[part 1 of 2: packages /CAN2/ISignalGroup to /CAN2/Cluster]
AUTOSAR XML (schema 4-3-0)
package /CAN2/ISignalGroup
  25 x i signal group:
    CAN2_SG_FD_APS1: i-signal=[CAN2_APS_Angle_Target, CAN2_APS_Rq_EPAS_Ctrl, CAN2_APS_Sta_System, CAN2_APS_V_Rq_EPAS_Ctrl], system-signal-group=CAN2_SG_FD_APS1
    CAN2_SG_FD_APS2: i-signal=[CAN2_APS_D_FLL, CAN2_APS_D_FLR, CAN2_APS_D_RLL, CAN2_APS_D_RLR, CAN2_APS_ExitCondition, CAN2_APS_HW_Ver, CAN2_APS_Progress_PCT, CAN2_APS_RQ_Display, CAN2_APS_SW_Ver, CAN2_FDC_VCU_RegenLimInd_Sta, CAN2_FDC_VCU_SmartEcoSpdLim_Sta, CAN2_FDC_VCU_SmartEco_Sta, CAN2_PAS_A_FCL, CAN2_PAS_A_FCR, CAN2_PAS_A_FML, CAN2_PAS_A_FMR, CAN2_PAS_A_RCL, CAN2_PAS_A_RCR, CAN2_PAS_A_RML, CAN2_PAS_A_RMR, CAN2_PAS_Chime, CAN2_PAS_D_FCL, CAN2_PAS_D_FCR, CAN2_PAS_D_FML, CAN2_PAS_D_FMR, CAN2_PAS_D_RCL, CAN2_PAS_D_RCR, CAN2_PAS_D_RML, CAN2_PAS_D_RMR, CAN2_PAS_Mod_Operation, CAN2_PAS_SNSR_Layout, CAN2_PAS_Sta_F_Sys, CAN2_USS_Sta_FCL, CAN2_USS_Sta_FCR, CAN2_USS_Sta_FLL, CAN2_USS_Sta_FLR, CAN2_USS_Sta_FML, CAN2_USS_Sta_FMR, CAN2_USS_Sta_RCL, CAN2_USS_Sta_RCR, CAN2_USS_Sta_RLL, CAN2_USS_Sta_RLR, CAN2_USS_Sta_RML, CAN2_USS_Sta_RMR], system-signal-group=CAN2_SG_FD_APS2
    CAN2_SG_FD_APS3: i-signal=[CAN2_APS3_LifeCount, CAN2_APS3_checksum, CAN2_APSOpenPTG, CAN2_APS_DecReq, CAN2_APS_DecReq_A, CAN2_APS_Req, CAN2_CAAS_Sta, CAN2_SPTGDet, CAN2_SPTG_Sta], system-signal-group=CAN2_SG_FD_APS3
    CAN2_SG_FD_BCM1: i-signal=[CAN2_APMDoorControlSta, CAN2_AllDoorSW, CAN2_AntiTheftSeatFold, CAN2_AntitheftSta, CAN2_BCM_Buzzer_Req, CAN2_BCM_DoorLock_Sta, CAN2_BrakeLamp, CAN2_CTDCtrl, CAN2_CTDLockSW, CAN2_CTDUnlockSW, CAN2_CrashDetd, CAN2_Dimmer, CAN2_DimmerEN, CAN2_DoorLockIND, CAN2_DrDoorSW, CAN2_FDC_BCM_LockAlarm_Cmd, CAN2_FDC_THCM_APTCWarning_Sta, CAN2_FollowMe, CAN2_Fr_ChargingDoorCtrl, CAN2_Fr_FogLamp, CAN2_Fr_Wiper_H, CAN2_Fr_Wiper_L, CAN2_H_Beam, CAN2_HazardSW, CAN2_HoodSW, CAN2_HornCtrl, CAN2_LBSD, CAN2_LDRL, CAN2_LTurnLP, CAN2_L_APM_WdwEnable, CAN2_L_Beam, CAN2_LockSetting, CAN2_MirrorCtrl, CAN2_MirrorDefog, CAN2_PosLamp, CAN2_PsDoorSW, CAN2_RBSD, CAN2_RDRL, CAN2_RLDoorSW, CAN2_RRDoorSW, CAN2_RTurnLP, CAN2_ReverseLamp, CAN2_RoomLampH, CAN2_RoomLampL, CAN2_Rr_ChargingDoorCtrl, CAN2_Rr_Defog, CAN2_Rr_FogLamp, CAN2_Rr_Wiper, CAN2_TailgateHDSW, CAN2_TailgateRemote, CAN2_Tailgate_SW, CAN2_TrunkRel, CAN2_WasherCtrl, CAN2_WiperFixMode], system-signal-group=CAN2_SG_FD_BCM1
    CAN2_SG_FD_BCM2: i-signal=[CAN2_AmbLightBreath1, CAN2_AmbLightBreath2, CAN2_AmbLightBreath3, CAN2_AmbLightBrightness1, CAN2_AmbLightBrightness2, CAN2_AmbLightBrightness3, CAN2_AmbLightColor1, CAN2_AmbLightColor2, CAN2_AmbLightColor3, CAN2_LampPwr, CAN2_User1AmbLightColor, CAN2_User1DrAmbLightBrightness, CAN2_User1IPAmbLightBrightness, CAN2_User2AmbLightColor, CAN2_User2DrAmbLightBrightness, CAN2_User2IPAmbLightBrightness, CAN2_User3AmbLightColor, CAN2_User3DrAmbLightBrightness, CAN2_User3IPAmbLightBrightness, CAN2_User4AmbLightColor, CAN2_User4DrAmbLightBrightness, CAN2_User4IPAmbLightBrightness, CAN2_User5AmbLightColor, CAN2_User5DrAmbLightBrightness, CAN2_User5IPAmbLightBrightness, CAN2_User6AmbLightColor, CAN2_User6DrAmbLightBrightness, CAN2_User6IPAmbLightBrightness], system-signal-group=CAN2_SG_FD_BCM2
    CAN2_SG_FD_OTA1: i-signal=[CAN2_OTA_DL_Available, CAN2_OTA_DL_Speed, CAN2_OTA_Debug_Code, CAN2_OTA_InVehicle_FW, CAN2_OTA_Lock_Req, CAN2_OTA_MDA_Status, CAN2_OTA_Mode, CAN2_OTA_Network_Type, CAN2_OTA_Permit_Agreed, CAN2_OTA_Progress_Rate, CAN2_OTA_Remained_Time, CAN2_OTA_TBOXResetReq, CAN2_OTA_Up_Backcount, CAN2_OTA_Update_Available, CAN2_OTA_Updating_ECU, CAN2_OTA_Updating_ECU_8bit], system-signal-group=CAN2_SG_FD_OTA1
    CAN2_SG_FD_THCM1: i-signal=[CAN2_BatteryMode, CAN2_CCU_ACLampSts, CAN2_CCU_ACMaxLampSts, CAN2_CCU_AutoLampSts, CAN2_CCU_AutoMidLampSts, CAN2_CCU_Dispaly_Request, CAN2_CCU_EcoSts, CAN2_CCU_FrtOnOffLampSts, CAN2_CCU_HEATMaxLampSts, CAN2_CCU_RrOnOffLampSts, CAN2_CCU_SyncLampSts, CAN2_CabinMode, CAN2_EDriveMode, CAN2_FD_AGS_Cmd, CAN2_FD_RecyAuto_Cmd, CAN2_Fr_Coolantflow, CAN2_Fr_Coolanttemp, CAN2_HPThermalRecoveryReq, CAN2_Rr_Coolantflow, CAN2_Rr_Coolanttemp, CAN2_sigAirIntenZon1St, CAN2_sigAirIntenZon3St, CAN2_sigAmbAirT, CAN2_sigCbnAirT, CAN2_sigCbnPTCPwrAct, CAN2_sigCbnSolarLeft, CAN2_sigCbnSolarRight, CAN2_sigClmtCmprPwrAct, CAN2_sigClntTHvBattOut, CAN2_sigDfrstSt, CAN2_sigHvacSt, CAN2_sigRecircSt, CAN2_sigSetTempZon1St, CAN2_sigSetTempZon2St, CAN2_sigSetTempZon3St, CAN2_sigWindDirZon1St, CAN2_sigWindDirZon3St], system-signal-group=CAN2_SG_FD_THCM1
    CAN2_SG_FD_TPMS1: i-signal=[CAN2_AutoLTips, CAN2_CWheelTips, CAN2_LFBatWarn, CAN2_LFPressIndi, CAN2_LFSensorFail, CAN2_LFSensorMode, CAN2_LFWheelDebug, CAN2_LFWheelPSW, CAN2_LFWheelPress, CAN2_LFWheelTemp, CAN2_LFWheelTmpIndi, CAN2_LRBatWarn, CAN2_LRPressIndi, CAN2_LRSensorFail, CAN2_LRSensorMode, CAN2_LRWheelDebug, CAN2_LRWheelPSW, CAN2_LRWheelPress, CAN2_LRWheelTemp, CAN2_LRWheelTmpIndi, CAN2_RFBatWarn, CAN2_RFPressIndi, CAN2_RFSensorFail, CAN2_RFSensorMode, CAN2_RFWheelDebug, CAN2_RFWheelPSW, CAN2_RFWheelPress, CAN2_RFWheelTemp, CAN2_RFWheelTmpIndi, CAN2_RRBatWarn, CAN2_RRPressIndi, CAN2_RRSensorFail, CAN2_RRSensorMode, CAN2_RRWheelDebug, CAN2_RRWheelPSW, CAN2_RRWheelPress, CAN2_RRWheelTemp, CAN2_RRWheelTmpIndi, CAN2_TPMSWarnIndi, CAN2_TPMS_Cali_Butt_Allow, CAN2_TPMS_Res_Butt_Allow], system-signal-group=CAN2_SG_FD_TPMS1
    CAN2_SG_FD_TPMS2: i-signal=[CAN2_ID1_ALTU, CAN2_ID1_Loc_ALTU, CAN2_ID1_message_ALTU, CAN2_ID2_ALTU, CAN2_ID2_Loc_ALTU, CAN2_ID2_message_ALTU, CAN2_ID3_ALTU, CAN2_ID3_Loc_ALTU, CAN2_ID3_message_ALTU, CAN2_ID4_ALTU, CAN2_ID4_Loc_ALTU, CAN2_ID4_message_ALTU, CAN2_IDin_ALTU, CAN2_RF_FAT_ALTU, CAN2_S1WheelDebug_ALTU, CAN2_S2WheelDebug_ALTU, CAN2_S3WheelDebug_ALTU, CAN2_S4WheelDebug_ALTU], system-signal-group=CAN2_SG_FD_TPMS2
    CAN2_SG_FD_V2L1: i-signal=[CAN2_Req_OBCV2LEna, CAN2_Req_V2LSwOn, CAN2_Req_V2L_IVI_Popup], system-signal-group=CAN2_SG_FD_V2L1
    CAN2_SG_FD_VCU0: i-signal=[CAN2_EVCCAplusPwrUpReq, CAN2_FDADC12VDetAvg, CAN2_Fr_TqSource, CAN2_HVRlyOpFail, CAN2_HVTHCMSysAvail, CAN2_LVBattChrgtimeAct, CAN2_LVBattVoltSta, CAN2_LVChrgHoldTAct, CAN2_LVSilentChrgLv, CAN2_LVSilentChrgReq, CAN2_LVSilentChrgSta, CAN2_MCUActDisFail, CAN2_PMMAllowECUSleep, CAN2_PowerDownFault, CAN2_PowerDownState, CAN2_PowerUpFault, CAN2_PowerUpState, CAN2_PwrDownReq, CAN2_PwrStaConstraint, CAN2_PwrStaONTOIVIPopReq, CAN2_PwrStaONTOIVIPopT, CAN2_PwrStaSelect, CAN2_PwrStaTOSta, CAN2_PwrUpReq, CAN2_Rr_TqSource, CAN2_SchedChgTOSta, CAN2_SilentChkAllowSleep, CAN2_SysAllowReadySta, CAN2_SysPwrSta, CAN2_TCountSta, CAN2_TimerAllowSleep, CAN2_VCUBrkSWSta, CAN2_VCUFLDoorSta, CAN2_VCUFRDoorSta, CAN2_VCUHoodSWSta, CAN2_VCURLDoorSta, CAN2_VCURRDoorSta, CAN2_VCUTailgateSWSta, CAN2_VehHVPwrAvail4THCM], system-signal-group=CAN2_SG_FD_VCU0
    CAN2_SG_FD_VCU1: i-signal=[CAN2_ActiveDischReq, CAN2_CC_Crl_Sta, CAN2_CS_VCU1_CAN2, CAN2_CoastDwModeStaChk, CAN2_CreepSW_Sta, CAN2_DCDCEnaReq, CAN2_DCDCVoltSetpoint, CAN2_DemoModeStaChk, CAN2_DisengageP_Fail, CAN2_Dr_SeatSta, CAN2_DynoModeStaChk, CAN2_EngageP_Fail, CAN2_FDC_VCU_PwrSaveReq_Cmd, CAN2_FalseNPrevent_Sta, CAN2_Fr_ActvDmpDisabReq, CAN2_Fr_MCUEnaReq, CAN2_HVBatCnctReq, CAN2_HVSysReadyToCharge, CAN2_LVChrgFuncStaChk, CAN2_MSA_Crl_Sta, CAN2_PrkReq, CAN2_PwrSta, CAN2_RC_VCU1_CAN2, CAN2_Rr_ActvDmpDisabReq, CAN2_Rr_MCUEnaReq, CAN2_ShiftGearPosn, CAN2_VCU_OPDHold, CAN2_XWDMode], system-signal-group=CAN2_SG_FD_VCU1
    CAN2_SG_FD_VCU2: i-signal=[CAN2_ACC_CtrlAvail, CAN2_AccPedal_Override, CAN2_ActAPSPosn, CAN2_CS_VCU2_CAN1, CAN2_DriverTq, CAN2_Fr_DriverTq, CAN2_RC_VCU2_CAN1, CAN2_Rr_DriverTq, CAN2_VehActPwr], system-signal-group=CAN2_SG_FD_VCU2
    CAN2_SG_FD_VCU4: i-signal=[CAN2_EVDriveMode, CAN2_Eng_AGSCloseSta, CAN2_Eng_ActvDmpDisabSta, CAN2_Eng_CoastDwSta, CAN2_Eng_PwrLockSta, CAN2_VCU_ACCErr, CAN2_VCU_ISAErr, CAN2_VehMalfunLevel, CAN2_ZoneDR_SCP_CommErr], system-signal-group=CAN2_SG_FD_VCU4
    CAN2_SG_FD_VCU5: i-signal=[CAN2_EDriveSysErr_AccPedalErr, CAN2_EDriveSysErr_MCUErr, CAN2_EDriveSysErr_ShifterErr, CAN2_EDriveSysErr_VCUErr, CAN2_HVSysErr_IsolationErr, CAN2_HVSysErr_PackErr, CAN2_HVSysErr_RelayErr, CAN2_LVSysErr_PwrOutpErr, CAN2_LimphomeAct, CAN2_LowSOCWarn, CAN2_PwrStaErr, CAN2_Re_VehThdChkSta], system-signal-group=CAN2_SG_FD_VCU5
    CAN2_SG_FD_VCU6: i-signal=[CAN2_FUSION_HW_Ver1, CAN2_FUSION_HW_Ver2, CAN2_FUSION_HW_Ver3, CAN2_FUSION_SW_CarModel1, CAN2_FUSION_SW_CarModel2, CAN2_FUSION_SW_CarModel3, CAN2_FUSION_SW_Controller1, CAN2_FUSION_SW_Controller2, CAN2_FUSION_SW_Country1, CAN2_FUSION_SW_Country2, CAN2_FUSION_SW_Major1, CAN2_FUSION_SW_Major2, CAN2_FUSION_SW_Minor1, CAN2_FUSION_SW_Minor2, CAN2_FUSION_SW_Patch1, CAN2_FUSION_SW_Patch2, CAN2_FUSION_SW_SHA1, CAN2_FUSION_SW_SHA2, CAN2_FUSION_SW_SHA3, CAN2_FUSION_SW_SHA4, CAN2_FUSION_SW_SHA5, CAN2_FUSION_SW_SHA6, CAN2_FUSION_SW_SHA7, CAN2_FUSION_SW_SHA8, CAN2_FUSION_SW_Var, CAN2_FUSION_SW_change1, CAN2_FUSION_SW_change2, CAN2_FUSION_SW_dash1, CAN2_FUSION_SW_dash2], system-signal-group=CAN2_SG_FD_VCU6
    CAN2_SG_FD_VMC1: i-signal=CAN2_CCMSA_SpdWar, system-signal-group=CAN2_SG_FD_VMC1
    CAN2_SG_IVI1: i-signal=[CAN2_AmbLightColorSet, CAN2_AmbLightUserSet, CAN2_BrkAbn_GoReady_SW, CAN2_DRAmbLightBrightnessSet, CAN2_FCP_FrEvt_BtnACMaxReq, CAN2_FCP_FrEvt_BtnACReq, CAN2_FCP_FrEvt_BtnAutoReq, CAN2_FCP_FrEvt_BtnSyncReq, CAN2_FCP_MidEvt_BtnAutoReq, CAN2_IPAmbLightBrightnessSet, CAN2_IVI_Lock_SoundSW_Sta, CAN2_IVI_OTA_Upd_Sta, CAN2_LINKtoDrive, CAN2_OTA_CancelDL_Req, CAN2_OTA_CompNTFY_Pres, CAN2_OTA_DL_Req, CAN2_OTA_SuspendDL_Req, CAN2_OTA_UpdStart_Req, CAN2_OpenDrOpenWdo_SW, CAN2_PW_CLOSE_IMD, CAN2_PW_CONTINUE_USE, CAN2_Sched_OTA_wake, CAN2_SmartEco_Mode_SW, CAN2_Upd_Countdown_Cancel, CAN2_Upd_Countdown_Skip, CAN2_VehACModReq], system-signal-group=CAN2_SG_IVI1
    CAN2_SG_IVI2: i-signal=[CAN2_AC_Chg_Cur_Set, CAN2_AEB_BUTT, CAN2_AVM_Err_STA, CAN2_AVM_OFF_Rec_Butt, CAN2_AVM_Parking_mode, CAN2_AVM_parking_cancel, CAN2_AVM_parking_excute, CAN2_Approach_Unlock_SW, CAN2_BSDMute_BUTT, CAN2_CAAS_Sw, CAN2_CDL_Lock_Butt, CAN2_CDL_Unlock_Butt, CAN2_CameraWrn, CAN2_DSEAT_anti_set, CAN2_DSEAT_entryfun_set, CAN2_DSEAT_vent_req, CAN2_Distance_unit, CAN2_ESC_SW_Cmd, CAN2_FCWMute_BUTT, CAN2_FFogLampSW, CAN2_FS_Off_Sw, CAN2_FalseNPrevent_SW, CAN2_FollowMeSW, CAN2_GPS_LAT, CAN2_GPS_LONG, CAN2_HeadLampSW, CAN2_Hood_Latch_SW, CAN2_IVI_AGSCloseSW, CAN2_IVI_ActvDmpDisabSW, CAN2_IVI_CoastDwSW, CAN2_IVI_CreepSW_Req, CAN2_IVI_ISA_OffsetSpd, CAN2_IVI_LVChrgFuncSW, CAN2_IVI_Mute_Sta, CAN2_IVI_Night_Mode_Sta, CAN2_IVI_PTG_Mode_SW, CAN2_IVI_PTG_Open_Height, CAN2_IVI_PTG_Sta_SW, CAN2_IVI_PTG_USSta_SW, CAN2_IVI_PW_Mode_Req, CAN2_IVI_Panel_Act, CAN2_IVI_Panel_X_Coor, CAN2_IVI_Panel_Y_Coor, CAN2_IVI_PwrLockSW, CAN2_IVI_Pwroff_req, CAN2_IVI_RR_Def_Req, CAN2_IVI_Req_V2L, CAN2_IVI_Screen, CAN2_IVI_Start_Chg_req, CAN2_IVI_Status, CAN2_IVI_Stop_Chg_req, CAN2_IVI_Trigger_req, CAN2_IVI_Unlock_Chg_req, CAN2_IVI_WI_MAIN_SW, CAN2_LDWMute_BUTT, CAN2_LKA_BUTT, CAN2_LVDAMute_BUTT, CAN2_L_Drv_ControlCommand, CAN2_L_Pas_ControlCommand, CAN2_L_RLD_ControlCommand, CAN2_L_RRD_ControlCommand, CAN2_METER_Malfunc_Sta, CAN2_MFRD_N_Bright_Req, CAN2_NAVI_Cam_Dist_info, CAN2_NAVI_Direction_STA, CAN2_NAVI_Distance_info, CAN2_NAVI_ForwardLinkLevel, CAN2_NAVI_LinkClass, CAN2_NAVI_RoadClass, CAN2_NAVI_SpeedLimit, CAN2_NAVI_Speed_Limit_A, CAN2_NAVI_State, CAN2_NAVI_Tollgate, CAN2_NAVI_Tunnel, CAN2_ODAMute_BUTT, CAN2_OFF_AC_MODE, CAN2_PSEAT_vent_req, CAN2_Perd_V2L, CAN2_Pressure_unit, CAN2_RCTA_BUTT, CAN2_RFogLampSW, CAN2_Roll_Eng_Mode, CAN2_Roll_Mode_SW_Cmd, CAN2_RoomLampMode, CAN2_SLG_Sw, CAN2_SLIF_BUTT, CAN2_SOC_ADJ_BUTT, CAN2_SOC_Limit_Set, CAN2_SOC_V2LLimit, CAN2_Sched_Chg_Start, CAN2_Sched_Chg_Stop, CAN2_Sched_Chg_butt, CAN2_Sched_Chg_limit, CAN2_Sched_Chg_wake, CAN2_SenstivityPosition, CAN2_SetUnlockSingle, CAN2_TCS_SW_Cmd, CAN2_TPMS_Cali_Butt, CAN2_TPMS_Res_Butt, CAN2_Temperature_unit, CAN2_Time_system, CAN2_TurnSwTimeSet, CAN2_User_p_download, CAN2_User_p_upload, CAN2_Walkaway_Lock_SW, CAN2_Wifi_Reset, CAN2_Wifi_Sta_IVI_TBOX, CAN2_sigAirIntenZon1Req, CAN2_sigAirIntenZon3Req, CAN2_sigDfrstReq, CAN2_sigFaceReq, CAN2_sigFootReq, CAN2_sigHvacFrontReq, CAN2_sigHvacRearReq, CAN2_sigHvacReq, CAN2_sigRecircReq, CAN2_sigSetTempZon1Req, CAN2_sigSetTempZon2Req, CAN2_sigSetTempZon3Req, CAN2_sigWindDirZon3Req], system-signal-group=CAN2_SG_IVI2
    CAN2_SG_IVI6: i-signal=[CAN2_IVI_Located_STA, CAN2_IVI_Time_Check, CAN2_IVI_Time_Day, CAN2_IVI_Time_Hour, CAN2_IVI_Time_Minute, CAN2_IVI_Time_Month, CAN2_IVI_Time_Second, CAN2_IVI_Time_Year], system-signal-group=CAN2_SG_IVI6
    CAN2_SG_METER1: i-signal=[CAN2_APCforDTE, CAN2_AVGPwrConsumption, CAN2_AvailableTrip, CAN2_Averaged_vehspeed, CAN2_Charge, CAN2_LEDlitWarnReq, CAN2_METER_KPH_Calcu, CAN2_METER_KPH_Real, CAN2_METER_MPH_Calcu, CAN2_METER_MPH_Real, CAN2_ODOMETER, CAN2_ParkBrake, CAN2_Spd_Crl_Mode, CAN2_Spd_Crl_Sta, CAN2_Trip_A, CAN2_Trip_B], system-signal-group=CAN2_SG_METER1
    CAN2_SG_XNMm_FUSION: i-signal=[CAN2_NM_FUSION_Active_WU, CAN2_NM_FUSION_CSB, CAN2_NM_FUSION_ERROR_State, CAN2_NM_FUSION_Node_ID, CAN2_NM_FUSION_PNI, CAN2_NM_FUSION_Rpt_Msg_Req], system-signal-group=CAN2_SG_XNMm_FUSION
    CAN2_SG_XNMm_HMI: i-signal=[CAN2_NM_HMI_Active_WU, CAN2_NM_HMI_CSB, CAN2_NM_HMI_ERROR_State, CAN2_NM_HMI_Node_ID, CAN2_NM_HMI_PNI, CAN2_NM_HMI_Rpt_Msg_Req], system-signal-group=CAN2_SG_XNMm_HMI
    CAN2_SG_XNMm_IVI: i-signal=[CAN2_NM_IVI_Active_WU, CAN2_NM_IVI_CSB, CAN2_NM_IVI_ERROR_State, CAN2_NM_IVI_Node_ID, CAN2_NM_IVI_PNI, CAN2_NM_IVI_Rpt_Msg_Req], system-signal-group=CAN2_SG_XNMm_IVI
    CAN2_SG_XNMm_Telltale: i-signal=[CAN2_NM_Telltale_Active_WU, CAN2_NM_Telltale_CSB, CAN2_NM_Telltale_ERROR_State, CAN2_NM_Telltale_Node_ID, CAN2_NM_Telltale_PNI, CAN2_NM_Telltale_Rpt_Msg_Req], system-signal-group=CAN2_SG_XNMm_Telltale
package /CAN2/Cluster
  can cluster CAN2: baudrate=500, can-fd-baudrate=2000
    can physical channel CAN2: comm-connectors=ConnCAN2
      frame CAN2_DiagFuncReqFT: id 0x7D0, frame-length=8, can-addressing-mode=STANDARD, can-fd-frame-support=true, can-frame-rx-behavior=CAN-FD, can-frame-tx-behavior=CAN-FD
        n pdu CAN2_DiagFuncReqFT: length=8
      frame CAN2_DiagPhysReqToHMI: id 0x6B2, frame-length=8, can-addressing-mode=STANDARD, can-fd-frame-support=true, can-frame-rx-behavior=CAN-FD, can-frame-tx-behavior=CAN-FD
        n pdu CAN2_DiagPhysReqToHMI: length=8
      frame CAN2_DiagPhysReqToIVI: id 0x6A0, frame-length=8, can-addressing-mode=STANDARD, can-fd-frame-support=true, can-frame-rx-behavior=CAN-FD, can-frame-tx-behavior=CAN-FD
        n pdu CAN2_DiagPhysReqToIVI: length=8
      frame CAN2_DiagPhysReqToTelltale: id 0x682, frame-length=8, can-addressing-mode=STANDARD, can-fd-frame-support=true, can-frame-rx-behavior=CAN-FD, can-frame-tx-behavior=CAN-FD
        n pdu CAN2_DiagPhysReqToTelltale: length=8
      frame CAN2_DiagRespFromHMI: id 0x632, frame-length=8, can-addressing-mode=STANDARD, can-fd-frame-support=true, can-frame-rx-behavior=CAN-FD, can-frame-tx-behavior=CAN-FD
        n pdu CAN2_DiagRespFromHMI: length=8
      frame CAN2_DiagRespFromIVI: id 0x620, frame-length=8, can-addressing-mode=STANDARD, can-fd-frame-support=true, can-frame-rx-behavior=CAN-FD, can-frame-tx-behavior=CAN-FD
        n pdu CAN2_DiagRespFromIVI: length=8
      frame CAN2_DiagRespFromTelltale: id 0x602, frame-length=8, can-addressing-mode=STANDARD, can-fd-frame-support=true, can-frame-rx-behavior=CAN-FD, can-frame-tx-behavior=CAN-FD
        n pdu CAN2_DiagRespFromTelltale: length=8
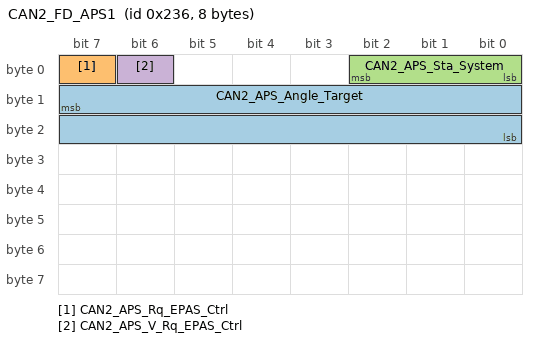
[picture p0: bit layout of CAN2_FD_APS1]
      frame CAN2_FD_APS1: id 0x236, frame-length=8, can-addressing-mode=STANDARD, can-fd-frame-support=true, can-frame-rx-behavior=CAN-FD, can-frame-tx-behavior=CAN-FD
        pdu CAN2_FD_APS1: length=8, minimum-delay=0.0, transmission-mode-true-timing=cyclic-timing=time-period=0.02, unused-bit-pattern=0
          mapping CAN2_SG_FD_APS1: i-signal-group=CAN2_SG_FD_APS1, start-position=0, transfer-property=PENDING
          signal CAN2_APS_Angle_Target: start 15, 16 bit, big-endian, i-signal-type=PRIMITIVE, init-value=constant-reference=Init_CAN2_APS_Angle_Target, base-type=uint16, implementation-data-type=uint16, transfer-property=PENDING
          signal CAN2_APS_Rq_EPAS_Ctrl: start 7, 1 bit, big-endian, i-signal-type=PRIMITIVE, init-value=constant-reference=Init_CAN2_APS_Rq_EPAS_Ctrl, base-type=uint8, implementation-data-type=uint8, transfer-property=PENDING
          signal CAN2_APS_Sta_System: start 2, 3 bit, big-endian, i-signal-type=PRIMITIVE, init-value=constant-reference=Init_CAN2_APS_Sta_System, base-type=uint8, implementation-data-type=uint8, transfer-property=PENDING
          signal CAN2_APS_V_Rq_EPAS_Ctrl: start 6, 1 bit, big-endian, i-signal-type=PRIMITIVE, init-value=constant-reference=Init_CAN2_APS_V_Rq_EPAS_Ctrl, base-type=uint8, implementation-data-type=uint8, transfer-property=PENDING
      frame CAN2_FD_APS2: id 0x210, frame-length=32, can-addressing-mode=STANDARD, can-fd-frame-support=true, can-frame-rx-behavior=CAN-FD, can-frame-tx-behavior=CAN-FD
        pdu CAN2_FD_APS2: length=32, minimum-delay=0.0, transmission-mode-true-timing=cyclic-timing=time-period=0.02, unused-bit-pattern=0
          mapping CAN2_SG_FD_APS2: i-signal-group=CAN2_SG_FD_APS2, start-position=0, transfer-property=PENDING
          signal CAN2_APS_D_FLL: start 49, 10 bit, big-endian, i-signal-type=PRIMITIVE, init-value=constant-reference=Init_CAN2_APS_D_FLL, base-type=uint16, implementation-data-type=uint16, transfer-property=PENDING
          signal CAN2_APS_D_FLR: start 65, 10 bit, big-endian, i-signal-type=PRIMITIVE, init-value=constant-reference=Init_CAN2_APS_D_FLR, base-type=uint16, implementation-data-type=uint16, transfer-property=PENDING
          signal CAN2_APS_D_RLL: start 81, 10 bit, big-endian, i-signal-type=PRIMITIVE, init-value=constant-reference=Init_CAN2_APS_D_RLL, base-type=uint16, implementation-data-type=uint16, transfer-property=PENDING
          signal CAN2_APS_D_RLR: start 97, 10 bit, big-endian, i-signal-type=PRIMITIVE, init-value=constant-reference=Init_CAN2_APS_D_RLR, base-type=uint16, implementation-data-type=uint16, transfer-property=PENDING
          signal CAN2_APS_ExitCondition: start 151, 8 bit, big-endian, i-signal-type=PRIMITIVE, init-value=constant-reference=Init_CAN2_APS_ExitCondition, base-type=uint8, implementation-data-type=uint8, transfer-property=PENDING
          signal CAN2_APS_HW_Ver: start 159, 8 bit, big-endian, i-signal-type=PRIMITIVE, init-value=constant-reference=Init_CAN2_APS_HW_Ver, base-type=uint8, implementation-data-type=uint8, transfer-property=PENDING
          signal CAN2_APS_Progress_PCT: start 215, 8 bit, big-endian, i-signal-type=PRIMITIVE, init-value=constant-reference=Init_CAN2_APS_Progress_PCT, base-type=uint8, implementation-data-type=uint8, transfer-property=PENDING
          signal CAN2_APS_RQ_Display: start 207, 8 bit, big-endian, i-signal-type=PRIMITIVE, init-value=constant-reference=Init_CAN2_APS_RQ_Display, base-type=uint8, implementation-data-type=uint8, transfer-property=PENDING
          signal CAN2_APS_SW_Ver: start 167, 8 bit, big-endian, i-signal-type=PRIMITIVE, init-value=constant-reference=Init_CAN2_APS_SW_Ver, base-type=uint8, implementation-data-type=uint8, transfer-property=PENDING
          signal CAN2_FDC_VCU_RegenLimInd_Sta: start 8, 1 bit, big-endian, i-signal-type=PRIMITIVE, init-value=constant-reference=Init_CAN2_FDC_VCU_RegenLimInd_Sta, base-type=uint8, implementation-data-type=uint8, transfer-property=PENDING
          signal CAN2_FDC_VCU_SmartEcoSpdLim_Sta: start 50, 1 bit, big-endian, i-signal-type=PRIMITIVE, init-value=constant-reference=Init_CAN2_FDC_VCU_SmartEcoSpdLim_Sta, base-type=uint8, implementation-data-type=uint8, transfer-property=PENDING
          signal CAN2_FDC_VCU_SmartEco_Sta: start 51, 1 bit, big-endian, i-signal-type=PRIMITIVE, init-value=constant-reference=Init_CAN2_FDC_VCU_SmartEco_Sta, base-type=uint8, implementation-data-type=uint8, transfer-property=PENDING
          signal CAN2_PAS_A_FCL: start 219, 4 bit, big-endian, i-signal-type=PRIMITIVE, init-value=constant-reference=Init_CAN2_PAS_A_FCL, base-type=uint8, implementation-data-type=uint8, transfer-property=PENDING
          signal CAN2_PAS_A_FCR: start 23, 4 bit, big-endian, i-signal-type=PRIMITIVE, init-value=constant-reference=Init_CAN2_PAS_A_FCR, base-type=uint8, implementation-data-type=uint8, transfer-property=PENDING
          signal CAN2_PAS_A_FML: start 19, 4 bit, big-endian, i-signal-type=PRIMITIVE, init-value=constant-reference=Init_CAN2_PAS_A_FML, base-type=uint8, implementation-data-type=uint8, transfer-property=PENDING
          signal CAN2_PAS_A_FMR: start 31, 4 bit, big-endian, i-signal-type=PRIMITIVE, init-value=constant-reference=Init_CAN2_PAS_A_FMR, base-type=uint8, implementation-data-type=uint8, transfer-property=PENDING
          signal CAN2_PAS_A_RCL: start 27, 4 bit, big-endian, i-signal-type=PRIMITIVE, init-value=constant-reference=Init_CAN2_PAS_A_RCL, base-type=uint8, implementation-data-type=uint8, transfer-property=PENDING
          signal CAN2_PAS_A_RCR: start 39, 4 bit, big-endian, i-signal-type=PRIMITIVE, init-value=constant-reference=Init_CAN2_PAS_A_RCR, base-type=uint8, implementation-data-type=uint8, transfer-property=PENDING
          signal CAN2_PAS_A_RML: start 35, 4 bit, big-endian, i-signal-type=PRIMITIVE, init-value=constant-reference=Init_CAN2_PAS_A_RML, base-type=uint8, implementation-data-type=uint8, transfer-property=PENDING
          signal CAN2_PAS_A_RMR: start 47, 4 bit, big-endian, i-signal-type=PRIMITIVE, init-value=constant-reference=Init_CAN2_PAS_A_RMR, base-type=uint8, implementation-data-type=uint8, transfer-property=PENDING
          signal CAN2_PAS_Chime: start 223, 4 bit, big-endian, i-signal-type=PRIMITIVE, init-value=constant-reference=Init_CAN2_PAS_Chime, base-type=uint8, implementation-data-type=uint8, transfer-property=PENDING
          signal CAN2_PAS_D_FCL: start 119, 8 bit, big-endian, i-signal-type=PRIMITIVE, init-value=constant-reference=Init_CAN2_PAS_D_FCL, base-type=uint8, implementation-data-type=uint8, transfer-property=PENDING
          signal CAN2_PAS_D_FCR: start 127, 8 bit, big-endian, i-signal-type=PRIMITIVE, init-value=constant-reference=Init_CAN2_PAS_D_FCR, base-type=uint8, implementation-data-type=uint8, transfer-property=PENDING
          signal CAN2_PAS_D_FML: start 135, 8 bit, big-endian, i-signal-type=PRIMITIVE, init-value=constant-reference=Init_CAN2_PAS_D_FML, base-type=uint8, implementation-data-type=uint8, transfer-property=PENDING
          signal CAN2_PAS_D_FMR: start 143, 8 bit, big-endian, i-signal-type=PRIMITIVE, init-value=constant-reference=Init_CAN2_PAS_D_FMR, base-type=uint8, implementation-data-type=uint8, transfer-property=PENDING
          signal CAN2_PAS_D_RCL: start 175, 8 bit, big-endian, i-signal-type=PRIMITIVE, init-value=constant-reference=Init_CAN2_PAS_D_RCL, base-type=uint8, implementation-data-type=uint8, transfer-property=PENDING
          signal CAN2_PAS_D_RCR: start 183, 8 bit, big-endian, i-signal-type=PRIMITIVE, init-value=constant-reference=Init_CAN2_PAS_D_RCR, base-type=uint8, implementation-data-type=uint8, transfer-property=PENDING
          signal CAN2_PAS_D_RML: start 191, 8 bit, big-endian, i-signal-type=PRIMITIVE, init-value=constant-reference=Init_CAN2_PAS_D_RML, base-type=uint8, implementation-data-type=uint8, transfer-property=PENDING
          signal CAN2_PAS_D_RMR: start 199, 8 bit, big-endian, i-signal-type=PRIMITIVE, init-value=constant-reference=Init_CAN2_PAS_D_RMR, base-type=uint8, implementation-data-type=uint8, transfer-property=PENDING
          signal CAN2_PAS_Mod_Operation: start 11, 2 bit, big-endian, i-signal-type=PRIMITIVE, init-value=constant-reference=Init_CAN2_PAS_Mod_Operation, base-type=uint8, implementation-data-type=uint8, transfer-property=PENDING
          signal CAN2_PAS_SNSR_Layout: start 43, 4 bit, big-endian, i-signal-type=PRIMITIVE, init-value=constant-reference=Init_CAN2_PAS_SNSR_Layout, base-type=uint8, implementation-data-type=uint8, transfer-property=PENDING
          signal CAN2_PAS_Sta_F_Sys: start 9, 1 bit, big-endian, i-signal-type=PRIMITIVE, init-value=constant-reference=Init_CAN2_PAS_Sta_F_Sys, base-type=uint8, implementation-data-type=uint8, transfer-property=PENDING
          signal CAN2_USS_Sta_FCL: start 7, 1 bit, big-endian, i-signal-type=PRIMITIVE, init-value=constant-reference=Init_CAN2_USS_Sta_FCL, base-type=uint8, implementation-data-type=uint8, transfer-property=PENDING
          signal CAN2_USS_Sta_FCR: start 6, 1 bit, big-endian, i-signal-type=PRIMITIVE, init-value=constant-reference=Init_CAN2_USS_Sta_FCR, base-type=uint8, implementation-data-type=uint8, transfer-property=PENDING
          signal CAN2_USS_Sta_FLL: start 5, 1 bit, big-endian, i-signal-type=PRIMITIVE, init-value=constant-reference=Init_CAN2_USS_Sta_FLL, base-type=uint8, implementation-data-type=uint8, transfer-property=PENDING
          signal CAN2_USS_Sta_FLR: start 4, 1 bit, big-endian, i-signal-type=PRIMITIVE, init-value=constant-reference=Init_CAN2_USS_Sta_FLR, base-type=uint8, implementation-data-type=uint8, transfer-property=PENDING
          signal CAN2_USS_Sta_FML: start 3, 1 bit, big-endian, i-signal-type=PRIMITIVE, init-value=constant-reference=Init_CAN2_USS_Sta_FML, base-type=uint8, implementation-data-type=uint8, transfer-property=PENDING
          signal CAN2_USS_Sta_FMR: start 2, 1 bit, big-endian, i-signal-type=PRIMITIVE, init-value=constant-reference=Init_CAN2_USS_Sta_FMR, base-type=uint8, implementation-data-type=uint8, transfer-property=PENDING
          signal CAN2_USS_Sta_RCL: start 1, 1 bit, big-endian, i-signal-type=PRIMITIVE, init-value=constant-reference=Init_CAN2_USS_Sta_RCL, base-type=uint8, implementation-data-type=uint8, transfer-property=PENDING
          signal CAN2_USS_Sta_RCR: start 0, 1 bit, big-endian, i-signal-type=PRIMITIVE, init-value=constant-reference=Init_CAN2_USS_Sta_RCR, base-type=uint8, implementation-data-type=uint8, transfer-property=PENDING
          signal CAN2_USS_Sta_RLL: start 15, 1 bit, big-endian, i-signal-type=PRIMITIVE, init-value=constant-reference=Init_CAN2_USS_Sta_RLL, base-type=uint8, implementation-data-type=uint8, transfer-property=PENDING
          signal CAN2_USS_Sta_RLR: start 14, 1 bit, big-endian, i-signal-type=PRIMITIVE, init-value=constant-reference=Init_CAN2_USS_Sta_RLR, base-type=uint8, implementation-data-type=uint8, transfer-property=PENDING
          signal CAN2_USS_Sta_RML: start 13, 1 bit, big-endian, i-signal-type=PRIMITIVE, init-value=constant-reference=Init_CAN2_USS_Sta_RML, base-type=uint8, implementation-data-type=uint8, transfer-property=PENDING
          signal CAN2_USS_Sta_RMR: start 12, 1 bit, big-endian, i-signal-type=PRIMITIVE, init-value=constant-reference=Init_CAN2_USS_Sta_RMR, base-type=uint8, implementation-data-type=uint8, transfer-property=PENDING
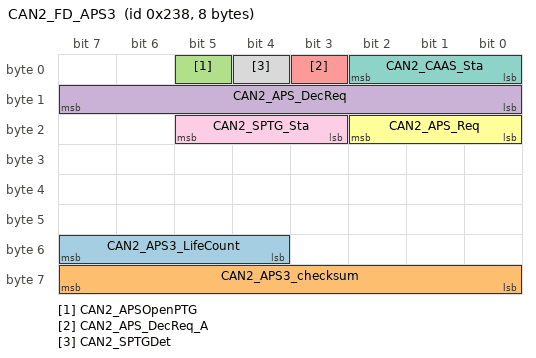
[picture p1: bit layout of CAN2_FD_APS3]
      frame CAN2_FD_APS3: id 0x238, frame-length=8, can-addressing-mode=STANDARD, can-fd-frame-support=true, can-frame-rx-behavior=CAN-FD, can-frame-tx-behavior=CAN-FD
        pdu CAN2_FD_APS3: length=8, minimum-delay=0.0, transmission-mode-true-timing=cyclic-timing=time-period=0.01, unused-bit-pattern=0
          mapping CAN2_SG_FD_APS3: i-signal-group=CAN2_SG_FD_APS3, start-position=0, transfer-property=PENDING
          signal CAN2_APS3_LifeCount: start 55, 4 bit, big-endian, i-signal-type=PRIMITIVE, init-value=constant-reference=Init_CAN2_APS3_LifeCount, base-type=uint8, implementation-data-type=uint8, transfer-property=PENDING
          signal CAN2_APS3_checksum: start 63, 8 bit, big-endian, i-signal-type=PRIMITIVE, init-value=constant-reference=Init_CAN2_APS3_checksum, base-type=uint8, implementation-data-type=uint8, transfer-property=PENDING
          signal CAN2_APSOpenPTG: start 5, 1 bit, big-endian, i-signal-type=PRIMITIVE, init-value=constant-reference=Init_CAN2_APSOpenPTG, base-type=uint8, implementation-data-type=uint8, transfer-property=PENDING
          signal CAN2_APS_DecReq: start 15, 8 bit, big-endian, i-signal-type=PRIMITIVE, init-value=constant-reference=Init_CAN2_APS_DecReq, base-type=uint8, implementation-data-type=uint8, transfer-property=PENDING
          signal CAN2_APS_DecReq_A: start 3, 1 bit, big-endian, i-signal-type=PRIMITIVE, init-value=constant-reference=Init_CAN2_APS_DecReq_A, base-type=uint8, implementation-data-type=uint8, transfer-property=PENDING
          signal CAN2_APS_Req: start 18, 3 bit, big-endian, i-signal-type=PRIMITIVE, init-value=constant-reference=Init_CAN2_APS_Req, base-type=uint8, implementation-data-type=uint8, transfer-property=PENDING
          signal CAN2_CAAS_Sta: start 2, 3 bit, big-endian, i-signal-type=PRIMITIVE, init-value=constant-reference=Init_CAN2_CAAS_Sta, base-type=uint8, implementation-data-type=uint8, transfer-property=PENDING
          signal CAN2_SPTGDet: start 4, 1 bit, big-endian, i-signal-type=PRIMITIVE, init-value=constant-reference=Init_CAN2_SPTGDet, base-type=uint8, implementation-data-type=uint8, transfer-property=PENDING
          signal CAN2_SPTG_Sta: start 21, 3 bit, big-endian, i-signal-type=PRIMITIVE, init-value=constant-reference=Init_CAN2_SPTG_Sta, base-type=uint8, implementation-data-type=uint8, transfer-property=PENDING
      frame CAN2_FD_BCM1: id 0x216, frame-length=16, can-addressing-mode=STANDARD, can-fd-frame-support=true, can-frame-rx-behavior=CAN-FD, can-frame-tx-behavior=CAN-FD
        pdu CAN2_FD_BCM1: length=16, minimum-delay=0.0, transmission-mode-true-timing={cyclic-timing=time-period=0.2, event-controlled-timing={number-of-repetitions=0, repetition-period=0.06}}, unused-bit-pattern=0
          mapping CAN2_SG_FD_BCM1: i-signal-group=CAN2_SG_FD_BCM1, start-position=0, transfer-property=TRIGGERED-ON-CHANGE
          signal CAN2_APMDoorControlSta: start 63, 1 bit, big-endian, i-signal-type=PRIMITIVE, init-value=constant-reference=Init_CAN2_APMDoorControlSta, base-type=uint8, implementation-data-type=uint8, transfer-property=TRIGGERED-ON-CHANGE
          signal CAN2_AllDoorSW: start 124, 1 bit, big-endian, i-signal-type=PRIMITIVE, init-value=constant-reference=Init_CAN2_AllDoorSW, base-type=uint8, implementation-data-type=uint8, transfer-property=TRIGGERED-ON-CHANGE
          signal CAN2_AntiTheftSeatFold: start 84, 1 bit, big-endian, i-signal-type=PRIMITIVE, init-value=constant-reference=Init_CAN2_AntiTheftSeatFold, base-type=uint8, implementation-data-type=uint8, transfer-property=TRIGGERED-ON-CHANGE
          signal CAN2_AntitheftSta: start 83, 2 bit, big-endian, i-signal-type=PRIMITIVE, init-value=constant-reference=Init_CAN2_AntitheftSta, base-type=uint8, implementation-data-type=uint8, transfer-property=TRIGGERED-ON-CHANGE
          signal CAN2_BCM_Buzzer_Req: start 64, 1 bit, big-endian, i-signal-type=PRIMITIVE, init-value=constant-reference=Init_CAN2_BCM_Buzzer_Req, base-type=uint8, implementation-data-type=uint8, transfer-property=TRIGGERED-ON-CHANGE
          signal CAN2_BCM_DoorLock_Sta: start 70, 1 bit, big-endian, i-signal-type=PRIMITIVE, init-value=constant-reference=Init_CAN2_BCM_DoorLock_Sta, base-type=uint8, implementation-data-type=uint8, transfer-property=TRIGGERED-ON-CHANGE
          signal CAN2_BrakeLamp: start 90, 1 bit, big-endian, i-signal-type=PRIMITIVE, init-value=constant-reference=Init_CAN2_BrakeLamp, base-type=uint8, implementation-data-type=uint8, transfer-property=TRIGGERED-ON-CHANGE
          signal CAN2_CTDCtrl: start 113, 2 bit, big-endian, i-signal-type=PRIMITIVE, init-value=constant-reference=Init_CAN2_CTDCtrl, base-type=uint8, implementation-data-type=uint8, transfer-property=TRIGGERED-ON-CHANGE
          signal CAN2_CTDLockSW: start 118, 1 bit, big-endian, i-signal-type=PRIMITIVE, init-value=constant-reference=Init_CAN2_CTDLockSW, base-type=uint8, implementation-data-type=uint8, transfer-property=TRIGGERED-ON-CHANGE
          signal CAN2_CTDUnlockSW: start 119, 1 bit, big-endian, i-signal-type=PRIMITIVE, init-value=constant-reference=Init_CAN2_CTDUnlockSW, base-type=uint8, implementation-data-type=uint8, transfer-property=TRIGGERED-ON-CHANGE
          signal CAN2_CrashDetd: start 85, 1 bit, big-endian, i-signal-type=PRIMITIVE, init-value=constant-reference=Init_CAN2_CrashDetd, base-type=uint8, implementation-data-type=uint8, transfer-property=TRIGGERED-ON-CHANGE
          signal CAN2_Dimmer: start 78, 7 bit, big-endian, i-signal-type=PRIMITIVE, init-value=constant-reference=Init_CAN2_Dimmer, base-type=uint8, implementation-data-type=uint8, transfer-property=TRIGGERED-ON-CHANGE
          signal CAN2_DimmerEN: start 69, 1 bit, big-endian, i-signal-type=PRIMITIVE, init-value=constant-reference=Init_CAN2_DimmerEN, base-type=uint8, implementation-data-type=uint8, transfer-property=TRIGGERED-ON-CHANGE
          signal CAN2_DoorLockIND: start 125, 1 bit, big-endian, i-signal-type=PRIMITIVE, init-value=constant-reference=Init_CAN2_DoorLockIND, base-type=uint8, implementation-data-type=uint8, transfer-property=TRIGGERED-ON-CHANGE
          signal CAN2_DrDoorSW: start 120, 1 bit, big-endian, i-signal-type=PRIMITIVE, init-value=constant-reference=Init_CAN2_DrDoorSW, base-type=uint8, implementation-data-type=uint8, transfer-property=TRIGGERED-ON-CHANGE
          signal CAN2_FDC_BCM_LockAlarm_Cmd: start 62, 2 bit, big-endian, i-signal-type=PRIMITIVE, init-value=constant-reference=Init_CAN2_FDC_BCM_LockAlarm_Cmd, base-type=uint8, implementation-data-type=uint8, transfer-property=TRIGGERED-ON-CHANGE
          signal CAN2_FDC_THCM_APTCWarning_Sta: start 60, 1 bit, big-endian, i-signal-type=PRIMITIVE, init-value=constant-reference=Init_CAN2_FDC_THCM_APTCWarning_Sta, base-type=uint8, implementation-data-type=uint8, transfer-property=TRIGGERED-ON-CHANGE
          signal CAN2_FollowMe: start 86, 1 bit, big-endian, i-signal-type=PRIMITIVE, init-value=constant-reference=Init_CAN2_FollowMe, base-type=uint8, implementation-data-type=uint8, transfer-property=PENDING
          signal CAN2_Fr_ChargingDoorCtrl: start 115, 2 bit, big-endian, i-signal-type=PRIMITIVE, init-value=constant-reference=Init_CAN2_Fr_ChargingDoorCtrl, base-type=uint8, implementation-data-type=uint8, transfer-property=TRIGGERED-ON-CHANGE
          signal CAN2_Fr_FogLamp: start 93, 1 bit, big-endian, i-signal-type=PRIMITIVE, init-value=constant-reference=Init_CAN2_Fr_FogLamp, base-type=uint8, implementation-data-type=uint8, transfer-property=TRIGGERED-ON-CHANGE
          signal CAN2_Fr_Wiper_H: start 110, 1 bit, big-endian, i-signal-type=PRIMITIVE, init-value=constant-reference=Init_CAN2_Fr_Wiper_H, base-type=uint8, implementation-data-type=uint8, transfer-property=TRIGGERED-ON-CHANGE
          signal CAN2_Fr_Wiper_L: start 111, 1 bit, big-endian, i-signal-type=PRIMITIVE, init-value=constant-reference=Init_CAN2_Fr_Wiper_L, base-type=uint8, implementation-data-type=uint8, transfer-property=TRIGGERED-ON-CHANGE
          signal CAN2_H_Beam: start 101, 1 bit, big-endian, i-signal-type=PRIMITIVE, init-value=constant-reference=Init_CAN2_H_Beam, base-type=uint8, implementation-data-type=uint8, transfer-property=TRIGGERED-ON-CHANGE
          signal CAN2_HazardSW: start 95, 1 bit, big-endian, i-signal-type=PRIMITIVE, init-value=constant-reference=Init_CAN2_HazardSW, base-type=uint8, implementation-data-type=uint8, transfer-property=TRIGGERED-ON-CHANGE
          signal CAN2_HoodSW: start 126, 1 bit, big-endian, i-signal-type=PRIMITIVE, init-value=constant-reference=Init_CAN2_HoodSW, base-type=uint8, implementation-data-type=uint8, transfer-property=TRIGGERED-ON-CHANGE
          signal CAN2_HornCtrl: start 71, 1 bit, big-endian, i-signal-type=PRIMITIVE, init-value=constant-reference=Init_CAN2_HornCtrl, base-type=uint8, implementation-data-type=uint8, transfer-property=TRIGGERED-ON-CHANGE
          signal CAN2_LBSD: start 91, 1 bit, big-endian, i-signal-type=PRIMITIVE, init-value=constant-reference=Init_CAN2_LBSD, base-type=uint8, implementation-data-type=uint8, transfer-property=TRIGGERED-ON-CHANGE
          signal CAN2_LDRL: start 103, 1 bit, big-endian, i-signal-type=PRIMITIVE, init-value=constant-reference=Init_CAN2_LDRL, base-type=uint8, implementation-data-type=uint8, transfer-property=TRIGGERED-ON-CHANGE
          signal CAN2_LTurnLP: start 80, 1 bit, big-endian, i-signal-type=PRIMITIVE, init-value=constant-reference=Init_CAN2_LTurnLP, base-type=uint8, implementation-data-type=uint8, transfer-property=TRIGGERED-ON-CHANGE
          signal CAN2_L_APM_WdwEnable: start 87, 1 bit, big-endian, i-signal-type=PRIMITIVE, init-value=constant-reference=Init_CAN2_L_APM_WdwEnable, base-type=uint8, implementation-data-type=uint8, transfer-property=TRIGGERED-ON-CHANGE
          signal CAN2_L_Beam: start 100, 1 bit, big-endian, i-signal-type=PRIMITIVE, init-value=constant-reference=Init_CAN2_L_Beam, base-type=uint8, implementation-data-type=uint8, transfer-property=TRIGGERED-ON-CHANGE
          signal CAN2_LockSetting: start 79, 1 bit, big-endian, i-signal-type=PRIMITIVE, init-value=constant-reference=Init_CAN2_LockSetting, base-type=uint8, implementation-data-type=uint8, transfer-property=TRIGGERED-ON-CHANGE
          signal CAN2_MirrorCtrl: start 109, 2 bit, big-endian, i-signal-type=PRIMITIVE, init-value=constant-reference=Init_CAN2_MirrorCtrl, base-type=uint8, implementation-data-type=uint8, transfer-property=TRIGGERED-ON-CHANGE
          signal CAN2_MirrorDefog: start 104, 1 bit, big-endian, i-signal-type=PRIMITIVE, init-value=constant-reference=Init_CAN2_MirrorDefog, base-type=uint8, implementation-data-type=uint8, transfer-property=TRIGGERED-ON-CHANGE
          signal CAN2_PosLamp: start 102, 1 bit, big-endian, i-signal-type=PRIMITIVE, init-value=constant-reference=Init_CAN2_PosLamp, base-type=uint8, implementation-data-type=uint8, transfer-property=TRIGGERED-ON-CHANGE
          signal CAN2_PsDoorSW: start 121, 1 bit, big-endian, i-signal-type=PRIMITIVE, init-value=constant-reference=Init_CAN2_PsDoorSW, base-type=uint8, implementation-data-type=uint8, transfer-property=TRIGGERED-ON-CHANGE
          signal CAN2_RBSD: start 92, 1 bit, big-endian, i-signal-type=PRIMITIVE, init-value=constant-reference=Init_CAN2_RBSD, base-type=uint8, implementation-data-type=uint8, transfer-property=TRIGGERED-ON-CHANGE
          signal CAN2_RDRL: start 88, 1 bit, big-endian, i-signal-type=PRIMITIVE, init-value=constant-reference=Init_CAN2_RDRL, base-type=uint8, implementation-data-type=uint8, transfer-property=TRIGGERED-ON-CHANGE
          signal CAN2_RLDoorSW: start 122, 1 bit, big-endian, i-signal-type=PRIMITIVE, init-value=constant-reference=Init_CAN2_RLDoorSW, base-type=uint8, implementation-data-type=uint8, transfer-property=TRIGGERED-ON-CHANGE
          signal CAN2_RRDoorSW: start 123, 1 bit, big-endian, i-signal-type=PRIMITIVE, init-value=constant-reference=Init_CAN2_RRDoorSW, base-type=uint8, implementation-data-type=uint8, transfer-property=TRIGGERED-ON-CHANGE
          signal CAN2_RTurnLP: start 81, 1 bit, big-endian, i-signal-type=PRIMITIVE, init-value=constant-reference=Init_CAN2_RTurnLP, base-type=uint8, implementation-data-type=uint8, transfer-property=TRIGGERED-ON-CHANGE
          signal CAN2_ReverseLamp: start 89, 1 bit, big-endian, i-signal-type=PRIMITIVE, init-value=constant-reference=Init_CAN2_ReverseLamp, base-type=uint8, implementation-data-type=uint8, transfer-property=TRIGGERED-ON-CHANGE
          signal CAN2_RoomLampH: start 68, 1 bit, big-endian, i-signal-type=PRIMITIVE, init-value=constant-reference=Init_CAN2_RoomLampH, base-type=uint8, implementation-data-type=uint8, transfer-property=TRIGGERED-ON-CHANGE
          signal CAN2_RoomLampL: start 67, 1 bit, big-endian, i-signal-type=PRIMITIVE, init-value=constant-reference=Init_CAN2_RoomLampL, base-type=uint8, implementation-data-type=uint8, transfer-property=TRIGGERED-ON-CHANGE
          signal CAN2_Rr_ChargingDoorCtrl: start 117, 2 bit, big-endian, i-signal-type=PRIMITIVE, init-value=constant-reference=Init_CAN2_Rr_ChargingDoorCtrl, base-type=uint8, implementation-data-type=uint8, transfer-property=TRIGGERED-ON-CHANGE
          signal CAN2_Rr_Defog: start 105, 1 bit, big-endian, i-signal-type=PRIMITIVE, init-value=constant-reference=Init_CAN2_Rr_Defog, base-type=uint8, implementation-data-type=uint8, transfer-property=TRIGGERED-ON-CHANGE
          signal CAN2_Rr_FogLamp: start 94, 1 bit, big-endian, i-signal-type=PRIMITIVE, init-value=constant-reference=Init_CAN2_Rr_FogLamp, base-type=uint8, implementation-data-type=uint8, transfer-property=TRIGGERED-ON-CHANGE
          signal CAN2_Rr_Wiper: start 96, 1 bit, big-endian, i-signal-type=PRIMITIVE, init-value=constant-reference=Init_CAN2_Rr_Wiper, base-type=uint8, implementation-data-type=uint8, transfer-property=TRIGGERED-ON-CHANGE
          signal CAN2_TailgateHDSW: start 107, 1 bit, big-endian, i-signal-type=PRIMITIVE, init-value=constant-reference=Init_CAN2_TailgateHDSW, base-type=uint8, implementation-data-type=uint8, transfer-property=TRIGGERED-ON-CHANGE
          signal CAN2_TailgateRemote: start 66, 2 bit, big-endian, i-signal-type=PRIMITIVE, init-value=constant-reference=Init_CAN2_TailgateRemote, base-type=uint8, implementation-data-type=uint8, transfer-property=TRIGGERED-ON-CHANGE
          signal CAN2_Tailgate_SW: start 127, 1 bit, big-endian, i-signal-type=PRIMITIVE, init-value=constant-reference=Init_CAN2_Tailgate_SW, base-type=uint8, implementation-data-type=uint8, transfer-property=TRIGGERED-ON-CHANGE
          signal CAN2_TrunkRel: start 106, 1 bit, big-endian, i-signal-type=PRIMITIVE, init-value=constant-reference=Init_CAN2_TrunkRel, base-type=uint8, implementation-data-type=uint8, transfer-property=TRIGGERED-ON-CHANGE
          signal CAN2_WasherCtrl: start 99, 2 bit, big-endian, i-signal-type=PRIMITIVE, init-value=constant-reference=Init_CAN2_WasherCtrl, base-type=uint8, implementation-data-type=uint8, transfer-property=TRIGGERED-ON-CHANGE
          signal CAN2_WiperFixMode: start 97, 1 bit, big-endian, i-signal-type=PRIMITIVE, init-value=constant-reference=Init_CAN2_WiperFixMode, base-type=uint8, implementation-data-type=uint8, transfer-property=TRIGGERED-ON-CHANGE
      frame CAN2_FD_BCM2: id 0x217, frame-length=24, can-addressing-mode=STANDARD, can-fd-frame-support=true, can-frame-rx-behavior=CAN-FD, can-frame-tx-behavior=CAN-FD
        pdu CAN2_FD_BCM2: length=24, minimum-delay=0.0, transmission-mode-true-timing={cyclic-timing=time-period=0.2, event-controlled-timing={number-of-repetitions=0, repetition-period=0.01}}, unused-bit-pattern=0
          mapping CAN2_SG_FD_BCM2: i-signal-group=CAN2_SG_FD_BCM2, start-position=0, transfer-property=TRIGGERED-ON-CHANGE
          signal CAN2_AmbLightBreath1: start 23, 1 bit, big-endian, i-signal-type=PRIMITIVE, init-value=constant-reference=Init_CAN2_AmbLightBreath1, base-type=uint8, implementation-data-type=uint8, transfer-property=TRIGGERED-ON-CHANGE
          signal CAN2_AmbLightBreath2: start 15, 1 bit, big-endian, i-signal-type=PRIMITIVE, init-value=constant-reference=Init_CAN2_AmbLightBreath2, base-type=uint8, implementation-data-type=uint8, transfer-property=TRIGGERED-ON-CHANGE
          signal CAN2_AmbLightBreath3: start 7, 1 bit, big-endian, i-signal-type=PRIMITIVE, init-value=constant-reference=Init_CAN2_AmbLightBreath3, base-type=uint8, implementation-data-type=uint8, transfer-property=TRIGGERED-ON-CHANGE
          signal CAN2_AmbLightBrightness1: start 190, 7 bit, big-endian, i-signal-type=PRIMITIVE, init-value=constant-reference=Init_CAN2_AmbLightBrightness1, base-type=uint8, implementation-data-type=uint8, transfer-property=TRIGGERED-ON-CHANGE
          signal CAN2_AmbLightBrightness2: start 182, 7 bit, big-endian, i-signal-type=PRIMITIVE, init-value=constant-reference=Init_CAN2_AmbLightBrightness2, base-type=uint8, implementation-data-type=uint8, transfer-property=TRIGGERED-ON-CHANGE
          signal CAN2_AmbLightBrightness3: start 174, 7 bit, big-endian, i-signal-type=PRIMITIVE, init-value=constant-reference=Init_CAN2_AmbLightBrightness3, base-type=uint8, implementation-data-type=uint8, transfer-property=TRIGGERED-ON-CHANGE
          signal CAN2_AmbLightColor1: start 165, 6 bit, big-endian, i-signal-type=PRIMITIVE, init-value=constant-reference=Init_CAN2_AmbLightColor1, base-type=uint8, implementation-data-type=uint8, transfer-property=TRIGGERED-ON-CHANGE
          signal CAN2_AmbLightColor2: start 157, 6 bit, big-endian, i-signal-type=PRIMITIVE, init-value=constant-reference=Init_CAN2_AmbLightColor2, base-type=uint8, implementation-data-type=uint8, transfer-property=TRIGGERED-ON-CHANGE
          signal CAN2_AmbLightColor3: start 149, 6 bit, big-endian, i-signal-type=PRIMITIVE, init-value=constant-reference=Init_CAN2_AmbLightColor3, base-type=uint8, implementation-data-type=uint8, transfer-property=TRIGGERED-ON-CHANGE
          signal CAN2_LampPwr: start 31, 1 bit, big-endian, i-signal-type=PRIMITIVE, init-value=constant-reference=Init_CAN2_LampPwr, base-type=uint8, implementation-data-type=uint8, transfer-property=TRIGGERED-ON-CHANGE
          signal CAN2_User1AmbLightColor: start 141, 6 bit, big-endian, i-signal-type=PRIMITIVE, init-value=constant-reference=Init_CAN2_User1AmbLightColor, base-type=uint8, implementation-data-type=uint8, transfer-property=TRIGGERED-ON-CHANGE
          signal CAN2_User1DrAmbLightBrightness: start 46, 7 bit, big-endian, i-signal-type=PRIMITIVE, init-value=constant-reference=Init_CAN2_User1DrAmbLightBrightness, base-type=uint8, implementation-data-type=uint8, transfer-property=TRIGGERED-ON-CHANGE
          signal CAN2_User1IPAmbLightBrightness: start 94, 7 bit, big-endian, i-signal-type=PRIMITIVE, init-value=constant-reference=Init_CAN2_User1IPAmbLightBrightness, base-type=uint8, implementation-data-type=uint8, transfer-property=TRIGGERED-ON-CHANGE
          signal CAN2_User2AmbLightColor: start 133, 6 bit, big-endian, i-signal-type=PRIMITIVE, init-value=constant-reference=Init_CAN2_User2AmbLightColor, base-type=uint8, implementation-data-type=uint8, transfer-property=TRIGGERED-ON-CHANGE
          signal CAN2_User2DrAmbLightBrightness: start 38, 7 bit, big-endian, i-signal-type=PRIMITIVE, init-value=constant-reference=Init_CAN2_User2DrAmbLightBrightness, base-type=uint8, implementation-data-type=uint8, transfer-property=TRIGGERED-ON-CHANGE
          signal CAN2_User2IPAmbLightBrightness: start 86, 7 bit, big-endian, i-signal-type=PRIMITIVE, init-value=constant-reference=Init_CAN2_User2IPAmbLightBrightness, base-type=uint8, implementation-data-type=uint8, transfer-property=TRIGGERED-ON-CHANGE
          signal CAN2_User3AmbLightColor: start 125, 6 bit, big-endian, i-signal-type=PRIMITIVE, init-value=constant-reference=Init_CAN2_User3AmbLightColor, base-type=uint8, implementation-data-type=uint8, transfer-property=TRIGGERED-ON-CHANGE
          signal CAN2_User3DrAmbLightBrightness: start 30, 7 bit, big-endian, i-signal-type=PRIMITIVE, init-value=constant-reference=Init_CAN2_User3DrAmbLightBrightness, base-type=uint8, implementation-data-type=uint8, transfer-property=TRIGGERED-ON-CHANGE
          signal CAN2_User3IPAmbLightBrightness: start 78, 7 bit, big-endian, i-signal-type=PRIMITIVE, init-value=constant-reference=Init_CAN2_User3IPAmbLightBrightness, base-type=uint8, implementation-data-type=uint8, transfer-property=TRIGGERED-ON-CHANGE
          signal CAN2_User4AmbLightColor: start 117, 6 bit, big-endian, i-signal-type=PRIMITIVE, init-value=constant-reference=Init_CAN2_User4AmbLightColor, base-type=uint8, implementation-data-type=uint8, transfer-property=TRIGGERED-ON-CHANGE
          signal CAN2_User4DrAmbLightBrightness: start 22, 7 bit, big-endian, i-signal-type=PRIMITIVE, init-value=constant-reference=Init_CAN2_User4DrAmbLightBrightness, base-type=uint8, implementation-data-type=uint8, transfer-property=TRIGGERED-ON-CHANGE
          signal CAN2_User4IPAmbLightBrightness: start 70, 7 bit, big-endian, i-signal-type=PRIMITIVE, init-value=constant-reference=Init_CAN2_User4IPAmbLightBrightness, base-type=uint8, implementation-data-type=uint8, transfer-property=TRIGGERED-ON-CHANGE
          signal CAN2_User5AmbLightColor: start 109, 6 bit, big-endian, i-signal-type=PRIMITIVE, init-value=constant-reference=Init_CAN2_User5AmbLightColor, base-type=uint8, implementation-data-type=uint8, transfer-property=TRIGGERED-ON-CHANGE
          signal CAN2_User5DrAmbLightBrightness: start 14, 7 bit, big-endian, i-signal-type=PRIMITIVE, init-value=constant-reference=Init_CAN2_User5DrAmbLightBrightness, base-type=uint8, implementation-data-type=uint8, transfer-property=TRIGGERED-ON-CHANGE
          signal CAN2_User5IPAmbLightBrightness: start 62, 7 bit, big-endian, i-signal-type=PRIMITIVE, init-value=constant-reference=Init_CAN2_User5IPAmbLightBrightness, base-type=uint8, implementation-data-type=uint8, transfer-property=TRIGGERED-ON-CHANGE
          signal CAN2_User6AmbLightColor: start 101, 6 bit, big-endian, i-signal-type=PRIMITIVE, init-value=constant-reference=Init_CAN2_User6AmbLightColor, base-type=uint8, implementation-data-type=uint8, transfer-property=TRIGGERED-ON-CHANGE
          signal CAN2_User6DrAmbLightBrightness: start 6, 7 bit, big-endian, i-signal-type=PRIMITIVE, init-value=constant-reference=Init_CAN2_User6DrAmbLightBrightness, base-type=uint8, implementation-data-type=uint8, transfer-property=TRIGGERED-ON-CHANGE
          signal CAN2_User6IPAmbLightBrightness: start 54, 7 bit, big-endian, i-signal-type=PRIMITIVE, init-value=constant-reference=Init_CAN2_User6IPAmbLightBrightness, base-type=uint8, implementation-data-type=uint8, transfer-property=TRIGGERED-ON-CHANGE
      frame CAN2_FD_OTA1: id 0x438, frame-length=12, can-addressing-mode=STANDARD, can-fd-frame-support=true, can-frame-rx-behavior=CAN-FD, can-frame-tx-behavior=CAN-FD
        pdu CAN2_FD_OTA1: length=12, minimum-delay=0.0, transmission-mode-true-timing={cyclic-timing=time-period=0.2, event-controlled-timing={number-of-repetitions=0, repetition-period=0.02}}, unused-bit-pattern=0
          mapping CAN2_SG_FD_OTA1: i-signal-group=CAN2_SG_FD_OTA1, start-position=0, transfer-property=TRIGGERED-ON-CHANGE
          signal CAN2_OTA_DL_Available: start 8, 1 bit, big-endian, i-signal-type=PRIMITIVE, init-value=constant-reference=Init_CAN2_OTA_DL_Available, base-type=uint8, implementation-data-type=uint8, transfer-property=TRIGGERED-ON-CHANGE
          signal CAN2_OTA_DL_Speed: start 27, 20 bit, big-endian, i-signal-type=PRIMITIVE, init-value=constant-reference=Init_CAN2_OTA_DL_Speed, base-type=uint32, implementation-data-type=uint32, transfer-property=TRIGGERED-ON-CHANGE
          signal CAN2_OTA_Debug_Code: start 79, 8 bit, big-endian, i-signal-type=PRIMITIVE, init-value=constant-reference=Init_CAN2_OTA_Debug_Code, base-type=uint8, implementation-data-type=uint8, transfer-property=PENDING
          signal CAN2_OTA_InVehicle_FW: start 23, 2 bit, big-endian, i-signal-type=PRIMITIVE, init-value=constant-reference=Init_CAN2_OTA_InVehicle_FW, base-type=uint8, implementation-data-type=uint8, transfer-property=TRIGGERED-ON-CHANGE
          signal CAN2_OTA_Lock_Req: start 31, 1 bit, big-endian, i-signal-type=PRIMITIVE, init-value=constant-reference=Init_CAN2_OTA_Lock_Req, base-type=uint8, implementation-data-type=uint8, transfer-property=TRIGGERED-ON-CHANGE
          signal CAN2_OTA_MDA_Status: start 15, 4 bit, big-endian, i-signal-type=PRIMITIVE, init-value=constant-reference=Init_CAN2_OTA_MDA_Status, base-type=uint8, implementation-data-type=uint8, transfer-property=TRIGGERED-ON-CHANGE
          signal CAN2_OTA_Mode: start 9, 1 bit, big-endian, i-signal-type=PRIMITIVE, init-value=constant-reference=Init_CAN2_OTA_Mode, base-type=uint8, implementation-data-type=uint8, transfer-property=TRIGGERED-ON-CHANGE
          signal CAN2_OTA_Network_Type: start 11, 2 bit, big-endian, i-signal-type=PRIMITIVE, init-value=constant-reference=Init_CAN2_OTA_Network_Type, base-type=uint8, implementation-data-type=uint8, transfer-property=TRIGGERED-ON-CHANGE
          signal CAN2_OTA_Permit_Agreed: start 63, 1 bit, big-endian, i-signal-type=PRIMITIVE, init-value=constant-reference=Init_CAN2_OTA_Permit_Agreed, base-type=uint8, implementation-data-type=uint8, transfer-property=PENDING
          signal CAN2_OTA_Progress_Rate: start 7, 8 bit, big-endian, i-signal-type=PRIMITIVE, init-value=constant-reference=Init_CAN2_OTA_Progress_Rate, base-type=uint8, implementation-data-type=uint8, transfer-property=TRIGGERED-ON-CHANGE
          signal CAN2_OTA_Remained_Time: start 58, 11 bit, big-endian, i-signal-type=PRIMITIVE, init-value=constant-reference=Init_CAN2_OTA_Remained_Time, base-type=uint16, implementation-data-type=uint16, transfer-property=PENDING
          signal CAN2_OTA_TBOXResetReq: start 30, 1 bit, big-endian, i-signal-type=PRIMITIVE, init-value=constant-reference=Init_CAN2_OTA_TBOXResetReq, base-type=uint8, implementation-data-type=uint8, transfer-property=PENDING
          signal CAN2_OTA_Up_Backcount: start 55, 8 bit, big-endian, i-signal-type=PRIMITIVE, init-value=constant-reference=Init_CAN2_OTA_Up_Backcount, base-type=uint8, implementation-data-type=uint8, transfer-property=TRIGGERED-ON-CHANGE
          signal CAN2_OTA_Update_Available: start 21, 1 bit, big-endian, i-signal-type=PRIMITIVE, init-value=constant-reference=Init_CAN2_OTA_Update_Available, base-type=uint8, implementation-data-type=uint8, transfer-property=TRIGGERED-ON-CHANGE
          signal CAN2_OTA_Updating_ECU: start 20, 5 bit, big-endian, i-signal-type=PRIMITIVE, init-value=constant-reference=Init_CAN2_OTA_Updating_ECU, base-type=uint8, implementation-data-type=uint8, transfer-property=TRIGGERED-ON-CHANGE
          signal CAN2_OTA_Updating_ECU_8bit: start 95, 8 bit, big-endian, i-signal-type=PRIMITIVE, init-value=constant-reference=Init_CAN2_OTA_Updating_ECU_8bit, base-type=uint8, implementation-data-type=uint8, transfer-property=TRIGGERED-ON-CHANGE
      frame CAN2_FD_THCM1: id 0x182, frame-length=20, can-addressing-mode=STANDARD, can-fd-frame-support=true, can-frame-rx-behavior=CAN-FD, can-frame-tx-behavior=CAN-FD
        pdu CAN2_FD_THCM1: length=20, minimum-delay=0.0, transmission-mode-true-timing=cyclic-timing=time-period=0.1, unused-bit-pattern=0
          mapping CAN2_SG_FD_THCM1: i-signal-group=CAN2_SG_FD_THCM1, start-position=0, transfer-property=PENDING
          signal CAN2_BatteryMode: start 118, 3 bit, big-endian, i-signal-type=PRIMITIVE, init-value=constant-reference=Init_CAN2_BatteryMode, base-type=uint8, implementation-data-type=uint8, transfer-property=PENDING
          signal CAN2_CCU_ACLampSts: start 6, 1 bit, big-endian, i-signal-type=PRIMITIVE, init-value=constant-reference=Init_CAN2_CCU_ACLampSts, base-type=uint8, implementation-data-type=uint8, transfer-property=PENDING
          signal CAN2_CCU_ACMaxLampSts: start 1, 1 bit, big-endian, i-signal-type=PRIMITIVE, init-value=constant-reference=Init_CAN2_CCU_ACMaxLampSts, base-type=uint8, implementation-data-type=uint8, transfer-property=PENDING
          signal CAN2_CCU_AutoLampSts: start 2, 1 bit, big-endian, i-signal-type=PRIMITIVE, init-value=constant-reference=Init_CAN2_CCU_AutoLampSts, base-type=uint8, implementation-data-type=uint8, transfer-property=PENDING
          signal CAN2_CCU_AutoMidLampSts: start 3, 1 bit, big-endian, i-signal-type=PRIMITIVE, init-value=constant-reference=Init_CAN2_CCU_AutoMidLampSts, base-type=uint8, implementation-data-type=uint8, transfer-property=PENDING
          signal CAN2_CCU_Dispaly_Request: start 5, 1 bit, big-endian, i-signal-type=PRIMITIVE, init-value=constant-reference=Init_CAN2_CCU_Dispaly_Request, base-type=uint8, implementation-data-type=uint8, transfer-property=PENDING
          signal CAN2_CCU_EcoSts: start 4, 1 bit, big-endian, i-signal-type=PRIMITIVE, init-value=constant-reference=Init_CAN2_CCU_EcoSts, base-type=uint8, implementation-data-type=uint8, transfer-property=PENDING
          signal CAN2_CCU_FrtOnOffLampSts: start 19, 1 bit, big-endian, i-signal-type=PRIMITIVE, init-value=constant-reference=Init_CAN2_CCU_FrtOnOffLampSts, base-type=uint8, implementation-data-type=uint8, transfer-property=PENDING
          signal CAN2_CCU_HEATMaxLampSts: start 7, 1 bit, big-endian, i-signal-type=PRIMITIVE, init-value=constant-reference=Init_CAN2_CCU_HEATMaxLampSts, base-type=uint8, implementation-data-type=uint8, transfer-property=PENDING
          signal CAN2_CCU_RrOnOffLampSts: start 23, 1 bit, big-endian, i-signal-type=PRIMITIVE, init-value=constant-reference=Init_CAN2_CCU_RrOnOffLampSts, base-type=uint8, implementation-data-type=uint8, transfer-property=PENDING
          signal CAN2_CCU_SyncLampSts: start 39, 1 bit, big-endian, i-signal-type=PRIMITIVE, init-value=constant-reference=Init_CAN2_CCU_SyncLampSts, base-type=uint8, implementation-data-type=uint8, transfer-property=PENDING
          signal CAN2_CabinMode: start 115, 4 bit, big-endian, i-signal-type=PRIMITIVE, init-value=constant-reference=Init_CAN2_CabinMode, base-type=uint8, implementation-data-type=uint8, transfer-property=PENDING
          signal CAN2_EDriveMode: start 63, 2 bit, big-endian, i-signal-type=PRIMITIVE, init-value=constant-reference=Init_CAN2_EDriveMode, base-type=uint8, implementation-data-type=uint8, transfer-property=PENDING
          signal CAN2_FD_AGS_Cmd: start 143, 8 bit, big-endian, i-signal-type=PRIMITIVE, init-value=constant-reference=Init_CAN2_FD_AGS_Cmd, base-type=uint8, implementation-data-type=uint8, transfer-property=PENDING
          signal CAN2_FD_RecyAuto_Cmd: start 111, 3 bit, big-endian, i-signal-type=PRIMITIVE, init-value=constant-reference=Init_CAN2_FD_RecyAuto_Cmd, base-type=uint8, implementation-data-type=uint8, transfer-property=PENDING
          signal CAN2_Fr_Coolantflow: start 61, 6 bit, big-endian, i-signal-type=PRIMITIVE, init-value=constant-reference=Init_CAN2_Fr_Coolantflow, base-type=uint8, implementation-data-type=uint8, transfer-property=PENDING
          signal CAN2_Fr_Coolanttemp: start 0, 9 bit, big-endian, i-signal-type=PRIMITIVE, init-value=constant-reference=Init_CAN2_Fr_Coolanttemp, base-type=uint16, implementation-data-type=uint16, transfer-property=PENDING
          signal CAN2_HPThermalRecoveryReq: start 55, 2 bit, big-endian, i-signal-type=PRIMITIVE, init-value=constant-reference=Init_CAN2_HPThermalRecoveryReq, base-type=uint8, implementation-data-type=uint8, transfer-property=PENDING
          signal CAN2_Rr_Coolantflow: start 150, 6 bit, big-endian, i-signal-type=PRIMITIVE, init-value=constant-reference=Init_CAN2_Rr_Coolantflow, base-type=uint8, implementation-data-type=uint8, transfer-property=PENDING
          signal CAN2_Rr_Coolanttemp: start 144, 9 bit, big-endian, i-signal-type=PRIMITIVE, init-value=constant-reference=Init_CAN2_Rr_Coolanttemp, base-type=uint16, implementation-data-type=uint16, transfer-property=PENDING
          signal CAN2_sigAirIntenZon1St: start 31, 4 bit, big-endian, i-signal-type=PRIMITIVE, init-value=constant-reference=Init_CAN2_sigAirIntenZon1St, base-type=uint8, implementation-data-type=uint8, transfer-property=PENDING
          signal CAN2_sigAirIntenZon3St: start 27, 4 bit, big-endian, i-signal-type=PRIMITIVE, init-value=constant-reference=Init_CAN2_sigAirIntenZon3St, base-type=uint8, implementation-data-type=uint8, transfer-property=PENDING
          signal CAN2_sigAmbAirT: start 95, 8 bit, big-endian, i-signal-type=PRIMITIVE, init-value=constant-reference=Init_CAN2_sigAmbAirT, base-type=uint8, implementation-data-type=uint8, transfer-property=PENDING
          signal CAN2_sigCbnAirT: start 87, 8 bit, big-endian, i-signal-type=PRIMITIVE, init-value=constant-reference=Init_CAN2_sigCbnAirT, base-type=uint8, implementation-data-type=uint8, transfer-property=PENDING
          signal CAN2_sigCbnPTCPwrAct: start 79, 8 bit, big-endian, i-signal-type=PRIMITIVE, init-value=constant-reference=Init_CAN2_sigCbnPTCPwrAct, base-type=uint8, implementation-data-type=uint8, transfer-property=PENDING
          signal CAN2_sigCbnSolarLeft: start 127, 8 bit, big-endian, i-signal-type=PRIMITIVE, init-value=constant-reference=Init_CAN2_sigCbnSolarLeft, base-type=uint8, implementation-data-type=uint8, transfer-property=PENDING
          signal CAN2_sigCbnSolarRight: start 103, 8 bit, big-endian, i-signal-type=PRIMITIVE, init-value=constant-reference=Init_CAN2_sigCbnSolarRight, base-type=uint8, implementation-data-type=uint8, transfer-property=PENDING
          signal CAN2_sigClmtCmprPwrAct: start 71, 8 bit, big-endian, i-signal-type=PRIMITIVE, init-value=constant-reference=Init_CAN2_sigClmtCmprPwrAct, base-type=uint8, implementation-data-type=uint8, transfer-property=PENDING
          signal CAN2_sigClntTHvBattOut: start 135, 8 bit, big-endian, i-signal-type=PRIMITIVE, init-value=constant-reference=Init_CAN2_sigClntTHvBattOut, base-type=uint8, implementation-data-type=uint8, transfer-property=PENDING
          signal CAN2_sigDfrstSt: start 38, 1 bit, big-endian, i-signal-type=PRIMITIVE, init-value=constant-reference=Init_CAN2_sigDfrstSt, base-type=uint8, implementation-data-type=uint8, transfer-property=PENDING
          signal CAN2_sigHvacSt: start 46, 1 bit, big-endian, i-signal-type=PRIMITIVE, init-value=constant-reference=Init_CAN2_sigHvacSt, base-type=uint8, implementation-data-type=uint8, transfer-property=PENDING
          signal CAN2_sigRecircSt: start 47, 1 bit, big-endian, i-signal-type=PRIMITIVE, init-value=constant-reference=Init_CAN2_sigRecircSt, base-type=uint8, implementation-data-type=uint8, transfer-property=PENDING
          signal CAN2_sigSetTempZon1St: start 53, 6 bit, big-endian, i-signal-type=PRIMITIVE, init-value=constant-reference=Init_CAN2_sigSetTempZon1St, base-type=uint8, implementation-data-type=uint8, transfer-property=PENDING
          signal CAN2_sigSetTempZon2St: start 45, 6 bit, big-endian, i-signal-type=PRIMITIVE, init-value=constant-reference=Init_CAN2_sigSetTempZon2St, base-type=uint8, implementation-data-type=uint8, transfer-property=PENDING
          signal CAN2_sigSetTempZon3St: start 37, 6 bit, big-endian, i-signal-type=PRIMITIVE, init-value=constant-reference=Init_CAN2_sigSetTempZon3St, base-type=uint8, implementation-data-type=uint8, transfer-property=PENDING
          signal CAN2_sigWindDirZon1St: start 22, 3 bit, big-endian, i-signal-type=PRIMITIVE, init-value=constant-reference=Init_CAN2_sigWindDirZon1St, base-type=uint8, implementation-data-type=uint8, transfer-property=PENDING
          signal CAN2_sigWindDirZon3St: start 18, 3 bit, big-endian, i-signal-type=PRIMITIVE, init-value=constant-reference=Init_CAN2_sigWindDirZon3St, base-type=uint8, implementation-data-type=uint8, transfer-property=PENDING
      frame CAN2_FD_TPMS1: id 0x435, frame-length=20, can-addressing-mode=STANDARD, can-fd-frame-support=true, can-frame-rx-behavior=CAN-FD, can-frame-tx-behavior=CAN-FD
        pdu CAN2_FD_TPMS1: length=20, minimum-delay=0.0, transmission-mode-true-timing={cyclic-timing=time-period=0.2, event-controlled-timing={number-of-repetitions=0, repetition-period=0.01}}, unused-bit-pattern=0
          mapping CAN2_SG_FD_TPMS1: i-signal-group=CAN2_SG_FD_TPMS1, start-position=0, transfer-property=TRIGGERED-ON-CHANGE
          signal CAN2_AutoLTips: start 25, 2 bit, big-endian, i-signal-type=PRIMITIVE, init-value=constant-reference=Init_CAN2_AutoLTips, base-type=uint8, implementation-data-type=uint8, transfer-property=TRIGGERED-ON-CHANGE
          signal CAN2_CWheelTips: start 34, 2 bit, big-endian, i-signal-type=PRIMITIVE, init-value=constant-reference=Init_CAN2_CWheelTips, base-type=uint8, implementation-data-type=uint8, transfer-property=TRIGGERED-ON-CHANGE
          signal CAN2_LFBatWarn: start 105, 1 bit, big-endian, i-signal-type=PRIMITIVE, init-value=constant-reference=Init_CAN2_LFBatWarn, base-type=uint8, implementation-data-type=uint8, transfer-property=TRIGGERED-ON-CHANGE
          signal CAN2_LFPressIndi: start 123, 2 bit, big-endian, i-signal-type=PRIMITIVE, init-value=constant-reference=Init_CAN2_LFPressIndi, base-type=uint8, implementation-data-type=uint8, transfer-property=TRIGGERED-ON-CHANGE
          signal CAN2_LFSensorFail: start 117, 1 bit, big-endian, i-signal-type=PRIMITIVE, init-value=constant-reference=Init_CAN2_LFSensorFail, base-type=uint8, implementation-data-type=uint8, transfer-property=TRIGGERED-ON-CHANGE
          signal CAN2_LFSensorMode: start 15, 1 bit, big-endian, i-signal-type=PRIMITIVE, init-value=constant-reference=Init_CAN2_LFSensorMode, base-type=uint8, implementation-data-type=uint8, transfer-property=TRIGGERED-ON-CHANGE
          signal CAN2_LFWheelDebug: start 109, 1 bit, big-endian, i-signal-type=PRIMITIVE, init-value=constant-reference=Init_CAN2_LFWheelDebug, base-type=uint8, implementation-data-type=uint8, transfer-property=TRIGGERED-ON-CHANGE
          signal CAN2_LFWheelPSW: start 151, 8 bit, big-endian, i-signal-type=PRIMITIVE, init-value=constant-reference=Init_CAN2_LFWheelPSW, base-type=uint8, implementation-data-type=uint8, transfer-property=TRIGGERED-ON-CHANGE
          signal CAN2_LFWheelPress: start 95, 8 bit, big-endian, i-signal-type=PRIMITIVE, init-value=constant-reference=Init_CAN2_LFWheelPress, base-type=uint8, implementation-data-type=uint8, transfer-property=TRIGGERED-ON-CHANGE
          signal CAN2_LFWheelTemp: start 63, 8 bit, big-endian, i-signal-type=PRIMITIVE, init-value=constant-reference=Init_CAN2_LFWheelTemp, base-type=uint8, implementation-data-type=uint8, transfer-property=TRIGGERED-ON-CHANGE
          signal CAN2_LFWheelTmpIndi: start 113, 1 bit, big-endian, i-signal-type=PRIMITIVE, init-value=constant-reference=Init_CAN2_LFWheelTmpIndi, base-type=uint8, implementation-data-type=uint8, transfer-property=TRIGGERED-ON-CHANGE
          signal CAN2_LRBatWarn: start 107, 1 bit, big-endian, i-signal-type=PRIMITIVE, init-value=constant-reference=Init_CAN2_LRBatWarn, base-type=uint8, implementation-data-type=uint8, transfer-property=TRIGGERED-ON-CHANGE
          signal CAN2_LRPressIndi: start 127, 2 bit, big-endian, i-signal-type=PRIMITIVE, init-value=constant-reference=Init_CAN2_LRPressIndi, base-type=uint8, implementation-data-type=uint8, transfer-property=TRIGGERED-ON-CHANGE
          signal CAN2_LRSensorFail: start 119, 1 bit, big-endian, i-signal-type=PRIMITIVE, init-value=constant-reference=Init_CAN2_LRSensorFail, base-type=uint8, implementation-data-type=uint8, transfer-property=TRIGGERED-ON-CHANGE
          signal CAN2_LRSensorMode: start 13, 1 bit, big-endian, i-signal-type=PRIMITIVE, init-value=constant-reference=Init_CAN2_LRSensorMode, base-type=uint8, implementation-data-type=uint8, transfer-property=TRIGGERED-ON-CHANGE
          signal CAN2_LRWheelDebug: start 111, 1 bit, big-endian, i-signal-type=PRIMITIVE, init-value=constant-reference=Init_CAN2_LRWheelDebug, base-type=uint8, implementation-data-type=uint8, transfer-property=TRIGGERED-ON-CHANGE
          signal CAN2_LRWheelPSW: start 159, 8 bit, big-endian, i-signal-type=PRIMITIVE, init-value=constant-reference=Init_CAN2_LRWheelPSW, base-type=uint8, implementation-data-type=uint8, transfer-property=TRIGGERED-ON-CHANGE
          signal CAN2_LRWheelPress: start 79, 8 bit, big-endian, i-signal-type=PRIMITIVE, init-value=constant-reference=Init_CAN2_LRWheelPress, base-type=uint8, implementation-data-type=uint8, transfer-property=TRIGGERED-ON-CHANGE
          signal CAN2_LRWheelTemp: start 47, 8 bit, big-endian, i-signal-type=PRIMITIVE, init-value=constant-reference=Init_CAN2_LRWheelTemp, base-type=uint8, implementation-data-type=uint8, transfer-property=TRIGGERED-ON-CHANGE
          signal CAN2_LRWheelTmpIndi: start 115, 1 bit, big-endian, i-signal-type=PRIMITIVE, init-value=constant-reference=Init_CAN2_LRWheelTmpIndi, base-type=uint8, implementation-data-type=uint8, transfer-property=TRIGGERED-ON-CHANGE
          signal CAN2_RFBatWarn: start 104, 1 bit, big-endian, i-signal-type=PRIMITIVE, init-value=constant-reference=Init_CAN2_RFBatWarn, base-type=uint8, implementation-data-type=uint8, transfer-property=TRIGGERED-ON-CHANGE
          signal CAN2_RFPressIndi: start 121, 2 bit, big-endian, i-signal-type=PRIMITIVE, init-value=constant-reference=Init_CAN2_RFPressIndi, base-type=uint8, implementation-data-type=uint8, transfer-property=TRIGGERED-ON-CHANGE
          signal CAN2_RFSensorFail: start 116, 1 bit, big-endian, i-signal-type=PRIMITIVE, init-value=constant-reference=Init_CAN2_RFSensorFail, base-type=uint8, implementation-data-type=uint8, transfer-property=TRIGGERED-ON-CHANGE
          signal CAN2_RFSensorMode: start 14, 1 bit, big-endian, i-signal-type=PRIMITIVE, init-value=constant-reference=Init_CAN2_RFSensorMode, base-type=uint8, implementation-data-type=uint8, transfer-property=TRIGGERED-ON-CHANGE
          signal CAN2_RFWheelDebug: start 108, 1 bit, big-endian, i-signal-type=PRIMITIVE, init-value=constant-reference=Init_CAN2_RFWheelDebug, base-type=uint8, implementation-data-type=uint8, transfer-property=TRIGGERED-ON-CHANGE
          signal CAN2_RFWheelPSW: start 143, 8 bit, big-endian, i-signal-type=PRIMITIVE, init-value=constant-reference=Init_CAN2_RFWheelPSW, base-type=uint8, implementation-data-type=uint8, transfer-property=TRIGGERED-ON-CHANGE
          signal CAN2_RFWheelPress: start 103, 8 bit, big-endian, i-signal-type=PRIMITIVE, init-value=constant-reference=Init_CAN2_RFWheelPress, base-type=uint8, implementation-data-type=uint8, transfer-property=TRIGGERED-ON-CHANGE
          signal CAN2_RFWheelTemp: start 71, 8 bit, big-endian, i-signal-type=PRIMITIVE, init-value=constant-reference=Init_CAN2_RFWheelTemp, base-type=uint8, implementation-data-type=uint8, transfer-property=TRIGGERED-ON-CHANGE
          signal CAN2_RFWheelTmpIndi: start 112, 1 bit, big-endian, i-signal-type=PRIMITIVE, init-value=constant-reference=Init_CAN2_RFWheelTmpIndi, base-type=uint8, implementation-data-type=uint8, transfer-property=TRIGGERED-ON-CHANGE
          signal CAN2_RRBatWarn: start 106, 1 bit, big-endian, i-signal-type=PRIMITIVE, init-value=constant-reference=Init_CAN2_RRBatWarn, base-type=uint8, implementation-data-type=uint8, transfer-property=TRIGGERED-ON-CHANGE
          signal CAN2_RRPressIndi: start 125, 2 bit, big-endian, i-signal-type=PRIMITIVE, init-value=constant-reference=Init_CAN2_RRPressIndi, base-type=uint8, implementation-data-type=uint8, transfer-property=TRIGGERED-ON-CHANGE
          signal CAN2_RRSensorFail: start 118, 1 bit, big-endian, i-signal-type=PRIMITIVE, init-value=constant-reference=Init_CAN2_RRSensorFail, base-type=uint8, implementation-data-type=uint8, transfer-property=TRIGGERED-ON-CHANGE
          signal CAN2_RRSensorMode: start 12, 1 bit, big-endian, i-signal-type=PRIMITIVE, init-value=constant-reference=Init_CAN2_RRSensorMode, base-type=uint8, implementation-data-type=uint8, transfer-property=TRIGGERED-ON-CHANGE
          signal CAN2_RRWheelDebug: start 110, 1 bit, big-endian, i-signal-type=PRIMITIVE, init-value=constant-reference=Init_CAN2_RRWheelDebug, base-type=uint8, implementation-data-type=uint8, transfer-property=TRIGGERED-ON-CHANGE
          signal CAN2_RRWheelPSW: start 135, 8 bit, big-endian, i-signal-type=PRIMITIVE, init-value=constant-reference=Init_CAN2_RRWheelPSW, base-type=uint8, implementation-data-type=uint8, transfer-property=TRIGGERED-ON-CHANGE
          signal CAN2_RRWheelPress: start 87, 8 bit, big-endian, i-signal-type=PRIMITIVE, init-value=constant-reference=Init_CAN2_RRWheelPress, base-type=uint8, implementation-data-type=uint8, transfer-property=TRIGGERED-ON-CHANGE
          signal CAN2_RRWheelTemp: start 55, 8 bit, big-endian, i-signal-type=PRIMITIVE, init-value=constant-reference=Init_CAN2_RRWheelTemp, base-type=uint8, implementation-data-type=uint8, transfer-property=TRIGGERED-ON-CHANGE
          signal CAN2_RRWheelTmpIndi: start 114, 1 bit, big-endian, i-signal-type=PRIMITIVE, init-value=constant-reference=Init_CAN2_RRWheelTmpIndi, base-type=uint8, implementation-data-type=uint8, transfer-property=TRIGGERED-ON-CHANGE
          signal CAN2_TPMSWarnIndi: start 39, 2 bit, big-endian, i-signal-type=PRIMITIVE, init-value=constant-reference=Init_CAN2_TPMSWarnIndi, base-type=uint8, implementation-data-type=uint8, transfer-property=TRIGGERED-ON-CHANGE
          signal CAN2_TPMS_Cali_Butt_Allow: start 35, 1 bit, big-endian, i-signal-type=PRIMITIVE, init-value=constant-reference=Init_CAN2_TPMS_Cali_Butt_Allow, base-type=uint8, implementation-data-type=uint8, transfer-property=TRIGGERED-ON-CHANGE
          signal CAN2_TPMS_Res_Butt_Allow: start 37, 1 bit, big-endian, i-signal-type=PRIMITIVE, init-value=constant-reference=Init_CAN2_TPMS_Res_Butt_Allow, base-type=uint8, implementation-data-type=uint8, transfer-property=TRIGGERED-ON-CHANGE
      frame CAN2_FD_TPMS2: id 0x436, frame-length=32, can-addressing-mode=STANDARD, can-fd-frame-support=true, can-frame-rx-behavior=CAN-FD, can-frame-tx-behavior=CAN-FD
        pdu CAN2_FD_TPMS2: length=32, minimum-delay=0.0, transmission-mode-true-timing={cyclic-timing=time-period=0.2, event-controlled-timing={number-of-repetitions=0, repetition-period=0.01}}, unused-bit-pattern=0
          mapping CAN2_SG_FD_TPMS2: i-signal-group=CAN2_SG_FD_TPMS2, start-position=0, transfer-property=TRIGGERED-ON-CHANGE
          signal CAN2_ID1_ALTU: start 215, 32 bit, big-endian, i-signal-type=PRIMITIVE, init-value=constant-reference=Init_CAN2_ID1_ALTU, base-type=uint32, implementation-data-type=uint32, transfer-property=TRIGGERED-ON-CHANGE
          signal CAN2_ID1_Loc_ALTU: start 74, 3 bit, big-endian, i-signal-type=PRIMITIVE, init-value=constant-reference=Init_CAN2_ID1_Loc_ALTU, base-type=uint8, implementation-data-type=uint8, transfer-property=TRIGGERED-ON-CHANGE
          signal CAN2_ID1_message_ALTU: start 63, 8 bit, big-endian, i-signal-type=PRIMITIVE, init-value=constant-reference=Init_CAN2_ID1_message_ALTU, base-type=uint8, implementation-data-type=uint8, transfer-property=TRIGGERED-ON-CHANGE
          signal CAN2_ID2_ALTU: start 183, 32 bit, big-endian, i-signal-type=PRIMITIVE, init-value=constant-reference=Init_CAN2_ID2_ALTU, base-type=uint32, implementation-data-type=uint32, transfer-property=TRIGGERED-ON-CHANGE
          signal CAN2_ID2_Loc_ALTU: start 77, 3 bit, big-endian, i-signal-type=PRIMITIVE, init-value=constant-reference=Init_CAN2_ID2_Loc_ALTU, base-type=uint8, implementation-data-type=uint8, transfer-property=TRIGGERED-ON-CHANGE
          signal CAN2_ID2_message_ALTU: start 55, 8 bit, big-endian, i-signal-type=PRIMITIVE, init-value=constant-reference=Init_CAN2_ID2_message_ALTU, base-type=uint8, implementation-data-type=uint8, transfer-property=TRIGGERED-ON-CHANGE
          signal CAN2_ID3_ALTU: start 151, 32 bit, big-endian, i-signal-type=PRIMITIVE, init-value=constant-reference=Init_CAN2_ID3_ALTU, base-type=uint32, implementation-data-type=uint32, transfer-property=TRIGGERED-ON-CHANGE
          signal CAN2_ID3_Loc_ALTU: start 66, 3 bit, big-endian, i-signal-type=PRIMITIVE, init-value=constant-reference=Init_CAN2_ID3_Loc_ALTU, base-type=uint8, implementation-data-type=uint8, transfer-property=TRIGGERED-ON-CHANGE
          signal CAN2_ID3_message_ALTU: start 47, 8 bit, big-endian, i-signal-type=PRIMITIVE, init-value=constant-reference=Init_CAN2_ID3_message_ALTU, base-type=uint8, implementation-data-type=uint8, transfer-property=TRIGGERED-ON-CHANGE
          signal CAN2_ID4_ALTU: start 119, 32 bit, big-endian, i-signal-type=PRIMITIVE, init-value=constant-reference=Init_CAN2_ID4_ALTU, base-type=uint32, implementation-data-type=uint32, transfer-property=TRIGGERED-ON-CHANGE
          signal CAN2_ID4_Loc_ALTU: start 69, 3 bit, big-endian, i-signal-type=PRIMITIVE, init-value=constant-reference=Init_CAN2_ID4_Loc_ALTU, base-type=uint8, implementation-data-type=uint8, transfer-property=TRIGGERED-ON-CHANGE
          signal CAN2_ID4_message_ALTU: start 39, 8 bit, big-endian, i-signal-type=PRIMITIVE, init-value=constant-reference=Init_CAN2_ID4_message_ALTU, base-type=uint8, implementation-data-type=uint8, transfer-property=TRIGGERED-ON-CHANGE
          signal CAN2_IDin_ALTU: start 87, 32 bit, big-endian, i-signal-type=PRIMITIVE, init-value=constant-reference=Init_CAN2_IDin_ALTU, base-type=uint32, implementation-data-type=uint32, transfer-property=TRIGGERED-ON-CHANGE
          signal CAN2_RF_FAT_ALTU: start 70, 1 bit, big-endian, i-signal-type=PRIMITIVE, init-value=constant-reference=Init_CAN2_RF_FAT_ALTU, base-type=uint8, implementation-data-type=uint8, transfer-property=TRIGGERED-ON-CHANGE
          signal CAN2_S1WheelDebug_ALTU: start 31, 8 bit, big-endian, i-signal-type=PRIMITIVE, init-value=constant-reference=Init_CAN2_S1WheelDebug_ALTU, base-type=uint8, implementation-data-type=uint8, transfer-property=TRIGGERED-ON-CHANGE
          signal CAN2_S2WheelDebug_ALTU: start 23, 8 bit, big-endian, i-signal-type=PRIMITIVE, init-value=constant-reference=Init_CAN2_S2WheelDebug_ALTU, base-type=uint8, implementation-data-type=uint8, transfer-property=TRIGGERED-ON-CHANGE
          signal CAN2_S3WheelDebug_ALTU: start 15, 8 bit, big-endian, i-signal-type=PRIMITIVE, init-value=constant-reference=Init_CAN2_S3WheelDebug_ALTU, base-type=uint8, implementation-data-type=uint8, transfer-property=TRIGGERED-ON-CHANGE
          signal CAN2_S4WheelDebug_ALTU: start 7, 8 bit, big-endian, i-signal-type=PRIMITIVE, init-value=constant-reference=Init_CAN2_S4WheelDebug_ALTU, base-type=uint8, implementation-data-type=uint8, transfer-property=TRIGGERED-ON-CHANGE
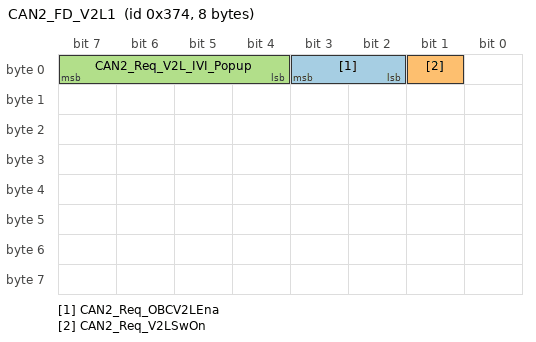
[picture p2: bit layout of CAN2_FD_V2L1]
      frame CAN2_FD_V2L1: id 0x374, frame-length=8, can-addressing-mode=STANDARD, can-fd-frame-support=true, can-frame-rx-behavior=CAN-FD, can-frame-tx-behavior=CAN-FD
        pdu CAN2_FD_V2L1: length=8, minimum-delay=0.0, transmission-mode-true-timing={cyclic-timing=time-period=0.1, event-controlled-timing={number-of-repetitions=0, repetition-period=0.01}}, unused-bit-pattern=0
          mapping CAN2_SG_FD_V2L1: i-signal-group=CAN2_SG_FD_V2L1, start-position=0, transfer-property=TRIGGERED-ON-CHANGE
          signal CAN2_Req_OBCV2LEna: start 3, 2 bit, big-endian, i-signal-type=PRIMITIVE, init-value=constant-reference=Init_CAN2_Req_OBCV2LEna, base-type=uint8, implementation-data-type=uint8, transfer-property=PENDING
          signal CAN2_Req_V2LSwOn: start 1, 1 bit, big-endian, i-signal-type=PRIMITIVE, init-value=constant-reference=Init_CAN2_Req_V2LSwOn, base-type=uint8, implementation-data-type=uint8, transfer-property=TRIGGERED-ON-CHANGE
          signal CAN2_Req_V2L_IVI_Popup: start 7, 4 bit, big-endian, i-signal-type=PRIMITIVE, init-value=constant-reference=Init_CAN2_Req_V2L_IVI_Popup, base-type=uint8, implementation-data-type=uint8, transfer-property=TRIGGERED-ON-CHANGE
      frame CAN2_FD_VCU0: id 0x1F0, frame-length=16, can-addressing-mode=STANDARD, can-fd-frame-support=true, can-frame-rx-behavior=CAN-FD, can-frame-tx-behavior=CAN-FD
        pdu CAN2_FD_VCU0: length=16, minimum-delay=0.0, transmission-mode-true-timing={cyclic-timing=time-period=0.1, event-controlled-timing={number-of-repetitions=0, repetition-period=0.002}}, unused-bit-pattern=0
          mapping CAN2_SG_FD_VCU0: i-signal-group=CAN2_SG_FD_VCU0, start-position=0, transfer-property=TRIGGERED-ON-CHANGE
          signal CAN2_EVCCAplusPwrUpReq: start 94, 1 bit, big-endian, i-signal-type=PRIMITIVE, init-value=constant-reference=Init_CAN2_EVCCAplusPwrUpReq, base-type=uint8, implementation-data-type=uint8, transfer-property=TRIGGERED-ON-CHANGE
          signal CAN2_FDADC12VDetAvg: start 127, 8 bit, big-endian, i-signal-type=PRIMITIVE, init-value=constant-reference=Init_CAN2_FDADC12VDetAvg, base-type=uint8, implementation-data-type=uint8, transfer-property=TRIGGERED-ON-CHANGE
          signal CAN2_Fr_TqSource: start 47, 4 bit, big-endian, i-signal-type=PRIMITIVE, init-value=constant-reference=Init_CAN2_Fr_TqSource, base-type=uint8, implementation-data-type=uint8, transfer-property=TRIGGERED-ON-CHANGE
          signal CAN2_HVRlyOpFail: start 56, 1 bit, big-endian, i-signal-type=PRIMITIVE, init-value=constant-reference=Init_CAN2_HVRlyOpFail, base-type=uint8, implementation-data-type=uint8, transfer-property=TRIGGERED-ON-CHANGE
          signal CAN2_HVTHCMSysAvail: start 41, 2 bit, big-endian, i-signal-type=PRIMITIVE, init-value=constant-reference=Init_CAN2_HVTHCMSysAvail, base-type=uint8, implementation-data-type=uint8, transfer-property=TRIGGERED-ON-CHANGE
          signal CAN2_LVBattChrgtimeAct: start 107, 12 bit, big-endian, i-signal-type=PRIMITIVE, init-value=constant-reference=Init_CAN2_LVBattChrgtimeAct, base-type=uint16, implementation-data-type=uint16, transfer-property=TRIGGERED-ON-CHANGE
          signal CAN2_LVBattVoltSta: start 43, 2 bit, big-endian, i-signal-type=PRIMITIVE, init-value=constant-reference=Init_CAN2_LVBattVoltSta, base-type=uint8, implementation-data-type=uint8, transfer-property=TRIGGERED-ON-CHANGE
          signal CAN2_LVChrgHoldTAct: start 91, 12 bit, big-endian, i-signal-type=PRIMITIVE, init-value=constant-reference=Init_CAN2_LVChrgHoldTAct, base-type=uint16, implementation-data-type=uint16, transfer-property=TRIGGERED-ON-CHANGE
          signal CAN2_LVSilentChrgLv: start 83, 2 bit, big-endian, i-signal-type=PRIMITIVE, init-value=constant-reference=Init_CAN2_LVSilentChrgLv, base-type=uint8, implementation-data-type=uint8, transfer-property=TRIGGERED-ON-CHANGE
          signal CAN2_LVSilentChrgReq: start 81, 1 bit, big-endian, i-signal-type=PRIMITIVE, init-value=constant-reference=Init_CAN2_LVSilentChrgReq, base-type=uint8, implementation-data-type=uint8, transfer-property=TRIGGERED-ON-CHANGE
          signal CAN2_LVSilentChrgSta: start 85, 2 bit, big-endian, i-signal-type=PRIMITIVE, init-value=constant-reference=Init_CAN2_LVSilentChrgSta, base-type=uint8, implementation-data-type=uint8, transfer-property=TRIGGERED-ON-CHANGE
          signal CAN2_MCUActDisFail: start 71, 1 bit, big-endian, i-signal-type=PRIMITIVE, init-value=constant-reference=Init_CAN2_MCUActDisFail, base-type=uint8, implementation-data-type=uint8, transfer-property=TRIGGERED-ON-CHANGE
          signal CAN2_PMMAllowECUSleep: start 95, 1 bit, big-endian, i-signal-type=PRIMITIVE, init-value=constant-reference=Init_CAN2_PMMAllowECUSleep, base-type=uint8, implementation-data-type=uint8, transfer-property=TRIGGERED-ON-CHANGE
          signal CAN2_PowerDownFault: start 19, 4 bit, big-endian, i-signal-type=PRIMITIVE, init-value=constant-reference=Init_CAN2_PowerDownFault, base-type=uint8, implementation-data-type=uint8, transfer-property=TRIGGERED-ON-CHANGE
          signal CAN2_PowerDownState: start 22, 3 bit, big-endian, i-signal-type=PRIMITIVE, init-value=constant-reference=Init_CAN2_PowerDownState, base-type=uint8, implementation-data-type=uint8, transfer-property=TRIGGERED-ON-CHANGE
          signal CAN2_PowerUpFault: start 11, 4 bit, big-endian, i-signal-type=PRIMITIVE, init-value=constant-reference=Init_CAN2_PowerUpFault, base-type=uint8, implementation-data-type=uint8, transfer-property=TRIGGERED-ON-CHANGE
          signal CAN2_PowerUpState: start 15, 4 bit, big-endian, i-signal-type=PRIMITIVE, init-value=constant-reference=Init_CAN2_PowerUpState, base-type=uint8, implementation-data-type=uint8, transfer-property=TRIGGERED-ON-CHANGE
          signal CAN2_PwrDownReq: start 37, 2 bit, big-endian, i-signal-type=PRIMITIVE, init-value=constant-reference=Init_CAN2_PwrDownReq, base-type=uint8, implementation-data-type=uint8, transfer-property=TRIGGERED-ON-CHANGE
          signal CAN2_PwrStaConstraint: start 29, 3 bit, big-endian, i-signal-type=PRIMITIVE, init-value=constant-reference=Init_CAN2_PwrStaConstraint, base-type=uint8, implementation-data-type=uint8, transfer-property=TRIGGERED-ON-CHANGE
          signal CAN2_PwrStaONTOIVIPopReq: start 70, 1 bit, big-endian, i-signal-type=PRIMITIVE, init-value=constant-reference=Init_CAN2_PwrStaONTOIVIPopReq, base-type=uint8, implementation-data-type=uint8, transfer-property=TRIGGERED-ON-CHANGE
          signal CAN2_PwrStaONTOIVIPopT: start 67, 12 bit, big-endian, i-signal-type=PRIMITIVE, init-value=constant-reference=Init_CAN2_PwrStaONTOIVIPopT, base-type=uint16, implementation-data-type=uint16, transfer-property=TRIGGERED-ON-CHANGE
          signal CAN2_PwrStaSelect: start 31, 2 bit, big-endian, i-signal-type=PRIMITIVE, init-value=constant-reference=Init_CAN2_PwrStaSelect, base-type=uint8, implementation-data-type=uint8, transfer-property=TRIGGERED-ON-CHANGE
          signal CAN2_PwrStaTOSta: start 69, 1 bit, big-endian, i-signal-type=PRIMITIVE, init-value=constant-reference=Init_CAN2_PwrStaTOSta, base-type=uint8, implementation-data-type=uint8, transfer-property=TRIGGERED-ON-CHANGE
          signal CAN2_PwrUpReq: start 39, 2 bit, big-endian, i-signal-type=PRIMITIVE, init-value=constant-reference=Init_CAN2_PwrUpReq, base-type=uint8, implementation-data-type=uint8, transfer-property=TRIGGERED-ON-CHANGE
          signal CAN2_Rr_TqSource: start 35, 4 bit, big-endian, i-signal-type=PRIMITIVE, init-value=constant-reference=Init_CAN2_Rr_TqSource, base-type=uint8, implementation-data-type=uint8, transfer-property=TRIGGERED-ON-CHANGE
          signal CAN2_SchedChgTOSta: start 87, 1 bit, big-endian, i-signal-type=PRIMITIVE, init-value=constant-reference=Init_CAN2_SchedChgTOSta, base-type=uint8, implementation-data-type=uint8, transfer-property=TRIGGERED-ON-CHANGE
          signal CAN2_SilentChkAllowSleep: start 86, 1 bit, big-endian, i-signal-type=PRIMITIVE, init-value=constant-reference=Init_CAN2_SilentChkAllowSleep, base-type=uint8, implementation-data-type=uint8, transfer-property=TRIGGERED-ON-CHANGE
          signal CAN2_SysAllowReadySta: start 57, 1 bit, big-endian, i-signal-type=PRIMITIVE, init-value=constant-reference=Init_CAN2_SysAllowReadySta, base-type=uint8, implementation-data-type=uint8, transfer-property=TRIGGERED-ON-CHANGE
          signal CAN2_SysPwrSta: start 7, 4 bit, big-endian, i-signal-type=PRIMITIVE, init-value=constant-reference=Init_CAN2_SysPwrSta, base-type=uint8, implementation-data-type=uint8, transfer-property=TRIGGERED-ON-CHANGE
          signal CAN2_TCountSta: start 26, 2 bit, big-endian, i-signal-type=PRIMITIVE, init-value=constant-reference=Init_CAN2_TCountSta, base-type=uint8, implementation-data-type=uint8, transfer-property=TRIGGERED-ON-CHANGE
          signal CAN2_TimerAllowSleep: start 80, 1 bit, big-endian, i-signal-type=PRIMITIVE, init-value=constant-reference=Init_CAN2_TimerAllowSleep, base-type=uint8, implementation-data-type=uint8, transfer-property=TRIGGERED-ON-CHANGE
          signal CAN2_VCUBrkSWSta: start 63, 2 bit, big-endian, i-signal-type=PRIMITIVE, init-value=constant-reference=Init_CAN2_VCUBrkSWSta, base-type=uint8, implementation-data-type=uint8, transfer-property=TRIGGERED-ON-CHANGE
          signal CAN2_VCUFLDoorSta: start 61, 1 bit, big-endian, i-signal-type=PRIMITIVE, init-value=constant-reference=Init_CAN2_VCUFLDoorSta, base-type=uint8, implementation-data-type=uint8, transfer-property=TRIGGERED-ON-CHANGE
          signal CAN2_VCUFRDoorSta: start 60, 1 bit, big-endian, i-signal-type=PRIMITIVE, init-value=constant-reference=Init_CAN2_VCUFRDoorSta, base-type=uint8, implementation-data-type=uint8, transfer-property=TRIGGERED-ON-CHANGE
          signal CAN2_VCUHoodSWSta: start 23, 1 bit, big-endian, i-signal-type=PRIMITIVE, init-value=constant-reference=Init_CAN2_VCUHoodSWSta, base-type=uint8, implementation-data-type=uint8, transfer-property=TRIGGERED-ON-CHANGE
          signal CAN2_VCURLDoorSta: start 59, 1 bit, big-endian, i-signal-type=PRIMITIVE, init-value=constant-reference=Init_CAN2_VCURLDoorSta, base-type=uint8, implementation-data-type=uint8, transfer-property=TRIGGERED-ON-CHANGE
          signal CAN2_VCURRDoorSta: start 58, 1 bit, big-endian, i-signal-type=PRIMITIVE, init-value=constant-reference=Init_CAN2_VCURRDoorSta, base-type=uint8, implementation-data-type=uint8, transfer-property=TRIGGERED-ON-CHANGE
          signal CAN2_VCUTailgateSWSta: start 24, 1 bit, big-endian, i-signal-type=PRIMITIVE, init-value=constant-reference=Init_CAN2_VCUTailgateSWSta, base-type=uint8, implementation-data-type=uint8, transfer-property=TRIGGERED-ON-CHANGE
          signal CAN2_VehHVPwrAvail4THCM: start 55, 8 bit, big-endian, i-signal-type=PRIMITIVE, init-value=constant-reference=Init_CAN2_VehHVPwrAvail4THCM, base-type=uint8, implementation-data-type=uint8, transfer-property=TRIGGERED-ON-CHANGE
      frame CAN2_FD_VCU1: id 0x116, frame-length=8, can-addressing-mode=STANDARD, can-fd-frame-support=true, can-frame-rx-behavior=CAN-FD, can-frame-tx-behavior=CAN-FD
        pdu CAN2_FD_VCU1: length=8, minimum-delay=0.0, transmission-mode-true-timing={cyclic-timing=time-period=0.1, event-controlled-timing={number-of-repetitions=0, repetition-period=0.01}}, unused-bit-pattern=0
          mapping CAN2_SG_FD_VCU1: i-signal-group=CAN2_SG_FD_VCU1, start-position=0, transfer-property=TRIGGERED-ON-CHANGE
          signal CAN2_ActiveDischReq: start 44, 1 bit, big-endian, i-signal-type=PRIMITIVE, init-value=constant-reference=Init_CAN2_ActiveDischReq, base-type=uint8, implementation-data-type=uint8, transfer-property=TRIGGERED-ON-CHANGE
          signal CAN2_CC_Crl_Sta: start 28, 3 bit, big-endian, i-signal-type=PRIMITIVE, init-value=constant-reference=Init_CAN2_CC_Crl_Sta, base-type=uint8, implementation-data-type=uint8, transfer-property=TRIGGERED-ON-CHANGE
          signal CAN2_CS_VCU1_CAN2: start 7, 8 bit, big-endian, i-signal-type=PRIMITIVE, init-value=constant-reference=Init_CAN2_CS_VCU1_CAN2, base-type=uint8, implementation-data-type=uint8, transfer-property=PENDING
          signal CAN2_CoastDwModeStaChk: start 19, 2 bit, big-endian, i-signal-type=PRIMITIVE, init-value=constant-reference=Init_CAN2_CoastDwModeStaChk, base-type=uint8, implementation-data-type=uint8, transfer-property=PENDING
          signal CAN2_CreepSW_Sta: start 11, 1 bit, big-endian, i-signal-type=PRIMITIVE, init-value=constant-reference=Init_CAN2_CreepSW_Sta, base-type=uint8, implementation-data-type=uint8, transfer-property=TRIGGERED-ON-CHANGE
          signal CAN2_DCDCEnaReq: start 40, 1 bit, big-endian, i-signal-type=PRIMITIVE, init-value=constant-reference=Init_CAN2_DCDCEnaReq, base-type=uint8, implementation-data-type=uint8, transfer-property=TRIGGERED-ON-CHANGE
          signal CAN2_DCDCVoltSetpoint: start 55, 8 bit, big-endian, i-signal-type=PRIMITIVE, init-value=constant-reference=Init_CAN2_DCDCVoltSetpoint, base-type=uint8, implementation-data-type=uint8, transfer-property=TRIGGERED-ON-CHANGE
          signal CAN2_DemoModeStaChk: start 17, 2 bit, big-endian, i-signal-type=PRIMITIVE, init-value=constant-reference=Init_CAN2_DemoModeStaChk, base-type=uint8, implementation-data-type=uint8, transfer-property=PENDING
          signal CAN2_DisengageP_Fail: start 9, 1 bit, big-endian, i-signal-type=PRIMITIVE, init-value=constant-reference=Init_CAN2_DisengageP_Fail, base-type=uint8, implementation-data-type=uint8, transfer-property=TRIGGERED-ON-CHANGE
          signal CAN2_Dr_SeatSta: start 23, 2 bit, big-endian, i-signal-type=PRIMITIVE, init-value=constant-reference=Init_CAN2_Dr_SeatSta, base-type=uint8, implementation-data-type=uint8, transfer-property=PENDING
          signal CAN2_DynoModeStaChk: start 21, 2 bit, big-endian, i-signal-type=PRIMITIVE, init-value=constant-reference=Init_CAN2_DynoModeStaChk, base-type=uint8, implementation-data-type=uint8, transfer-property=PENDING
          signal CAN2_EngageP_Fail: start 10, 1 bit, big-endian, i-signal-type=PRIMITIVE, init-value=constant-reference=Init_CAN2_EngageP_Fail, base-type=uint8, implementation-data-type=uint8, transfer-property=TRIGGERED-ON-CHANGE
          signal CAN2_FDC_VCU_PwrSaveReq_Cmd: start 35, 1 bit, big-endian, i-signal-type=PRIMITIVE, init-value=constant-reference=Init_CAN2_FDC_VCU_PwrSaveReq_Cmd, base-type=uint8, implementation-data-type=uint8, transfer-property=TRIGGERED-ON-CHANGE
          signal CAN2_FalseNPrevent_Sta: start 8, 1 bit, big-endian, i-signal-type=PRIMITIVE, init-value=constant-reference=Init_CAN2_FalseNPrevent_Sta, base-type=uint8, implementation-data-type=uint8, transfer-property=TRIGGERED-ON-CHANGE
          signal CAN2_Fr_ActvDmpDisabReq: start 46, 1 bit, big-endian, i-signal-type=PRIMITIVE, init-value=constant-reference=Init_CAN2_Fr_ActvDmpDisabReq, base-type=uint8, implementation-data-type=uint8, transfer-property=TRIGGERED-ON-CHANGE
          signal CAN2_Fr_MCUEnaReq: start 41, 1 bit, big-endian, i-signal-type=PRIMITIVE, init-value=constant-reference=Init_CAN2_Fr_MCUEnaReq, base-type=uint8, implementation-data-type=uint8, transfer-property=TRIGGERED-ON-CHANGE
          signal CAN2_HVBatCnctReq: start 43, 1 bit, big-endian, i-signal-type=PRIMITIVE, init-value=constant-reference=Init_CAN2_HVBatCnctReq, base-type=uint8, implementation-data-type=uint8, transfer-property=TRIGGERED-ON-CHANGE
          signal CAN2_HVSysReadyToCharge: start 33, 2 bit, big-endian, i-signal-type=PRIMITIVE, init-value=constant-reference=Init_CAN2_HVSysReadyToCharge, base-type=uint8, implementation-data-type=uint8, transfer-property=TRIGGERED-ON-CHANGE
          signal CAN2_LVChrgFuncStaChk: start 25, 2 bit, big-endian, i-signal-type=PRIMITIVE, init-value=constant-reference=Init_CAN2_LVChrgFuncStaChk, base-type=uint8, implementation-data-type=uint8, transfer-property=PENDING
          signal CAN2_MSA_Crl_Sta: start 31, 3 bit, big-endian, i-signal-type=PRIMITIVE, init-value=constant-reference=Init_CAN2_MSA_Crl_Sta, base-type=uint8, implementation-data-type=uint8, transfer-property=TRIGGERED-ON-CHANGE
          signal CAN2_PrkReq: start 45, 1 bit, big-endian, i-signal-type=PRIMITIVE, init-value=constant-reference=Init_CAN2_PrkReq, base-type=uint8, implementation-data-type=uint8, transfer-property=TRIGGERED-ON-CHANGE
          signal CAN2_PwrSta: start 63, 3 bit, big-endian, i-signal-type=PRIMITIVE, init-value=constant-reference=Init_CAN2_PwrSta, base-type=uint8, implementation-data-type=uint8, transfer-property=TRIGGERED-ON-CHANGE
          signal CAN2_RC_VCU1_CAN2: start 15, 4 bit, big-endian, i-signal-type=PRIMITIVE, init-value=constant-reference=Init_CAN2_RC_VCU1_CAN2, base-type=uint8, implementation-data-type=uint8, transfer-property=PENDING
          signal CAN2_Rr_ActvDmpDisabReq: start 47, 1 bit, big-endian, i-signal-type=PRIMITIVE, init-value=constant-reference=Init_CAN2_Rr_ActvDmpDisabReq, base-type=uint8, implementation-data-type=uint8, transfer-property=TRIGGERED-ON-CHANGE
          signal CAN2_Rr_MCUEnaReq: start 42, 1 bit, big-endian, i-signal-type=PRIMITIVE, init-value=constant-reference=Init_CAN2_Rr_MCUEnaReq, base-type=uint8, implementation-data-type=uint8, transfer-property=TRIGGERED-ON-CHANGE
          signal CAN2_ShiftGearPosn: start 38, 3 bit, big-endian, i-signal-type=PRIMITIVE, init-value=constant-reference=Init_CAN2_ShiftGearPosn, base-type=uint8, implementation-data-type=uint8, transfer-property=TRIGGERED-ON-CHANGE
          signal CAN2_VCU_OPDHold: start 39, 1 bit, big-endian, i-signal-type=PRIMITIVE, init-value=constant-reference=Init_CAN2_VCU_OPDHold, base-type=uint8, implementation-data-type=uint8, transfer-property=PENDING
          signal CAN2_XWDMode: start 57, 2 bit, big-endian, i-signal-type=PRIMITIVE, init-value=constant-reference=Init_CAN2_XWDMode, base-type=uint8, implementation-data-type=uint8, transfer-property=TRIGGERED-ON-CHANGE
      frame CAN2_FD_VCU2: id 0x154, frame-length=16, can-addressing-mode=STANDARD, can-fd-frame-support=true, can-frame-rx-behavior=CAN-FD, can-frame-tx-behavior=CAN-FD
        pdu CAN2_FD_VCU2: length=16, minimum-delay=0.0, transmission-mode-true-timing=cyclic-timing=time-period=0.01, unused-bit-pattern=0
          mapping CAN2_SG_FD_VCU2: i-signal-group=CAN2_SG_FD_VCU2, start-position=0, transfer-property=PENDING
          signal CAN2_ACC_CtrlAvail: start 15, 1 bit, big-endian, i-signal-type=PRIMITIVE, init-value=constant-reference=Init_CAN2_ACC_CtrlAvail, base-type=uint8, implementation-data-type=uint8, transfer-property=PENDING
          signal CAN2_AccPedal_Override: start 14, 1 bit, big-endian, i-signal-type=PRIMITIVE, init-value=constant-reference=Init_CAN2_AccPedal_Override, base-type=uint8, implementation-data-type=uint8, transfer-property=PENDING
          signal CAN2_ActAPSPosn: start 127, 8 bit, big-endian, i-signal-type=PRIMITIVE, init-value=constant-reference=Init_CAN2_ActAPSPosn, base-type=uint8, implementation-data-type=uint8, transfer-property=PENDING
          signal CAN2_CS_VCU2_CAN1: start 7, 8 bit, big-endian, i-signal-type=PRIMITIVE, init-value=constant-reference=Init_CAN2_CS_VCU2_CAN1, base-type=uint8, implementation-data-type=uint8, transfer-property=PENDING
          signal CAN2_DriverTq: start 111, 16 bit, big-endian, i-signal-type=PRIMITIVE, init-value=constant-reference=Init_CAN2_DriverTq, base-type=uint16, implementation-data-type=uint16, transfer-property=PENDING
          signal CAN2_Fr_DriverTq: start 23, 16 bit, big-endian, i-signal-type=PRIMITIVE, init-value=constant-reference=Init_CAN2_Fr_DriverTq, base-type=uint16, implementation-data-type=uint16, transfer-property=PENDING
          signal CAN2_RC_VCU2_CAN1: start 11, 4 bit, big-endian, i-signal-type=PRIMITIVE, init-value=constant-reference=Init_CAN2_RC_VCU2_CAN1, base-type=uint8, implementation-data-type=uint8, transfer-property=PENDING
          signal CAN2_Rr_DriverTq: start 39, 16 bit, big-endian, i-signal-type=PRIMITIVE, init-value=constant-reference=Init_CAN2_Rr_DriverTq, base-type=uint16, implementation-data-type=uint16, transfer-property=PENDING
          signal CAN2_VehActPwr: start 87, 24 bit, big-endian, i-signal-type=PRIMITIVE, init-value=constant-reference=Init_CAN2_VehActPwr, base-type=uint32, implementation-data-type=uint32, transfer-property=PENDING
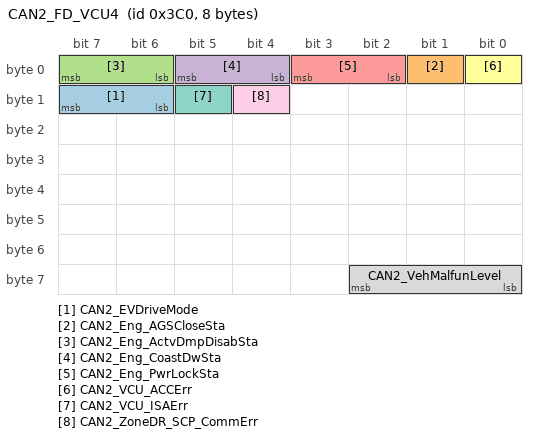
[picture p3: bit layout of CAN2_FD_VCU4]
      frame CAN2_FD_VCU4: id 0x3C0, frame-length=8, can-addressing-mode=STANDARD, can-fd-frame-support=true, can-frame-rx-behavior=CAN-FD, can-frame-tx-behavior=CAN-FD
        pdu CAN2_FD_VCU4: length=8, minimum-delay=0.0, transmission-mode-true-timing={cyclic-timing=time-period=0.2, event-controlled-timing={number-of-repetitions=0, repetition-period=0.05}}, unused-bit-pattern=0
          mapping CAN2_SG_FD_VCU4: i-signal-group=CAN2_SG_FD_VCU4, start-position=0, transfer-property=TRIGGERED-ON-CHANGE
          signal CAN2_EVDriveMode: start 15, 2 bit, big-endian, i-signal-type=PRIMITIVE, init-value=constant-reference=Init_CAN2_EVDriveMode, base-type=uint8, implementation-data-type=uint8, transfer-property=TRIGGERED-ON-CHANGE
          signal CAN2_Eng_AGSCloseSta: start 1, 1 bit, big-endian, i-signal-type=PRIMITIVE, init-value=constant-reference=Init_CAN2_Eng_AGSCloseSta, base-type=uint8, implementation-data-type=uint8, transfer-property=TRIGGERED-ON-CHANGE
          signal CAN2_Eng_ActvDmpDisabSta: start 7, 2 bit, big-endian, i-signal-type=PRIMITIVE, init-value=constant-reference=Init_CAN2_Eng_ActvDmpDisabSta, base-type=uint8, implementation-data-type=uint8, transfer-property=TRIGGERED-ON-CHANGE
          signal CAN2_Eng_CoastDwSta: start 5, 2 bit, big-endian, i-signal-type=PRIMITIVE, init-value=constant-reference=Init_CAN2_Eng_CoastDwSta, base-type=uint8, implementation-data-type=uint8, transfer-property=TRIGGERED-ON-CHANGE
          signal CAN2_Eng_PwrLockSta: start 3, 2 bit, big-endian, i-signal-type=PRIMITIVE, init-value=constant-reference=Init_CAN2_Eng_PwrLockSta, base-type=uint8, implementation-data-type=uint8, transfer-property=TRIGGERED-ON-CHANGE
          signal CAN2_VCU_ACCErr: start 0, 1 bit, big-endian, i-signal-type=PRIMITIVE, init-value=constant-reference=Init_CAN2_VCU_ACCErr, base-type=uint8, implementation-data-type=uint8, transfer-property=TRIGGERED-ON-CHANGE
          signal CAN2_VCU_ISAErr: start 13, 1 bit, big-endian, i-signal-type=PRIMITIVE, init-value=constant-reference=Init_CAN2_VCU_ISAErr, base-type=uint8, implementation-data-type=uint8, transfer-property=TRIGGERED-ON-CHANGE
          signal CAN2_VehMalfunLevel: start 58, 3 bit, big-endian, i-signal-type=PRIMITIVE, init-value=constant-reference=Init_CAN2_VehMalfunLevel, base-type=uint8, implementation-data-type=uint8, transfer-property=TRIGGERED-ON-CHANGE
          signal CAN2_ZoneDR_SCP_CommErr: start 12, 1 bit, big-endian, i-signal-type=PRIMITIVE, init-value=constant-reference=Init_CAN2_ZoneDR_SCP_CommErr, base-type=uint8, implementation-data-type=uint8, transfer-property=TRIGGERED-ON-CHANGE
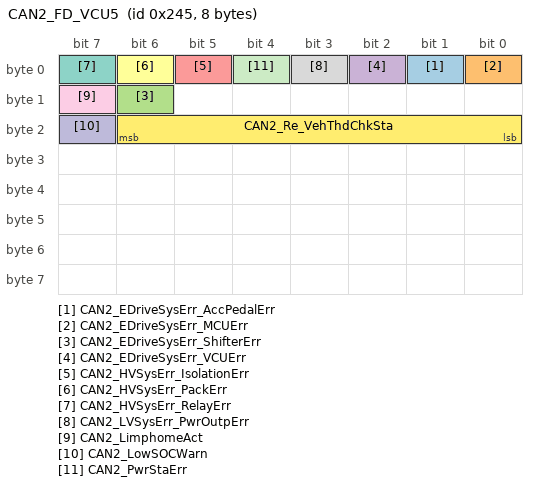
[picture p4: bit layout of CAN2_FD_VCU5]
      frame CAN2_FD_VCU5: id 0x245, frame-length=8, can-addressing-mode=STANDARD, can-fd-frame-support=true, can-frame-rx-behavior=CAN-FD, can-frame-tx-behavior=CAN-FD
        pdu CAN2_FD_VCU5: length=8, minimum-delay=0.0, transmission-mode-true-timing=cyclic-timing=time-period=0.5, unused-bit-pattern=0
          mapping CAN2_SG_FD_VCU5: i-signal-group=CAN2_SG_FD_VCU5, start-position=0, transfer-property=PENDING
          signal CAN2_EDriveSysErr_AccPedalErr: start 1, 1 bit, big-endian, i-signal-type=PRIMITIVE, init-value=constant-reference=Init_CAN2_EDriveSysErr_AccPedalErr, base-type=uint8, implementation-data-type=uint8, transfer-property=PENDING
          signal CAN2_EDriveSysErr_MCUErr: start 0, 1 bit, big-endian, i-signal-type=PRIMITIVE, init-value=constant-reference=Init_CAN2_EDriveSysErr_MCUErr, base-type=uint8, implementation-data-type=uint8, transfer-property=PENDING
          signal CAN2_EDriveSysErr_ShifterErr: start 14, 1 bit, big-endian, i-signal-type=PRIMITIVE, init-value=constant-reference=Init_CAN2_EDriveSysErr_ShifterErr, base-type=uint8, implementation-data-type=uint8, transfer-property=PENDING
          signal CAN2_EDriveSysErr_VCUErr: start 2, 1 bit, big-endian, i-signal-type=PRIMITIVE, init-value=constant-reference=Init_CAN2_EDriveSysErr_VCUErr, base-type=uint8, implementation-data-type=uint8, transfer-property=PENDING
          signal CAN2_HVSysErr_IsolationErr: start 5, 1 bit, big-endian, i-signal-type=PRIMITIVE, init-value=constant-reference=Init_CAN2_HVSysErr_IsolationErr, base-type=uint8, implementation-data-type=uint8, transfer-property=PENDING
          signal CAN2_HVSysErr_PackErr: start 6, 1 bit, big-endian, i-signal-type=PRIMITIVE, init-value=constant-reference=Init_CAN2_HVSysErr_PackErr, base-type=uint8, implementation-data-type=uint8, transfer-property=PENDING
          signal CAN2_HVSysErr_RelayErr: start 7, 1 bit, big-endian, i-signal-type=PRIMITIVE, init-value=constant-reference=Init_CAN2_HVSysErr_RelayErr, base-type=uint8, implementation-data-type=uint8, transfer-property=PENDING
          signal CAN2_LVSysErr_PwrOutpErr: start 3, 1 bit, big-endian, i-signal-type=PRIMITIVE, init-value=constant-reference=Init_CAN2_LVSysErr_PwrOutpErr, base-type=uint8, implementation-data-type=uint8, transfer-property=PENDING
          signal CAN2_LimphomeAct: start 15, 1 bit, big-endian, i-signal-type=PRIMITIVE, init-value=constant-reference=Init_CAN2_LimphomeAct, base-type=uint8, implementation-data-type=uint8, transfer-property=PENDING
          signal CAN2_LowSOCWarn: start 23, 1 bit, big-endian, i-signal-type=PRIMITIVE, init-value=constant-reference=Init_CAN2_LowSOCWarn, base-type=uint8, implementation-data-type=uint8, transfer-property=PENDING
          signal CAN2_PwrStaErr: start 4, 1 bit, big-endian, i-signal-type=PRIMITIVE, init-value=constant-reference=Init_CAN2_PwrStaErr, base-type=uint8, implementation-data-type=uint8, transfer-property=PENDING
          signal CAN2_Re_VehThdChkSta: start 22, 7 bit, big-endian, i-signal-type=PRIMITIVE, init-value=constant-reference=Init_CAN2_Re_VehThdChkSta, base-type=uint8, implementation-data-type=uint8, transfer-property=PENDING
      frame CAN2_FD_VCU6: id 0x3C3, frame-length=32, can-addressing-mode=STANDARD, can-fd-frame-support=true, can-frame-rx-behavior=CAN-FD, can-frame-tx-behavior=CAN-FD
        pdu CAN2_FD_VCU6: length=32, minimum-delay=0.0, transmission-mode-true-timing=cyclic-timing=time-period=5, unused-bit-pattern=0
          mapping CAN2_SG_FD_VCU6: i-signal-group=CAN2_SG_FD_VCU6, start-position=0, transfer-property=PENDING
          signal CAN2_FUSION_HW_Ver1: start 143, 8 bit, big-endian, i-signal-type=PRIMITIVE, init-value=constant-reference=Init_CAN2_FUSION_HW_Ver1, base-type=uint8, implementation-data-type=uint8, transfer-property=PENDING
          signal CAN2_FUSION_HW_Ver2: start 135, 8 bit, big-endian, i-signal-type=PRIMITIVE, init-value=constant-reference=Init_CAN2_FUSION_HW_Ver2, base-type=uint8, implementation-data-type=uint8, transfer-property=PENDING
          signal CAN2_FUSION_HW_Ver3: start 127, 8 bit, big-endian, i-signal-type=PRIMITIVE, init-value=constant-reference=Init_CAN2_FUSION_HW_Ver3, base-type=uint8, implementation-data-type=uint8, transfer-property=PENDING
          signal CAN2_FUSION_SW_CarModel1: start 119, 8 bit, big-endian, i-signal-type=PRIMITIVE, init-value=constant-reference=Init_CAN2_FUSION_SW_CarModel1, base-type=uint8, implementation-data-type=uint8, transfer-property=PENDING
          signal CAN2_FUSION_SW_CarModel2: start 111, 8 bit, big-endian, i-signal-type=PRIMITIVE, init-value=constant-reference=Init_CAN2_FUSION_SW_CarModel2, base-type=uint8, implementation-data-type=uint8, transfer-property=PENDING
          signal CAN2_FUSION_SW_CarModel3: start 103, 8 bit, big-endian, i-signal-type=PRIMITIVE, init-value=constant-reference=Init_CAN2_FUSION_SW_CarModel3, base-type=uint8, implementation-data-type=uint8, transfer-property=PENDING
          signal CAN2_FUSION_SW_Controller1: start 95, 8 bit, big-endian, i-signal-type=PRIMITIVE, init-value=constant-reference=Init_CAN2_FUSION_SW_Controller1, base-type=uint8, implementation-data-type=uint8, transfer-property=PENDING
          signal CAN2_FUSION_SW_Controller2: start 87, 8 bit, big-endian, i-signal-type=PRIMITIVE, init-value=constant-reference=Init_CAN2_FUSION_SW_Controller2, base-type=uint8, implementation-data-type=uint8, transfer-property=PENDING
          signal CAN2_FUSION_SW_Country1: start 31, 8 bit, big-endian, i-signal-type=PRIMITIVE, init-value=constant-reference=Init_CAN2_FUSION_SW_Country1, base-type=uint8, implementation-data-type=uint8, transfer-property=PENDING
          signal CAN2_FUSION_SW_Country2: start 23, 8 bit, big-endian, i-signal-type=PRIMITIVE, init-value=constant-reference=Init_CAN2_FUSION_SW_Country2, base-type=uint8, implementation-data-type=uint8, transfer-property=PENDING
          signal CAN2_FUSION_SW_Major1: start 79, 8 bit, big-endian, i-signal-type=PRIMITIVE, init-value=constant-reference=Init_CAN2_FUSION_SW_Major1, base-type=uint8, implementation-data-type=uint8, transfer-property=PENDING
          signal CAN2_FUSION_SW_Major2: start 71, 8 bit, big-endian, i-signal-type=PRIMITIVE, init-value=constant-reference=Init_CAN2_FUSION_SW_Major2, base-type=uint8, implementation-data-type=uint8, transfer-property=PENDING
          signal CAN2_FUSION_SW_Minor1: start 63, 8 bit, big-endian, i-signal-type=PRIMITIVE, init-value=constant-reference=Init_CAN2_FUSION_SW_Minor1, base-type=uint8, implementation-data-type=uint8, transfer-property=PENDING
          signal CAN2_FUSION_SW_Minor2: start 55, 8 bit, big-endian, i-signal-type=PRIMITIVE, init-value=constant-reference=Init_CAN2_FUSION_SW_Minor2, base-type=uint8, implementation-data-type=uint8, transfer-property=PENDING
          signal CAN2_FUSION_SW_Patch1: start 47, 8 bit, big-endian, i-signal-type=PRIMITIVE, init-value=constant-reference=Init_CAN2_FUSION_SW_Patch1, base-type=uint8, implementation-data-type=uint8, transfer-property=PENDING
          signal CAN2_FUSION_SW_Patch2: start 39, 8 bit, big-endian, i-signal-type=PRIMITIVE, init-value=constant-reference=Init_CAN2_FUSION_SW_Patch2, base-type=uint8, implementation-data-type=uint8, transfer-property=PENDING
          signal CAN2_FUSION_SW_SHA1: start 183, 8 bit, big-endian, i-signal-type=PRIMITIVE, init-value=constant-reference=Init_CAN2_FUSION_SW_SHA1, base-type=uint8, implementation-data-type=uint8, transfer-property=PENDING
          signal CAN2_FUSION_SW_SHA2: start 191, 8 bit, big-endian, i-signal-type=PRIMITIVE, init-value=constant-reference=Init_CAN2_FUSION_SW_SHA2, base-type=uint8, implementation-data-type=uint8, transfer-property=PENDING
          signal CAN2_FUSION_SW_SHA3: start 199, 8 bit, big-endian, i-signal-type=PRIMITIVE, init-value=constant-reference=Init_CAN2_FUSION_SW_SHA3, base-type=uint8, implementation-data-type=uint8, transfer-property=PENDING
          signal CAN2_FUSION_SW_SHA4: start 207, 8 bit, big-endian, i-signal-type=PRIMITIVE, init-value=constant-reference=Init_CAN2_FUSION_SW_SHA4, base-type=uint8, implementation-data-type=uint8, transfer-property=PENDING
          signal CAN2_FUSION_SW_SHA5: start 215, 8 bit, big-endian, i-signal-type=PRIMITIVE, init-value=constant-reference=Init_CAN2_FUSION_SW_SHA5, base-type=uint8, implementation-data-type=uint8, transfer-property=PENDING
          signal CAN2_FUSION_SW_SHA6: start 223, 8 bit, big-endian, i-signal-type=PRIMITIVE, init-value=constant-reference=Init_CAN2_FUSION_SW_SHA6, base-type=uint8, implementation-data-type=uint8, transfer-property=PENDING
          signal CAN2_FUSION_SW_SHA7: start 231, 8 bit, big-endian, i-signal-type=PRIMITIVE, init-value=constant-reference=Init_CAN2_FUSION_SW_SHA7, base-type=uint8, implementation-data-type=uint8, transfer-property=PENDING
          signal CAN2_FUSION_SW_SHA8: start 239, 8 bit, big-endian, i-signal-type=PRIMITIVE, init-value=constant-reference=Init_CAN2_FUSION_SW_SHA8, base-type=uint8, implementation-data-type=uint8, transfer-property=PENDING
          signal CAN2_FUSION_SW_Var: start 15, 8 bit, big-endian, i-signal-type=PRIMITIVE, init-value=constant-reference=Init_CAN2_FUSION_SW_Var, base-type=uint8, implementation-data-type=uint8, transfer-property=PENDING
          signal CAN2_FUSION_SW_change1: start 159, 8 bit, big-endian, i-signal-type=PRIMITIVE, init-value=constant-reference=Init_CAN2_FUSION_SW_change1, base-type=uint8, implementation-data-type=uint8, transfer-property=PENDING
          signal CAN2_FUSION_SW_change2: start 167, 8 bit, big-endian, i-signal-type=PRIMITIVE, init-value=constant-reference=Init_CAN2_FUSION_SW_change2, base-type=uint8, implementation-data-type=uint8, transfer-property=PENDING
          signal CAN2_FUSION_SW_dash1: start 151, 8 bit, big-endian, i-signal-type=PRIMITIVE, init-value=constant-reference=Init_CAN2_FUSION_SW_dash1, base-type=uint8, implementation-data-type=uint8, transfer-property=PENDING
          signal CAN2_FUSION_SW_dash2: start 175, 8 bit, big-endian, i-signal-type=PRIMITIVE, init-value=constant-reference=Init_CAN2_FUSION_SW_dash2, base-type=uint8, implementation-data-type=uint8, transfer-property=PENDING
      frame CAN2_FD_VMC1: id 0x17F, frame-length=8, can-addressing-mode=STANDARD, can-fd-frame-support=true, can-frame-rx-behavior=CAN-FD, can-frame-tx-behavior=CAN-FD
        pdu CAN2_FD_VMC1: length=8, minimum-delay=0.0, transmission-mode-true-timing={cyclic-timing=time-period=0.1, event-controlled-timing={number-of-repetitions=0, repetition-period=0}}, unused-bit-pattern=0
          mapping CAN2_SG_FD_VMC1: i-signal-group=CAN2_SG_FD_VMC1, start-position=0, transfer-property=TRIGGERED-ON-CHANGE
          signal CAN2_CCMSA_SpdWar: start 5, 1 bit, big-endian, i-signal-type=PRIMITIVE, init-value=constant-reference=Init_CAN2_CCMSA_SpdWar, base-type=uint8, implementation-data-type=uint8, transfer-property=TRIGGERED-ON-CHANGE
      frame CAN2_IVI1: id 0x490, frame-length=8, can-addressing-mode=STANDARD, can-fd-frame-support=true, can-frame-rx-behavior=CAN-FD, can-frame-tx-behavior=CAN-FD
        pdu CAN2_IVI1: length=8, minimum-delay=0.0, transmission-mode-true-timing={cyclic-timing=time-period=0.5, event-controlled-timing={number-of-repetitions=0, repetition-period=0.05}}, unused-bit-pattern=0
          mapping CAN2_SG_IVI1: i-signal-group=CAN2_SG_IVI1, start-position=0, transfer-property=TRIGGERED-ON-CHANGE
          signal CAN2_AmbLightColorSet: start 21, 6 bit, big-endian, i-signal-type=PRIMITIVE, init-value=constant-reference=Init_CAN2_AmbLightColorSet, base-type=uint8, implementation-data-type=uint8, transfer-property=TRIGGERED-ON-CHANGE
          signal CAN2_AmbLightUserSet: start 34, 3 bit, big-endian, i-signal-type=PRIMITIVE, init-value=constant-reference=Init_CAN2_AmbLightUserSet, base-type=uint8, implementation-data-type=uint8, transfer-property=TRIGGERED-ON-CHANGE
          signal CAN2_BrkAbn_GoReady_SW: start 37, 1 bit, big-endian, i-signal-type=PRIMITIVE, init-value=constant-reference=Init_CAN2_BrkAbn_GoReady_SW, base-type=uint8, implementation-data-type=uint8, transfer-property=TRIGGERED-ON-CHANGE
          signal CAN2_DRAmbLightBrightnessSet: start 46, 7 bit, big-endian, i-signal-type=PRIMITIVE, init-value=constant-reference=Init_CAN2_DRAmbLightBrightnessSet, base-type=uint8, implementation-data-type=uint8, transfer-property=TRIGGERED-ON-CHANGE
          signal CAN2_FCP_FrEvt_BtnACMaxReq: start 4, 1 bit, big-endian, i-signal-type=PRIMITIVE, init-value=constant-reference=Init_CAN2_FCP_FrEvt_BtnACMaxReq, base-type=uint8, implementation-data-type=uint8, transfer-property=TRIGGERED-ON-CHANGE
          signal CAN2_FCP_FrEvt_BtnACReq: start 3, 1 bit, big-endian, i-signal-type=PRIMITIVE, init-value=constant-reference=Init_CAN2_FCP_FrEvt_BtnACReq, base-type=uint8, implementation-data-type=uint8, transfer-property=TRIGGERED-ON-CHANGE
          signal CAN2_FCP_FrEvt_BtnAutoReq: start 2, 1 bit, big-endian, i-signal-type=PRIMITIVE, init-value=constant-reference=Init_CAN2_FCP_FrEvt_BtnAutoReq, base-type=uint8, implementation-data-type=uint8, transfer-property=TRIGGERED-ON-CHANGE
          signal CAN2_FCP_FrEvt_BtnSyncReq: start 0, 1 bit, big-endian, i-signal-type=PRIMITIVE, init-value=constant-reference=Init_CAN2_FCP_FrEvt_BtnSyncReq, base-type=uint8, implementation-data-type=uint8, transfer-property=TRIGGERED-ON-CHANGE
          signal CAN2_FCP_MidEvt_BtnAutoReq: start 1, 1 bit, big-endian, i-signal-type=PRIMITIVE, init-value=constant-reference=Init_CAN2_FCP_MidEvt_BtnAutoReq, base-type=uint8, implementation-data-type=uint8, transfer-property=TRIGGERED-ON-CHANGE
          signal CAN2_IPAmbLightBrightnessSet: start 30, 7 bit, big-endian, i-signal-type=PRIMITIVE, init-value=constant-reference=Init_CAN2_IPAmbLightBrightnessSet, base-type=uint8, implementation-data-type=uint8, transfer-property=TRIGGERED-ON-CHANGE
          signal CAN2_IVI_Lock_SoundSW_Sta: start 35, 1 bit, big-endian, i-signal-type=PRIMITIVE, init-value=constant-reference=Init_CAN2_IVI_Lock_SoundSW_Sta, base-type=uint8, implementation-data-type=uint8, transfer-property=TRIGGERED-ON-CHANGE
          signal CAN2_IVI_OTA_Upd_Sta: start 12, 2 bit, big-endian, i-signal-type=PRIMITIVE, init-value=constant-reference=Init_CAN2_IVI_OTA_Upd_Sta, base-type=uint8, implementation-data-type=uint8, transfer-property=TRIGGERED-ON-CHANGE
          signal CAN2_LINKtoDrive: start 8, 1 bit, big-endian, i-signal-type=PRIMITIVE, init-value=constant-reference=Init_CAN2_LINKtoDrive, base-type=uint8, implementation-data-type=uint8, transfer-property=TRIGGERED-ON-CHANGE
          signal CAN2_OTA_CancelDL_Req: start 10, 1 bit, big-endian, i-signal-type=PRIMITIVE, init-value=constant-reference=Init_CAN2_OTA_CancelDL_Req, base-type=uint8, implementation-data-type=uint8, transfer-property=TRIGGERED-ON-CHANGE
          signal CAN2_OTA_CompNTFY_Pres: start 9, 1 bit, big-endian, i-signal-type=PRIMITIVE, init-value=constant-reference=Init_CAN2_OTA_CompNTFY_Pres, base-type=uint8, implementation-data-type=uint8, transfer-property=TRIGGERED-ON-CHANGE
          signal CAN2_OTA_DL_Req: start 15, 1 bit, big-endian, i-signal-type=PRIMITIVE, init-value=constant-reference=Init_CAN2_OTA_DL_Req, base-type=uint8, implementation-data-type=uint8, transfer-property=TRIGGERED-ON-CHANGE
          signal CAN2_OTA_SuspendDL_Req: start 14, 1 bit, big-endian, i-signal-type=PRIMITIVE, init-value=constant-reference=Init_CAN2_OTA_SuspendDL_Req, base-type=uint8, implementation-data-type=uint8, transfer-property=TRIGGERED-ON-CHANGE
          signal CAN2_OTA_UpdStart_Req: start 13, 1 bit, big-endian, i-signal-type=PRIMITIVE, init-value=constant-reference=Init_CAN2_OTA_UpdStart_Req, base-type=uint8, implementation-data-type=uint8, transfer-property=TRIGGERED-ON-CHANGE
          signal CAN2_OpenDrOpenWdo_SW: start 36, 1 bit, big-endian, i-signal-type=PRIMITIVE, init-value=constant-reference=Init_CAN2_OpenDrOpenWdo_SW, base-type=uint8, implementation-data-type=uint8, transfer-property=TRIGGERED-ON-CHANGE
          signal CAN2_PW_CLOSE_IMD: start 38, 1 bit, big-endian, i-signal-type=PRIMITIVE, init-value=constant-reference=Init_CAN2_PW_CLOSE_IMD, base-type=uint8, implementation-data-type=uint8, transfer-property=TRIGGERED-ON-CHANGE
          signal CAN2_PW_CONTINUE_USE: start 39, 1 bit, big-endian, i-signal-type=PRIMITIVE, init-value=constant-reference=Init_CAN2_PW_CONTINUE_USE, base-type=uint8, implementation-data-type=uint8, transfer-property=TRIGGERED-ON-CHANGE
          signal CAN2_Sched_OTA_wake: start 31, 1 bit, big-endian, i-signal-type=PRIMITIVE, init-value=constant-reference=Init_CAN2_Sched_OTA_wake, base-type=uint8, implementation-data-type=uint8, transfer-property=TRIGGERED-ON-CHANGE
          signal CAN2_SmartEco_Mode_SW: start 47, 1 bit, big-endian, i-signal-type=PRIMITIVE, init-value=constant-reference=Init_CAN2_SmartEco_Mode_SW, base-type=uint8, implementation-data-type=uint8, transfer-property=TRIGGERED-ON-CHANGE
          signal CAN2_Upd_Countdown_Cancel: start 22, 1 bit, big-endian, i-signal-type=PRIMITIVE, init-value=constant-reference=Init_CAN2_Upd_Countdown_Cancel, base-type=uint8, implementation-data-type=uint8, transfer-property=TRIGGERED-ON-CHANGE
          signal CAN2_Upd_Countdown_Skip: start 23, 1 bit, big-endian, i-signal-type=PRIMITIVE, init-value=constant-reference=Init_CAN2_Upd_Countdown_Skip, base-type=uint8, implementation-data-type=uint8, transfer-property=TRIGGERED-ON-CHANGE
          signal CAN2_VehACModReq: start 7, 3 bit, big-endian, i-signal-type=PRIMITIVE, init-value=constant-reference=Init_CAN2_VehACModReq, base-type=uint8, implementation-data-type=uint8, transfer-property=TRIGGERED-ON-CHANGE
      frame CAN2_IVI2: id 0x495, frame-length=64, can-addressing-mode=STANDARD, can-fd-frame-support=true, can-frame-rx-behavior=CAN-FD, can-frame-tx-behavior=CAN-FD
        pdu CAN2_IVI2: length=64, minimum-delay=0.0, transmission-mode-true-timing={cyclic-timing=time-period=0.2, event-controlled-timing={number-of-repetitions=0, repetition-period=0.02}}, unused-bit-pattern=0
          mapping CAN2_SG_IVI2: i-signal-group=CAN2_SG_IVI2, start-position=0, transfer-property=TRIGGERED-ON-CHANGE
          signal CAN2_AC_Chg_Cur_Set: start 462, 7 bit, big-endian, i-signal-type=PRIMITIVE, init-value=constant-reference=Init_CAN2_AC_Chg_Cur_Set, base-type=uint8, implementation-data-type=uint8, transfer-property=TRIGGERED-ON-CHANGE
          signal CAN2_AEB_BUTT: start 209, 2 bit, big-endian, i-signal-type=PRIMITIVE, init-value=constant-reference=Init_CAN2_AEB_BUTT, base-type=uint8, implementation-data-type=uint8, transfer-property=PENDING
          signal CAN2_AVM_Err_STA: start 399, 1 bit, big-endian, i-signal-type=PRIMITIVE, init-value=constant-reference=Init_CAN2_AVM_Err_STA, base-type=uint8, implementation-data-type=uint8, transfer-property=PENDING
          signal CAN2_AVM_OFF_Rec_Butt: start 508, 1 bit, big-endian, i-signal-type=PRIMITIVE, init-value=constant-reference=Init_CAN2_AVM_OFF_Rec_Butt, base-type=uint8, implementation-data-type=uint8, transfer-property=TRIGGERED-ON-CHANGE
          signal CAN2_AVM_Parking_mode: start 407, 4 bit, big-endian, i-signal-type=PRIMITIVE, init-value=constant-reference=Init_CAN2_AVM_Parking_mode, base-type=uint8, implementation-data-type=uint8, transfer-property=PENDING
          signal CAN2_AVM_parking_cancel: start 505, 2 bit, big-endian, i-signal-type=PRIMITIVE, init-value=constant-reference=Init_CAN2_AVM_parking_cancel, base-type=uint8, implementation-data-type=uint8, transfer-property=TRIGGERED-ON-CHANGE
          signal CAN2_AVM_parking_excute: start 507, 2 bit, big-endian, i-signal-type=PRIMITIVE, init-value=constant-reference=Init_CAN2_AVM_parking_excute, base-type=uint8, implementation-data-type=uint8, transfer-property=TRIGGERED-ON-CHANGE
          signal CAN2_Approach_Unlock_SW: start 9, 1 bit, big-endian, i-signal-type=PRIMITIVE, init-value=constant-reference=Init_CAN2_Approach_Unlock_SW, base-type=uint8, implementation-data-type=uint8, transfer-property=TRIGGERED-ON-CHANGE
          signal CAN2_BSDMute_BUTT: start 225, 2 bit, big-endian, i-signal-type=PRIMITIVE, init-value=constant-reference=Init_CAN2_BSDMute_BUTT, base-type=uint8, implementation-data-type=uint8, transfer-property=PENDING
          signal CAN2_CAAS_Sw: start 353, 2 bit, big-endian, i-signal-type=PRIMITIVE, init-value=constant-reference=Init_CAN2_CAAS_Sw, base-type=uint8, implementation-data-type=uint8, transfer-property=TRIGGERED-ON-CHANGE
          signal CAN2_CDL_Lock_Butt: start 469, 1 bit, big-endian, i-signal-type=PRIMITIVE, init-value=constant-reference=Init_CAN2_CDL_Lock_Butt, base-type=uint8, implementation-data-type=uint8, transfer-property=TRIGGERED-ON-CHANGE
          signal CAN2_CDL_Unlock_Butt: start 470, 1 bit, big-endian, i-signal-type=PRIMITIVE, init-value=constant-reference=Init_CAN2_CDL_Unlock_Butt, base-type=uint8, implementation-data-type=uint8, transfer-property=TRIGGERED-ON-CHANGE
          signal CAN2_CameraWrn: start 286, 1 bit, big-endian, i-signal-type=PRIMITIVE, init-value=constant-reference=Init_CAN2_CameraWrn, base-type=uint8, implementation-data-type=uint8, transfer-property=PENDING
          signal CAN2_DSEAT_anti_set: start 355, 1 bit, big-endian, i-signal-type=PRIMITIVE, init-value=constant-reference=Init_CAN2_DSEAT_anti_set, base-type=uint8, implementation-data-type=uint8, transfer-property=PENDING
          signal CAN2_DSEAT_entryfun_set: start 354, 1 bit, big-endian, i-signal-type=PRIMITIVE, init-value=constant-reference=Init_CAN2_DSEAT_entryfun_set, base-type=uint8, implementation-data-type=uint8, transfer-property=PENDING
          signal CAN2_DSEAT_vent_req: start 342, 3 bit, big-endian, i-signal-type=PRIMITIVE, init-value=constant-reference=Init_CAN2_DSEAT_vent_req, base-type=uint8, implementation-data-type=uint8, transfer-property=PENDING
          signal CAN2_Distance_unit: start 243, 1 bit, big-endian, i-signal-type=PRIMITIVE, init-value=constant-reference=Init_CAN2_Distance_unit, base-type=uint8, implementation-data-type=uint8, transfer-property=PENDING
          signal CAN2_ESC_SW_Cmd: start 245, 2 bit, big-endian, i-signal-type=PRIMITIVE, init-value=constant-reference=Init_CAN2_ESC_SW_Cmd, base-type=uint8, implementation-data-type=uint8, transfer-property=TRIGGERED-ON-CHANGE
          signal CAN2_FCWMute_BUTT: start 233, 2 bit, big-endian, i-signal-type=PRIMITIVE, init-value=constant-reference=Init_CAN2_FCWMute_BUTT, base-type=uint8, implementation-data-type=uint8, transfer-property=PENDING
          signal CAN2_FFogLampSW: start 339, 1 bit, big-endian, i-signal-type=PRIMITIVE, init-value=constant-reference=Init_CAN2_FFogLampSW, base-type=uint8, implementation-data-type=uint8, transfer-property=PENDING
          signal CAN2_FS_Off_Sw: start 351, 2 bit, big-endian, i-signal-type=PRIMITIVE, init-value=constant-reference=Init_CAN2_FS_Off_Sw, base-type=uint8, implementation-data-type=uint8, transfer-property=PENDING
          signal CAN2_FalseNPrevent_SW: start 10, 1 bit, big-endian, i-signal-type=PRIMITIVE, init-value=constant-reference=Init_CAN2_FalseNPrevent_SW, base-type=uint8, implementation-data-type=uint8, transfer-property=PENDING
          signal CAN2_FollowMeSW: start 358, 1 bit, big-endian, i-signal-type=PRIMITIVE, init-value=constant-reference=Init_CAN2_FollowMeSW, base-type=uint8, implementation-data-type=uint8, transfer-property=PENDING
          signal CAN2_GPS_LAT: start 167, 32 bit, big-endian, i-signal-type=PRIMITIVE, init-value=constant-reference=Init_CAN2_GPS_LAT, base-type=uint32, implementation-data-type=uint32, transfer-property=PENDING
          signal CAN2_GPS_LONG: start 135, 32 bit, big-endian, i-signal-type=PRIMITIVE, init-value=constant-reference=Init_CAN2_GPS_LONG, base-type=uint32, implementation-data-type=uint32, transfer-property=PENDING
          signal CAN2_HeadLampSW: start 321, 2 bit, big-endian, i-signal-type=PRIMITIVE, init-value=constant-reference=Init_CAN2_HeadLampSW, base-type=uint8, implementation-data-type=uint8, transfer-property=TRIGGERED-ON-CHANGE
          signal CAN2_Hood_Latch_SW: start 393, 2 bit, big-endian, i-signal-type=PRIMITIVE, init-value=constant-reference=Init_CAN2_Hood_Latch_SW, base-type=uint8, implementation-data-type=uint8, transfer-property=PENDING
          signal CAN2_IVI_AGSCloseSW: start 511, 2 bit, big-endian, i-signal-type=PRIMITIVE, init-value=constant-reference=Init_CAN2_IVI_AGSCloseSW, base-type=uint8, implementation-data-type=uint8, transfer-property=TRIGGERED-ON-CHANGE
          signal CAN2_IVI_ActvDmpDisabSW: start 503, 2 bit, big-endian, i-signal-type=PRIMITIVE, init-value=constant-reference=Init_CAN2_IVI_ActvDmpDisabSW, base-type=uint8, implementation-data-type=uint8, transfer-property=TRIGGERED-ON-CHANGE
          signal CAN2_IVI_CoastDwSW: start 501, 2 bit, big-endian, i-signal-type=PRIMITIVE, init-value=constant-reference=Init_CAN2_IVI_CoastDwSW, base-type=uint8, implementation-data-type=uint8, transfer-property=TRIGGERED-ON-CHANGE
          signal CAN2_IVI_CreepSW_Req: start 11, 1 bit, big-endian, i-signal-type=PRIMITIVE, init-value=constant-reference=Init_CAN2_IVI_CreepSW_Req, base-type=uint8, implementation-data-type=uint8, transfer-property=TRIGGERED-ON-CHANGE
          signal CAN2_IVI_ISA_OffsetSpd: start 451, 4 bit, big-endian, i-signal-type=PRIMITIVE, init-value=constant-reference=Init_CAN2_IVI_ISA_OffsetSpd, base-type=uint8, implementation-data-type=uint8, transfer-property=PENDING
          signal CAN2_IVI_LVChrgFuncSW: start 497, 2 bit, big-endian, i-signal-type=PRIMITIVE, init-value=constant-reference=Init_CAN2_IVI_LVChrgFuncSW, base-type=uint8, implementation-data-type=uint8, transfer-property=TRIGGERED-ON-CHANGE
          signal CAN2_IVI_Mute_Sta: start 360, 1 bit, big-endian, i-signal-type=PRIMITIVE, init-value=constant-reference=Init_CAN2_IVI_Mute_Sta, base-type=uint8, implementation-data-type=uint8, transfer-property=PENDING
          signal CAN2_IVI_Night_Mode_Sta: start 364, 1 bit, big-endian, i-signal-type=PRIMITIVE, init-value=constant-reference=Init_CAN2_IVI_Night_Mode_Sta, base-type=uint8, implementation-data-type=uint8, transfer-property=PENDING
          signal CAN2_IVI_PTG_Mode_SW: start 345, 2 bit, big-endian, i-signal-type=PRIMITIVE, init-value=constant-reference=Init_CAN2_IVI_PTG_Mode_SW, base-type=uint8, implementation-data-type=uint8, transfer-property=TRIGGERED-ON-CHANGE
          signal CAN2_IVI_PTG_Open_Height: start 14, 3 bit, big-endian, i-signal-type=PRIMITIVE, init-value=constant-reference=Init_CAN2_IVI_PTG_Open_Height, base-type=uint8, implementation-data-type=uint8, transfer-property=TRIGGERED-ON-CHANGE
          signal CAN2_IVI_PTG_Sta_SW: start 347, 2 bit, big-endian, i-signal-type=PRIMITIVE, init-value=constant-reference=Init_CAN2_IVI_PTG_Sta_SW, base-type=uint8, implementation-data-type=uint8, transfer-property=TRIGGERED-ON-CHANGE
          signal CAN2_IVI_PTG_USSta_SW: start 361, 1 bit, big-endian, i-signal-type=PRIMITIVE, init-value=constant-reference=Init_CAN2_IVI_PTG_USSta_SW, base-type=uint8, implementation-data-type=uint8, transfer-property=PENDING
          signal CAN2_IVI_PW_Mode_Req: start 284, 2 bit, big-endian, i-signal-type=PRIMITIVE, init-value=constant-reference=Init_CAN2_IVI_PW_Mode_Req, base-type=uint8, implementation-data-type=uint8, transfer-property=PENDING
          signal CAN2_IVI_Panel_Act: start 246, 1 bit, big-endian, i-signal-type=PRIMITIVE, init-value=constant-reference=Init_CAN2_IVI_Panel_Act, base-type=uint8, implementation-data-type=uint8, transfer-property=PENDING
          signal CAN2_IVI_Panel_X_Coor: start 303, 12 bit, big-endian, i-signal-type=PRIMITIVE, init-value=constant-reference=Init_CAN2_IVI_Panel_X_Coor, base-type=uint16, implementation-data-type=uint16, transfer-property=PENDING
          signal CAN2_IVI_Panel_Y_Coor: start 307, 12 bit, big-endian, i-signal-type=PRIMITIVE, init-value=constant-reference=Init_CAN2_IVI_Panel_Y_Coor, base-type=uint16, implementation-data-type=uint16, transfer-property=PENDING
          signal CAN2_IVI_PwrLockSW: start 499, 2 bit, big-endian, i-signal-type=PRIMITIVE, init-value=constant-reference=Init_CAN2_IVI_PwrLockSW, base-type=uint8, implementation-data-type=uint8, transfer-property=TRIGGERED-ON-CHANGE
          signal CAN2_IVI_Pwroff_req: start 397, 1 bit, big-endian, i-signal-type=PRIMITIVE, init-value=constant-reference=Init_CAN2_IVI_Pwroff_req, base-type=uint8, implementation-data-type=uint8, transfer-property=PENDING
          signal CAN2_IVI_RR_Def_Req: start 363, 1 bit, big-endian, i-signal-type=PRIMITIVE, init-value=constant-reference=Init_CAN2_IVI_RR_Def_Req, base-type=uint8, implementation-data-type=uint8, transfer-property=TRIGGERED-ON-CHANGE
          signal CAN2_IVI_Req_V2L: start 15, 1 bit, big-endian, i-signal-type=PRIMITIVE, init-value=constant-reference=Init_CAN2_IVI_Req_V2L, base-type=uint8, implementation-data-type=uint8, transfer-property=PENDING
          signal CAN2_IVI_Screen: start 269, 6 bit, big-endian, i-signal-type=PRIMITIVE, init-value=constant-reference=Init_CAN2_IVI_Screen, base-type=uint8, implementation-data-type=uint8, transfer-property=PENDING
          signal CAN2_IVI_Start_Chg_req: start 103, 1 bit, big-endian, i-signal-type=PRIMITIVE, init-value=constant-reference=Init_CAN2_IVI_Start_Chg_req, base-type=uint8, implementation-data-type=uint8, transfer-property=PENDING
          signal CAN2_IVI_Status: start 365, 1 bit, big-endian, i-signal-type=PRIMITIVE, init-value=constant-reference=Init_CAN2_IVI_Status, base-type=uint8, implementation-data-type=uint8, transfer-property=PENDING
          signal CAN2_IVI_Stop_Chg_req: start 111, 1 bit, big-endian, i-signal-type=PRIMITIVE, init-value=constant-reference=Init_CAN2_IVI_Stop_Chg_req, base-type=uint8, implementation-data-type=uint8, transfer-property=PENDING
          signal CAN2_IVI_Trigger_req: start 398, 1 bit, big-endian, i-signal-type=PRIMITIVE, init-value=constant-reference=Init_CAN2_IVI_Trigger_req, base-type=uint8, implementation-data-type=uint8, transfer-property=PENDING
          signal CAN2_IVI_Unlock_Chg_req: start 119, 1 bit, big-endian, i-signal-type=PRIMITIVE, init-value=constant-reference=Init_CAN2_IVI_Unlock_Chg_req, base-type=uint8, implementation-data-type=uint8, transfer-property=PENDING
          signal CAN2_IVI_WI_MAIN_SW: start 362, 1 bit, big-endian, i-signal-type=PRIMITIVE, init-value=constant-reference=Init_CAN2_IVI_WI_MAIN_SW, base-type=uint8, implementation-data-type=uint8, transfer-property=PENDING
          signal CAN2_LDWMute_BUTT: start 239, 2 bit, big-endian, i-signal-type=PRIMITIVE, init-value=constant-reference=Init_CAN2_LDWMute_BUTT, base-type=uint8, implementation-data-type=uint8, transfer-property=PENDING
          signal CAN2_LKA_BUTT: start 235, 2 bit, big-endian, i-signal-type=PRIMITIVE, init-value=constant-reference=Init_CAN2_LKA_BUTT, base-type=uint8, implementation-data-type=uint8, transfer-property=PENDING
          signal CAN2_LVDAMute_BUTT: start 367, 2 bit, big-endian, i-signal-type=PRIMITIVE, init-value=constant-reference=Init_CAN2_LVDAMute_BUTT, base-type=uint8, implementation-data-type=uint8, transfer-property=PENDING
          signal CAN2_L_Drv_ControlCommand: start 126, 7 bit, big-endian, i-signal-type=PRIMITIVE, init-value=constant-reference=Init_CAN2_L_Drv_ControlCommand, base-type=uint8, implementation-data-type=uint8, transfer-property=PENDING
          signal CAN2_L_Pas_ControlCommand: start 118, 7 bit, big-endian, i-signal-type=PRIMITIVE, init-value=constant-reference=Init_CAN2_L_Pas_ControlCommand, base-type=uint8, implementation-data-type=uint8, transfer-property=PENDING
          signal CAN2_L_RLD_ControlCommand: start 110, 7 bit, big-endian, i-signal-type=PRIMITIVE, init-value=constant-reference=Init_CAN2_L_RLD_ControlCommand, base-type=uint8, implementation-data-type=uint8, transfer-property=PENDING
          signal CAN2_L_RRD_ControlCommand: start 102, 7 bit, big-endian, i-signal-type=PRIMITIVE, init-value=constant-reference=Init_CAN2_L_RRD_ControlCommand, base-type=uint8, implementation-data-type=uint8, transfer-property=PENDING
          signal CAN2_METER_Malfunc_Sta: start 89, 2 bit, big-endian, i-signal-type=PRIMITIVE, init-value=constant-reference=Init_CAN2_METER_Malfunc_Sta, base-type=uint8, implementation-data-type=uint8, transfer-property=PENDING
          signal CAN2_MFRD_N_Bright_Req: start 334, 7 bit, big-endian, i-signal-type=PRIMITIVE, init-value=constant-reference=Init_CAN2_MFRD_N_Bright_Req, base-type=uint8, implementation-data-type=uint8, transfer-property=TRIGGERED-ON-CHANGE
          signal CAN2_NAVI_Cam_Dist_info: start 295, 8 bit, big-endian, i-signal-type=PRIMITIVE, init-value=constant-reference=Init_CAN2_NAVI_Cam_Dist_info, base-type=uint8, implementation-data-type=uint8, transfer-property=PENDING
          signal CAN2_NAVI_Direction_STA: start 279, 8 bit, big-endian, i-signal-type=PRIMITIVE, init-value=constant-reference=Init_CAN2_NAVI_Direction_STA, base-type=uint8, implementation-data-type=uint8, transfer-property=PENDING
          signal CAN2_NAVI_Distance_info: start 375, 24 bit, big-endian, i-signal-type=PRIMITIVE, init-value=constant-reference=Init_CAN2_NAVI_Distance_info, base-type=uint32, implementation-data-type=uint32, transfer-property=PENDING
          signal CAN2_NAVI_ForwardLinkLevel: start 415, 4 bit, big-endian, i-signal-type=PRIMITIVE, init-value=constant-reference=Init_CAN2_NAVI_ForwardLinkLevel, base-type=uint8, implementation-data-type=uint8, transfer-property=PENDING
          signal CAN2_NAVI_LinkClass: start 431, 4 bit, big-endian, i-signal-type=PRIMITIVE, init-value=constant-reference=Init_CAN2_NAVI_LinkClass, base-type=uint8, implementation-data-type=uint8, transfer-property=PENDING
          signal CAN2_NAVI_RoadClass: start 447, 3 bit, big-endian, i-signal-type=PRIMITIVE, init-value=constant-reference=Init_CAN2_NAVI_RoadClass, base-type=uint8, implementation-data-type=uint8, transfer-property=PENDING
          signal CAN2_NAVI_SpeedLimit: start 444, 5 bit, big-endian, i-signal-type=PRIMITIVE, init-value=constant-reference=Init_CAN2_NAVI_SpeedLimit, base-type=uint8, implementation-data-type=uint8, transfer-property=PENDING
          signal CAN2_NAVI_Speed_Limit_A: start 241, 2 bit, big-endian, i-signal-type=PRIMITIVE, init-value=constant-reference=Init_CAN2_NAVI_Speed_Limit_A, base-type=uint8, implementation-data-type=uint8, transfer-property=PENDING
          signal CAN2_NAVI_State: start 323, 2 bit, big-endian, i-signal-type=PRIMITIVE, init-value=constant-reference=Init_CAN2_NAVI_State, base-type=uint8, implementation-data-type=uint8, transfer-property=PENDING
          signal CAN2_NAVI_Tollgate: start 427, 12 bit, big-endian, i-signal-type=PRIMITIVE, init-value=constant-reference=Init_CAN2_NAVI_Tollgate, base-type=uint16, implementation-data-type=uint16, transfer-property=PENDING
          signal CAN2_NAVI_Tunnel: start 411, 12 bit, big-endian, i-signal-type=PRIMITIVE, init-value=constant-reference=Init_CAN2_NAVI_Tunnel, base-type=uint16, implementation-data-type=uint16, transfer-property=PENDING
          signal CAN2_ODAMute_BUTT: start 237, 2 bit, big-endian, i-signal-type=PRIMITIVE, init-value=constant-reference=Init_CAN2_ODAMute_BUTT, base-type=uint8, implementation-data-type=uint8, transfer-property=PENDING
          signal CAN2_OFF_AC_MODE: start 282, 3 bit, big-endian, i-signal-type=PRIMITIVE, init-value=constant-reference=Init_CAN2_OFF_AC_MODE, base-type=uint8, implementation-data-type=uint8, transfer-property=TRIGGERED-ON-CHANGE
          signal CAN2_PSEAT_vent_req: start 338, 3 bit, big-endian, i-signal-type=PRIMITIVE, init-value=constant-reference=Init_CAN2_PSEAT_vent_req, base-type=uint8, implementation-data-type=uint8, transfer-property=PENDING
          signal CAN2_Perd_V2L: start 3, 4 bit, big-endian, i-signal-type=PRIMITIVE, init-value=constant-reference=Init_CAN2_Perd_V2L, base-type=uint8, implementation-data-type=uint8, transfer-property=PENDING
          signal CAN2_Pressure_unit: start 263, 8 bit, big-endian, i-signal-type=PRIMITIVE, init-value=constant-reference=Init_CAN2_Pressure_unit, base-type=uint8, implementation-data-type=uint8, transfer-property=PENDING
          signal CAN2_RCTA_BUTT: start 396, 2 bit, big-endian, i-signal-type=PRIMITIVE, init-value=constant-reference=Init_CAN2_RCTA_BUTT, base-type=uint8, implementation-data-type=uint8, transfer-property=PENDING
          signal CAN2_RFogLampSW: start 343, 1 bit, big-endian, i-signal-type=PRIMITIVE, init-value=constant-reference=Init_CAN2_RFogLampSW, base-type=uint8, implementation-data-type=uint8, transfer-property=PENDING
          signal CAN2_Roll_Eng_Mode: start 478, 1 bit, big-endian, i-signal-type=PRIMITIVE, init-value=constant-reference=Init_CAN2_Roll_Eng_Mode, base-type=uint8, implementation-data-type=uint8, transfer-property=TRIGGERED-ON-CHANGE
          signal CAN2_Roll_Mode_SW_Cmd: start 473, 2 bit, big-endian, i-signal-type=PRIMITIVE, init-value=constant-reference=Init_CAN2_Roll_Mode_SW_Cmd, base-type=uint8, implementation-data-type=uint8, transfer-property=TRIGGERED-ON-CHANGE
          signal CAN2_RoomLampMode: start 455, 1 bit, big-endian, i-signal-type=PRIMITIVE, init-value=constant-reference=Init_CAN2_RoomLampMode, base-type=uint8, implementation-data-type=uint8, transfer-property=PENDING
          signal CAN2_SLG_Sw: start 349, 2 bit, big-endian, i-signal-type=PRIMITIVE, init-value=constant-reference=Init_CAN2_SLG_Sw, base-type=uint8, implementation-data-type=uint8, transfer-property=PENDING
          signal CAN2_SLIF_BUTT: start 477, 2 bit, big-endian, i-signal-type=PRIMITIVE, init-value=constant-reference=Init_CAN2_SLIF_BUTT, base-type=uint8, implementation-data-type=uint8, transfer-property=TRIGGERED-ON-CHANGE
          signal CAN2_SOC_ADJ_BUTT: start 471, 1 bit, big-endian, i-signal-type=PRIMITIVE, init-value=constant-reference=Init_CAN2_SOC_ADJ_BUTT, base-type=uint8, implementation-data-type=uint8, transfer-property=TRIGGERED-ON-CHANGE
          signal CAN2_SOC_Limit_Set: start 468, 5 bit, big-endian, i-signal-type=PRIMITIVE, init-value=constant-reference=Init_CAN2_SOC_Limit_Set, base-type=uint8, implementation-data-type=uint8, transfer-property=PENDING
          signal CAN2_SOC_V2LLimit: start 7, 4 bit, big-endian, i-signal-type=PRIMITIVE, init-value=constant-reference=Init_CAN2_SOC_V2LLimit, base-type=uint8, implementation-data-type=uint8, transfer-property=PENDING
          signal CAN2_Sched_Chg_Start: start 92, 1 bit, big-endian, i-signal-type=PRIMITIVE, init-value=constant-reference=Init_CAN2_Sched_Chg_Start, base-type=uint8, implementation-data-type=uint8, transfer-property=TRIGGERED-ON-CHANGE
          signal CAN2_Sched_Chg_Stop: start 95, 1 bit, big-endian, i-signal-type=PRIMITIVE, init-value=constant-reference=Init_CAN2_Sched_Chg_Stop, base-type=uint8, implementation-data-type=uint8, transfer-property=TRIGGERED-ON-CHANGE
          signal CAN2_Sched_Chg_butt: start 94, 1 bit, big-endian, i-signal-type=PRIMITIVE, init-value=constant-reference=Init_CAN2_Sched_Chg_butt, base-type=uint8, implementation-data-type=uint8, transfer-property=PENDING
          signal CAN2_Sched_Chg_limit: start 84, 5 bit, big-endian, i-signal-type=PRIMITIVE, init-value=constant-reference=Init_CAN2_Sched_Chg_limit, base-type=uint8, implementation-data-type=uint8, transfer-property=PENDING
          signal CAN2_Sched_Chg_wake: start 93, 1 bit, big-endian, i-signal-type=PRIMITIVE, init-value=constant-reference=Init_CAN2_Sched_Chg_wake, base-type=uint8, implementation-data-type=uint8, transfer-property=TRIGGERED-ON-CHANGE
          signal CAN2_SenstivityPosition: start 403, 4 bit, big-endian, i-signal-type=PRIMITIVE, init-value=constant-reference=Init_CAN2_SenstivityPosition, base-type=uint8, implementation-data-type=uint8, transfer-property=PENDING
          signal CAN2_SetUnlockSingle: start 359, 1 bit, big-endian, i-signal-type=PRIMITIVE, init-value=constant-reference=Init_CAN2_SetUnlockSingle, base-type=uint8, implementation-data-type=uint8, transfer-property=PENDING
          signal CAN2_TCS_SW_Cmd: start 475, 2 bit, big-endian, i-signal-type=PRIMITIVE, init-value=constant-reference=Init_CAN2_TCS_SW_Cmd, base-type=uint8, implementation-data-type=uint8, transfer-property=TRIGGERED-ON-CHANGE
          signal CAN2_TPMS_Cali_Butt: start 127, 1 bit, big-endian, i-signal-type=PRIMITIVE, init-value=constant-reference=Init_CAN2_TPMS_Cali_Butt, base-type=uint8, implementation-data-type=uint8, transfer-property=PENDING
          signal CAN2_TPMS_Res_Butt: start 357, 1 bit, big-endian, i-signal-type=PRIMITIVE, init-value=constant-reference=Init_CAN2_TPMS_Res_Butt, base-type=uint8, implementation-data-type=uint8, transfer-property=PENDING
          signal CAN2_Temperature_unit: start 242, 1 bit, big-endian, i-signal-type=PRIMITIVE, init-value=constant-reference=Init_CAN2_Temperature_unit, base-type=uint8, implementation-data-type=uint8, transfer-property=PENDING
          signal CAN2_Time_system: start 255, 8 bit, big-endian, i-signal-type=PRIMITIVE, init-value=constant-reference=Init_CAN2_Time_system, base-type=uint8, implementation-data-type=uint8, transfer-property=PENDING
          signal CAN2_TurnSwTimeSet: start 271, 2 bit, big-endian, i-signal-type=PRIMITIVE, init-value=constant-reference=Init_CAN2_TurnSwTimeSet, base-type=uint8, implementation-data-type=uint8, transfer-property=TRIGGERED-ON-CHANGE
          signal CAN2_User_p_download: start 335, 1 bit, big-endian, i-signal-type=PRIMITIVE, init-value=constant-reference=Init_CAN2_User_p_download, base-type=uint8, implementation-data-type=uint8, transfer-property=PENDING
          signal CAN2_User_p_upload: start 285, 1 bit, big-endian, i-signal-type=PRIMITIVE, init-value=constant-reference=Init_CAN2_User_p_upload, base-type=uint8, implementation-data-type=uint8, transfer-property=PENDING
          signal CAN2_Walkaway_Lock_SW: start 8, 1 bit, big-endian, i-signal-type=PRIMITIVE, init-value=constant-reference=Init_CAN2_Walkaway_Lock_SW, base-type=uint8, implementation-data-type=uint8, transfer-property=TRIGGERED-ON-CHANGE
          signal CAN2_Wifi_Reset: start 287, 1 bit, big-endian, i-signal-type=PRIMITIVE, init-value=constant-reference=Init_CAN2_Wifi_Reset, base-type=uint8, implementation-data-type=uint8, transfer-property=PENDING
          signal CAN2_Wifi_Sta_IVI_TBOX: start 327, 4 bit, big-endian, i-signal-type=PRIMITIVE, init-value=constant-reference=Init_CAN2_Wifi_Sta_IVI_TBOX, base-type=uint8, implementation-data-type=uint8, transfer-property=PENDING
          signal CAN2_sigAirIntenZon1Req: start 223, 4 bit, big-endian, i-signal-type=PRIMITIVE, init-value=constant-reference=Init_CAN2_sigAirIntenZon1Req, base-type=uint8, implementation-data-type=uint8, transfer-property=TRIGGERED-ON-CHANGE
          signal CAN2_sigAirIntenZon3Req: start 219, 4 bit, big-endian, i-signal-type=PRIMITIVE, init-value=constant-reference=Init_CAN2_sigAirIntenZon3Req, base-type=uint8, implementation-data-type=uint8, transfer-property=TRIGGERED-ON-CHANGE
          signal CAN2_sigDfrstReq: start 199, 1 bit, big-endian, i-signal-type=PRIMITIVE, init-value=constant-reference=Init_CAN2_sigDfrstReq, base-type=uint8, implementation-data-type=uint8, transfer-property=TRIGGERED-ON-CHANGE
          signal CAN2_sigFaceReq: start 91, 1 bit, big-endian, i-signal-type=PRIMITIVE, init-value=constant-reference=Init_CAN2_sigFaceReq, base-type=uint8, implementation-data-type=uint8, transfer-property=TRIGGERED-ON-CHANGE
          signal CAN2_sigFootReq: start 90, 1 bit, big-endian, i-signal-type=PRIMITIVE, init-value=constant-reference=Init_CAN2_sigFootReq, base-type=uint8, implementation-data-type=uint8, transfer-property=TRIGGERED-ON-CHANGE
          signal CAN2_sigHvacFrontReq: start 198, 1 bit, big-endian, i-signal-type=PRIMITIVE, init-value=constant-reference=Init_CAN2_sigHvacFrontReq, base-type=uint8, implementation-data-type=uint8, transfer-property=TRIGGERED-ON-CHANGE
          signal CAN2_sigHvacRearReq: start 247, 1 bit, big-endian, i-signal-type=PRIMITIVE, init-value=constant-reference=Init_CAN2_sigHvacRearReq, base-type=uint8, implementation-data-type=uint8, transfer-property=TRIGGERED-ON-CHANGE
          signal CAN2_sigHvacReq: start 207, 1 bit, big-endian, i-signal-type=PRIMITIVE, init-value=constant-reference=Init_CAN2_sigHvacReq, base-type=uint8, implementation-data-type=uint8, transfer-property=TRIGGERED-ON-CHANGE
          signal CAN2_sigRecircReq: start 206, 1 bit, big-endian, i-signal-type=PRIMITIVE, init-value=constant-reference=Init_CAN2_sigRecircReq, base-type=uint8, implementation-data-type=uint8, transfer-property=TRIGGERED-ON-CHANGE
          signal CAN2_sigSetTempZon1Req: start 197, 6 bit, big-endian, i-signal-type=PRIMITIVE, init-value=constant-reference=Init_CAN2_sigSetTempZon1Req, base-type=uint8, implementation-data-type=uint8, transfer-property=TRIGGERED-ON-CHANGE
          signal CAN2_sigSetTempZon2Req: start 205, 6 bit, big-endian, i-signal-type=PRIMITIVE, init-value=constant-reference=Init_CAN2_sigSetTempZon2Req, base-type=uint8, implementation-data-type=uint8, transfer-property=TRIGGERED-ON-CHANGE
          signal CAN2_sigSetTempZon3Req: start 215, 6 bit, big-endian, i-signal-type=PRIMITIVE, init-value=constant-reference=Init_CAN2_sigSetTempZon3Req, base-type=uint8, implementation-data-type=uint8, transfer-property=TRIGGERED-ON-CHANGE
          signal CAN2_sigWindDirZon3Req: start 228, 3 bit, big-endian, i-signal-type=PRIMITIVE, init-value=constant-reference=Init_CAN2_sigWindDirZon3Req, base-type=uint8, implementation-data-type=uint8, transfer-property=TRIGGERED-ON-CHANGE
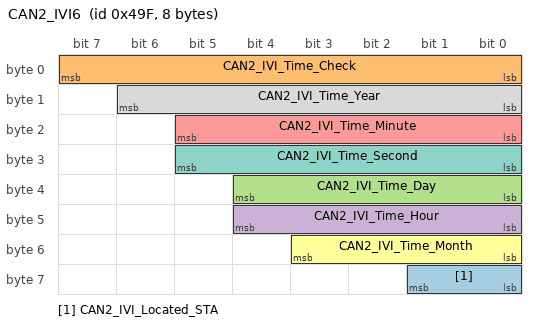
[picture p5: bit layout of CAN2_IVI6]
      frame CAN2_IVI6: id 0x49F, frame-length=8, can-addressing-mode=STANDARD, can-fd-frame-support=true, can-frame-rx-behavior=CAN-FD, can-frame-tx-behavior=CAN-FD
        pdu CAN2_IVI6: length=8, minimum-delay=0.0, transmission-mode-true-timing=cyclic-timing=time-period=1, unused-bit-pattern=0
          mapping CAN2_SG_IVI6: i-signal-group=CAN2_SG_IVI6, start-position=0, transfer-property=PENDING
          signal CAN2_IVI_Located_STA: start 57, 2 bit, big-endian, i-signal-type=PRIMITIVE, init-value=constant-reference=Init_CAN2_IVI_Located_STA, base-type=uint8, implementation-data-type=uint8, transfer-property=PENDING
          signal CAN2_IVI_Time_Check: start 7, 8 bit, big-endian, i-signal-type=PRIMITIVE, init-value=constant-reference=Init_CAN2_IVI_Time_Check, base-type=uint8, implementation-data-type=uint8, transfer-property=PENDING
          signal CAN2_IVI_Time_Day: start 36, 5 bit, big-endian, i-signal-type=PRIMITIVE, init-value=constant-reference=Init_CAN2_IVI_Time_Day, base-type=uint8, implementation-data-type=uint8, transfer-property=PENDING
          signal CAN2_IVI_Time_Hour: start 44, 5 bit, big-endian, i-signal-type=PRIMITIVE, init-value=constant-reference=Init_CAN2_IVI_Time_Hour, base-type=uint8, implementation-data-type=uint8, transfer-property=PENDING
          signal CAN2_IVI_Time_Minute: start 21, 6 bit, big-endian, i-signal-type=PRIMITIVE, init-value=constant-reference=Init_CAN2_IVI_Time_Minute, base-type=uint8, implementation-data-type=uint8, transfer-property=PENDING
          signal CAN2_IVI_Time_Month: start 51, 4 bit, big-endian, i-signal-type=PRIMITIVE, init-value=constant-reference=Init_CAN2_IVI_Time_Month, base-type=uint8, implementation-data-type=uint8, transfer-property=PENDING
          signal CAN2_IVI_Time_Second: start 29, 6 bit, big-endian, i-signal-type=PRIMITIVE, init-value=constant-reference=Init_CAN2_IVI_Time_Second, base-type=uint8, implementation-data-type=uint8, transfer-property=PENDING
          signal CAN2_IVI_Time_Year: start 14, 7 bit, big-endian, i-signal-type=PRIMITIVE, init-value=constant-reference=Init_CAN2_IVI_Time_Year, base-type=uint8, implementation-data-type=uint8, transfer-property=PENDING
      frame CAN2_METER1: id 0x25A, frame-length=24, can-addressing-mode=STANDARD, can-fd-frame-support=true, can-frame-rx-behavior=CAN-FD, can-frame-tx-behavior=CAN-FD
        pdu CAN2_METER1: length=24, minimum-delay=0.0, transmission-mode-true-timing={cyclic-timing=time-period=0.1, event-controlled-timing={number-of-repetitions=0, repetition-period=0.01}}, unused-bit-pattern=0
          mapping CAN2_SG_METER1: i-signal-group=CAN2_SG_METER1, start-position=0, transfer-property=TRIGGERED-ON-CHANGE
          signal CAN2_APCforDTE: start 87, 16 bit, big-endian, i-signal-type=PRIMITIVE, init-value=constant-reference=Init_CAN2_APCforDTE, base-type=uint16, implementation-data-type=uint16, transfer-property=PENDING
          signal CAN2_AVGPwrConsumption: start 71, 16 bit, big-endian, i-signal-type=PRIMITIVE, init-value=constant-reference=Init_CAN2_AVGPwrConsumption, base-type=uint16, implementation-data-type=uint16, transfer-property=PENDING
          signal CAN2_AvailableTrip: start 103, 16 bit, big-endian, i-signal-type=PRIMITIVE, init-value=constant-reference=Init_CAN2_AvailableTrip, base-type=uint16, implementation-data-type=uint16, transfer-property=PENDING
          signal CAN2_Averaged_vehspeed: start 49, 10 bit, big-endian, i-signal-type=PRIMITIVE, init-value=constant-reference=Init_CAN2_Averaged_vehspeed, base-type=uint16, implementation-data-type=uint16, transfer-property=PENDING
          signal CAN2_Charge: start 113, 1 bit, big-endian, i-signal-type=PRIMITIVE, init-value=constant-reference=Init_CAN2_Charge, base-type=uint8, implementation-data-type=uint8, transfer-property=TRIGGERED-ON-CHANGE
          signal CAN2_LEDlitWarnReq: start 114, 1 bit, big-endian, i-signal-type=PRIMITIVE, init-value=constant-reference=Init_CAN2_LEDlitWarnReq, base-type=uint8, implementation-data-type=uint8, transfer-property=TRIGGERED-ON-CHANGE
          signal CAN2_METER_KPH_Calcu: start 15, 8 bit, big-endian, i-signal-type=PRIMITIVE, init-value=constant-reference=Init_CAN2_METER_KPH_Calcu, base-type=uint8, implementation-data-type=uint8, transfer-property=PENDING
          signal CAN2_METER_KPH_Real: start 31, 12 bit, big-endian, i-signal-type=PRIMITIVE, init-value=constant-reference=Init_CAN2_METER_KPH_Real, base-type=uint16, implementation-data-type=uint16, transfer-property=PENDING
          signal CAN2_METER_MPH_Calcu: start 23, 8 bit, big-endian, i-signal-type=PRIMITIVE, init-value=constant-reference=Init_CAN2_METER_MPH_Calcu, base-type=uint8, implementation-data-type=uint8, transfer-property=PENDING
          signal CAN2_METER_MPH_Real: start 35, 12 bit, big-endian, i-signal-type=PRIMITIVE, init-value=constant-reference=Init_CAN2_METER_MPH_Real, base-type=uint16, implementation-data-type=uint16, transfer-property=PENDING
          signal CAN2_ODOMETER: start 175, 24 bit, big-endian, i-signal-type=PRIMITIVE, init-value=constant-reference=Init_CAN2_ODOMETER, base-type=uint32, implementation-data-type=uint32, transfer-property=TRIGGERED-ON-CHANGE
          signal CAN2_ParkBrake: start 112, 1 bit, big-endian, i-signal-type=PRIMITIVE, init-value=constant-reference=Init_CAN2_ParkBrake, base-type=uint8, implementation-data-type=uint8, transfer-property=TRIGGERED-ON-CHANGE
          signal CAN2_Spd_Crl_Mode: start 118, 3 bit, big-endian, i-signal-type=PRIMITIVE, init-value=constant-reference=Init_CAN2_Spd_Crl_Mode, base-type=uint8, implementation-data-type=uint8, transfer-property=PENDING
          signal CAN2_Spd_Crl_Sta: start 115, 1 bit, big-endian, i-signal-type=PRIMITIVE, init-value=constant-reference=Init_CAN2_Spd_Crl_Sta, base-type=uint8, implementation-data-type=uint8, transfer-property=PENDING
          signal CAN2_Trip_A: start 151, 24 bit, big-endian, i-signal-type=PRIMITIVE, init-value=constant-reference=Init_CAN2_Trip_A, base-type=uint32, implementation-data-type=uint32, transfer-property=TRIGGERED-ON-CHANGE
          signal CAN2_Trip_B: start 127, 24 bit, big-endian, i-signal-type=PRIMITIVE, init-value=constant-reference=Init_CAN2_Trip_B, base-type=uint32, implementation-data-type=uint32, transfer-property=TRIGGERED-ON-CHANGE
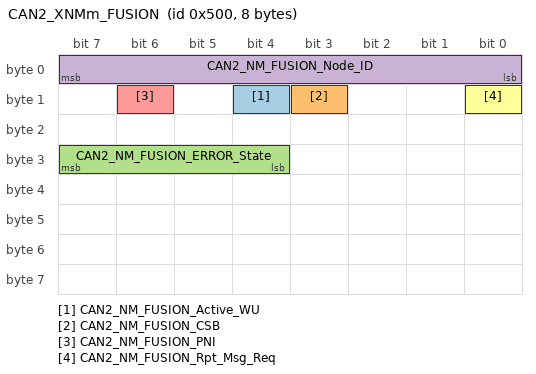
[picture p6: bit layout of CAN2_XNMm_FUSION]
      frame CAN2_XNMm_FUSION: id 0x500, frame-length=8, can-addressing-mode=STANDARD, can-fd-frame-support=false, can-frame-rx-behavior=CAN-20, can-frame-tx-behavior=CAN-20
        pdu CAN2_XNMm_FUSION: length=8, minimum-delay=0.0, transmission-mode-true-timing=cyclic-timing=time-period=0.7, unused-bit-pattern=0
          mapping CAN2_SG_XNMm_FUSION: i-signal-group=CAN2_SG_XNMm_FUSION, start-position=0, transfer-property=PENDING
          signal CAN2_NM_FUSION_Active_WU: start 12, 1 bit, big-endian, i-signal-type=PRIMITIVE, init-value=constant-reference=Init_CAN2_NM_FUSION_Active_WU, base-type=uint8, implementation-data-type=uint8, transfer-property=PENDING
          signal CAN2_NM_FUSION_CSB: start 11, 1 bit, big-endian, i-signal-type=PRIMITIVE, init-value=constant-reference=Init_CAN2_NM_FUSION_CSB, base-type=uint8, implementation-data-type=uint8, transfer-property=PENDING
          signal CAN2_NM_FUSION_ERROR_State: start 31, 4 bit, big-endian, i-signal-type=PRIMITIVE, init-value=constant-reference=Init_CAN2_NM_FUSION_ERROR_State, base-type=uint8, implementation-data-type=uint8, transfer-property=PENDING
          signal CAN2_NM_FUSION_Node_ID: start 7, 8 bit, big-endian, i-signal-type=PRIMITIVE, init-value=constant-reference=Init_CAN2_NM_FUSION_Node_ID, base-type=uint8, implementation-data-type=uint8, transfer-property=PENDING
          signal CAN2_NM_FUSION_PNI: start 14, 1 bit, big-endian, i-signal-type=PRIMITIVE, init-value=constant-reference=Init_CAN2_NM_FUSION_PNI, base-type=uint8, implementation-data-type=uint8, transfer-property=PENDING
          signal CAN2_NM_FUSION_Rpt_Msg_Req: start 8, 1 bit, big-endian, i-signal-type=PRIMITIVE, init-value=constant-reference=Init_CAN2_NM_FUSION_Rpt_Msg_Req, base-type=uint8, implementation-data-type=uint8, transfer-property=PENDING
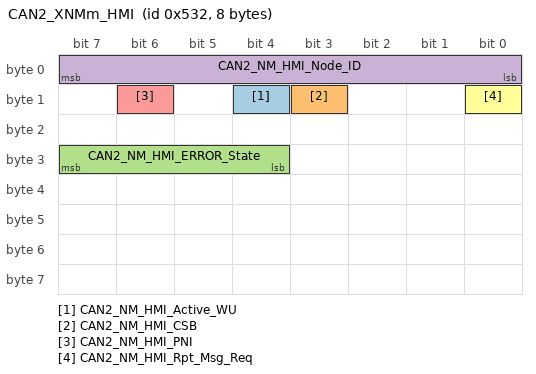
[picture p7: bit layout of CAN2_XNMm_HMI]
      frame CAN2_XNMm_HMI: id 0x532, frame-length=8, can-addressing-mode=STANDARD, can-fd-frame-support=false, can-frame-rx-behavior=CAN-20, can-frame-tx-behavior=CAN-20
        pdu CAN2_XNMm_HMI: length=8, minimum-delay=0.0, transmission-mode-true-timing=cyclic-timing=time-period=0.7, unused-bit-pattern=0
          mapping CAN2_SG_XNMm_HMI: i-signal-group=CAN2_SG_XNMm_HMI, start-position=0, transfer-property=PENDING
          signal CAN2_NM_HMI_Active_WU: start 12, 1 bit, big-endian, i-signal-type=PRIMITIVE, init-value=constant-reference=Init_CAN2_NM_HMI_Active_WU, base-type=uint8, implementation-data-type=uint8, transfer-property=PENDING
          signal CAN2_NM_HMI_CSB: start 11, 1 bit, big-endian, i-signal-type=PRIMITIVE, init-value=constant-reference=Init_CAN2_NM_HMI_CSB, base-type=uint8, implementation-data-type=uint8, transfer-property=PENDING
          signal CAN2_NM_HMI_ERROR_State: start 31, 4 bit, big-endian, i-signal-type=PRIMITIVE, init-value=constant-reference=Init_CAN2_NM_HMI_ERROR_State, base-type=uint8, implementation-data-type=uint8, transfer-property=PENDING
          signal CAN2_NM_HMI_Node_ID: start 7, 8 bit, big-endian, i-signal-type=PRIMITIVE, init-value=constant-reference=Init_CAN2_NM_HMI_Node_ID, base-type=uint8, implementation-data-type=uint8, transfer-property=PENDING
          signal CAN2_NM_HMI_PNI: start 14, 1 bit, big-endian, i-signal-type=PRIMITIVE, init-value=constant-reference=Init_CAN2_NM_HMI_PNI, base-type=uint8, implementation-data-type=uint8, transfer-property=PENDING
          signal CAN2_NM_HMI_Rpt_Msg_Req: start 8, 1 bit, big-endian, i-signal-type=PRIMITIVE, init-value=constant-reference=Init_CAN2_NM_HMI_Rpt_Msg_Req, base-type=uint8, implementation-data-type=uint8, transfer-property=PENDING
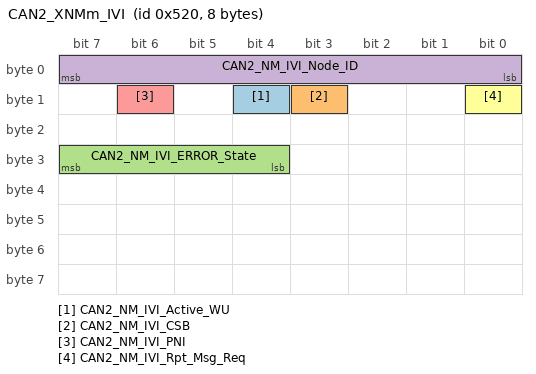
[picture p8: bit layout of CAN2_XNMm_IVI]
      frame CAN2_XNMm_IVI: id 0x520, frame-length=8, can-addressing-mode=STANDARD, can-fd-frame-support=false, can-frame-rx-behavior=CAN-20, can-frame-tx-behavior=CAN-20
        pdu CAN2_XNMm_IVI: length=8, minimum-delay=0.0, transmission-mode-true-timing=cyclic-timing=time-period=0.7, unused-bit-pattern=0
          mapping CAN2_SG_XNMm_IVI: i-signal-group=CAN2_SG_XNMm_IVI, start-position=0, transfer-property=PENDING
          signal CAN2_NM_IVI_Active_WU: start 12, 1 bit, big-endian, i-signal-type=PRIMITIVE, init-value=constant-reference=Init_CAN2_NM_IVI_Active_WU, base-type=uint8, implementation-data-type=uint8, transfer-property=PENDING
          signal CAN2_NM_IVI_CSB: start 11, 1 bit, big-endian, i-signal-type=PRIMITIVE, init-value=constant-reference=Init_CAN2_NM_IVI_CSB, base-type=uint8, implementation-data-type=uint8, transfer-property=PENDING
          signal CAN2_NM_IVI_ERROR_State: start 31, 4 bit, big-endian, i-signal-type=PRIMITIVE, init-value=constant-reference=Init_CAN2_NM_IVI_ERROR_State, base-type=uint8, implementation-data-type=uint8, transfer-property=PENDING
          signal CAN2_NM_IVI_Node_ID: start 7, 8 bit, big-endian, i-signal-type=PRIMITIVE, init-value=constant-reference=Init_CAN2_NM_IVI_Node_ID, base-type=uint8, implementation-data-type=uint8, transfer-property=PENDING
          signal CAN2_NM_IVI_PNI: start 14, 1 bit, big-endian, i-signal-type=PRIMITIVE, init-value=constant-reference=Init_CAN2_NM_IVI_PNI, base-type=uint8, implementation-data-type=uint8, transfer-property=PENDING
          signal CAN2_NM_IVI_Rpt_Msg_Req: start 8, 1 bit, big-endian, i-signal-type=PRIMITIVE, init-value=constant-reference=Init_CAN2_NM_IVI_Rpt_Msg_Req, base-type=uint8, implementation-data-type=uint8, transfer-property=PENDING
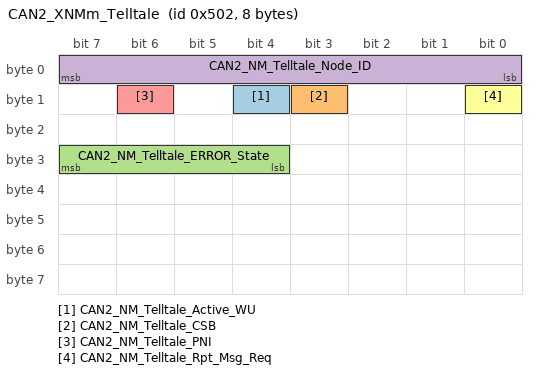
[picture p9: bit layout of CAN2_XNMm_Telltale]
      frame CAN2_XNMm_Telltale: id 0x502, frame-length=8, can-addressing-mode=STANDARD, can-fd-frame-support=false, can-frame-rx-behavior=CAN-20, can-frame-tx-behavior=CAN-20
        pdu CAN2_XNMm_Telltale: length=8, minimum-delay=0.0, transmission-mode-true-timing=cyclic-timing=time-period=0.7, unused-bit-pattern=0
          mapping CAN2_SG_XNMm_Telltale: i-signal-group=CAN2_SG_XNMm_Telltale, start-position=0, transfer-property=PENDING
          signal CAN2_NM_Telltale_Active_WU: start 12, 1 bit, big-endian, i-signal-type=PRIMITIVE, init-value=constant-reference=Init_CAN2_NM_Telltale_Active_WU, base-type=uint8, implementation-data-type=uint8, transfer-property=PENDING
          signal CAN2_NM_Telltale_CSB: start 11, 1 bit, big-endian, i-signal-type=PRIMITIVE, init-value=constant-reference=Init_CAN2_NM_Telltale_CSB, base-type=uint8, implementation-data-type=uint8, transfer-property=PENDING
          signal CAN2_NM_Telltale_ERROR_State: start 31, 4 bit, big-endian, i-signal-type=PRIMITIVE, init-value=constant-reference=Init_CAN2_NM_Telltale_ERROR_State, base-type=uint8, implementation-data-type=uint8, transfer-property=PENDING
          signal CAN2_NM_Telltale_Node_ID: start 7, 8 bit, big-endian, i-signal-type=PRIMITIVE, init-value=constant-reference=Init_CAN2_NM_Telltale_Node_ID, base-type=uint8, implementation-data-type=uint8, transfer-property=PENDING
          signal CAN2_NM_Telltale_PNI: start 14, 1 bit, big-endian, i-signal-type=PRIMITIVE, init-value=constant-reference=Init_CAN2_NM_Telltale_PNI, base-type=uint8, implementation-data-type=uint8, transfer-property=PENDING
          signal CAN2_NM_Telltale_Rpt_Msg_Req: start 8, 1 bit, big-endian, i-signal-type=PRIMITIVE, init-value=constant-reference=Init_CAN2_NM_Telltale_Rpt_Msg_Req, base-type=uint8, implementation-data-type=uint8, transfer-property=PENDING
